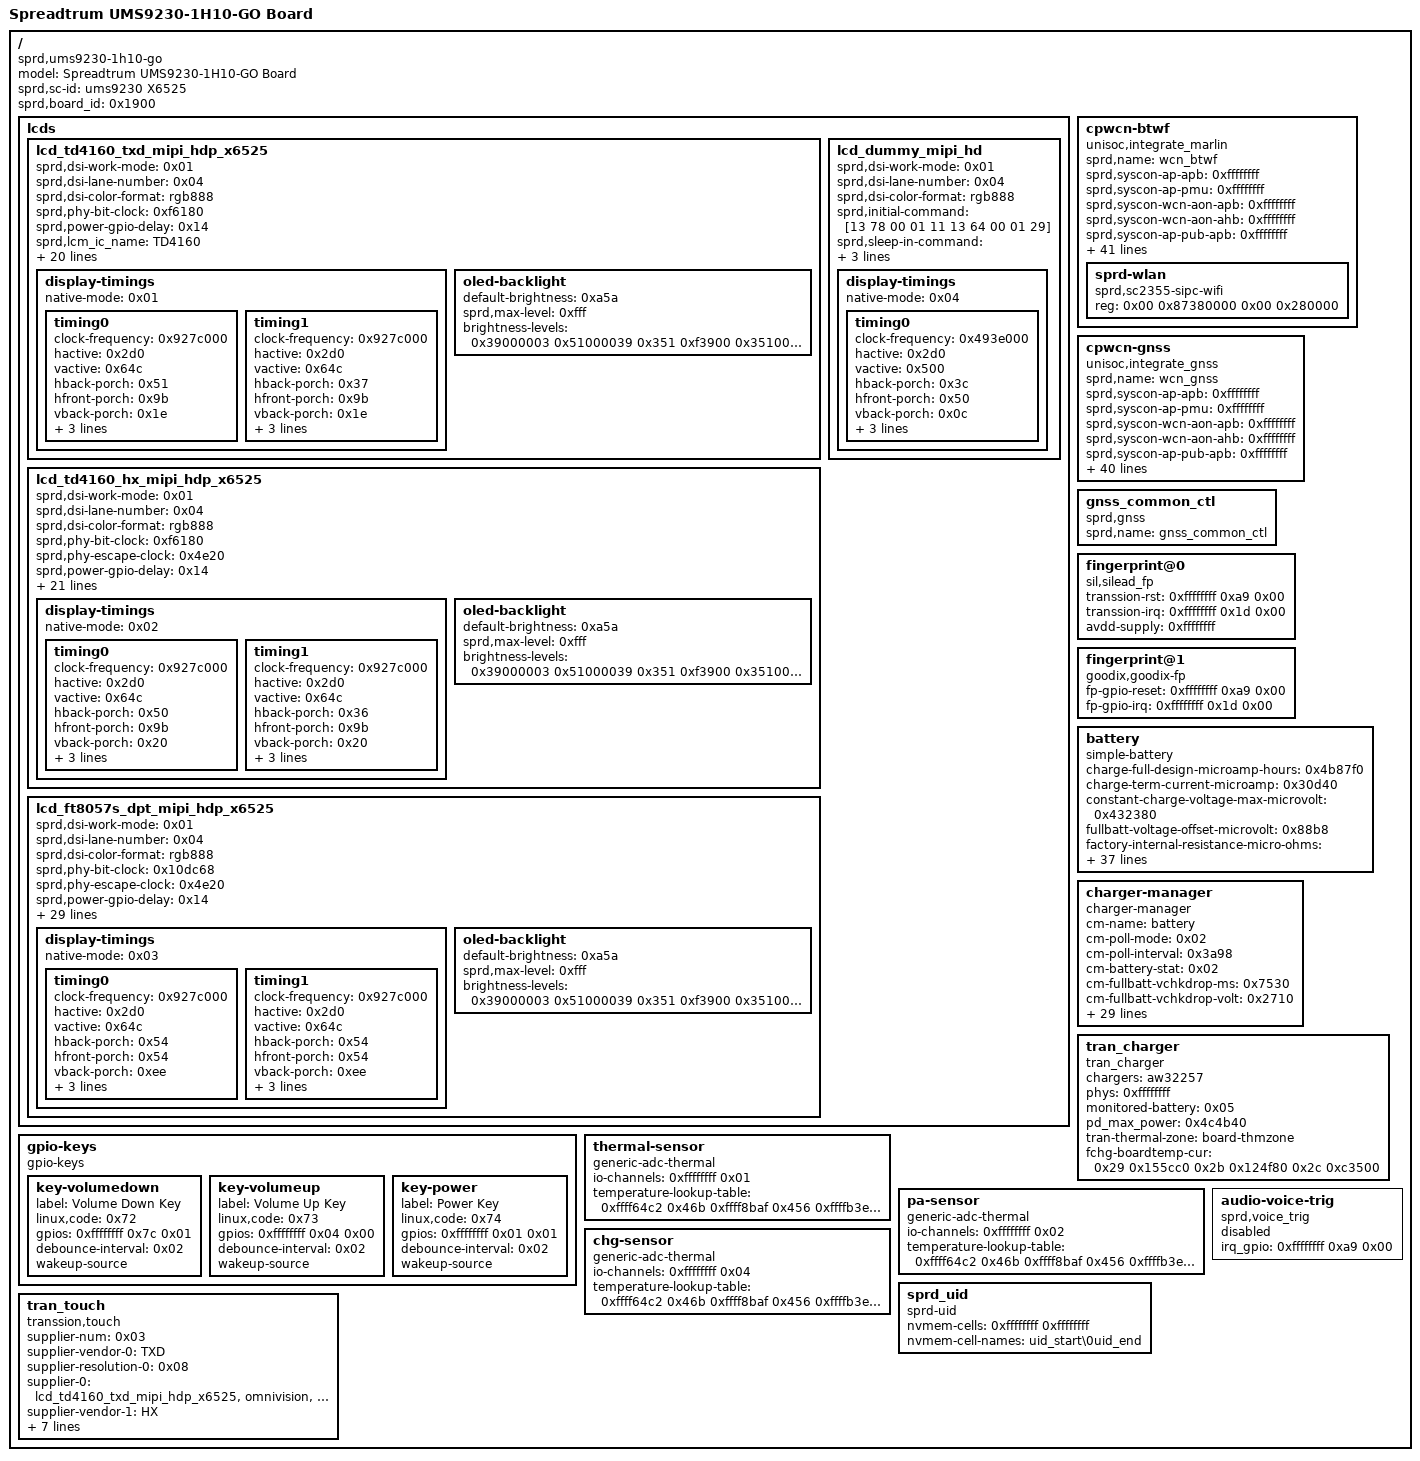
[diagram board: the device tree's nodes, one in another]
/dts-v1/;

/ {
	model = "Spreadtrum UMS9230-1H10-GO Board";
	compatible = "sprd,ums9230-1h10-go";
	sprd,sc-id = "ums9230 X6525";
	sprd,board_id = <0x1900>;

	fragment {
		target-path = "/";

		__overlay__ {
			#address-cells = <0x02>;
			#size-cells = <0x02>;

			lcds {

				lcd_td4160_txd_mipi_hdp_x6525 {
					sprd,dsi-work-mode = <0x01>;
					sprd,dsi-lane-number = <0x04>;
					sprd,dsi-color-format = "rgb888";
					sprd,phy-bit-clock = <0xf6180>;
					sprd,power-gpio-delay = <0x14>;
					sprd,lcm_ic_name = "TD4160";
					sprd,lcm_ic_vendor = "TXD";
					sprd,lcm_ic_inch = "6.56";
					sprd,width-mm = <0x44>;
					sprd,height-mm = <0x98>;
					sprd,esd-check-enable = <0x00>;
					sprd,esd-check-mode = <0x01>;
					sprd,esd-check-period = <0x7d0>;
					sprd,esd-check-register = <0x0a>;
					sprd,esd-check-value = <0x9c>;
					sprd,backlight-param-write = <0x01>;
					sprd,reset-on-sequence = <0x01 0x05 0x00 0x05 0x01 0x14>;
					sprd,reset-off-sequence = <0x00 0x05>;
					sprd,use-dcs-write;
					sprd,initial-command = [23 00 00 02 b0 00 39 00 00 07 b6 30 6a 00 86 c3 03 39 00 00 05 b7 31 00 00 00 39 00 00 07 b8 06 90 00 00 00 32 39 00 00 07 b9 06 90 00 00 00 80 39 00 00 07 ba 06 90 00 00 00 90 39 00 00 04 bb 00 b4 a0 39 00 00 04 bc 00 b4 a0 39 00 00 04 bd 00 b4 a0 39 00 00 0e be 07 00 00 00 00 00 00 00 00 00 00 00 00 39 00 00 19 c0 00 5a 22 06 4c 00 10 06 94 00 70 00 00 00 00 00 00 00 00 00 00 00 00 00 39 00 00 28 c1 30 81 50 fa 01 00 00 10 00 00 00 00 40 0f 00 00 00 00 00 00 00 00 00 00 00 00 00 00 00 00 00 00 00 00 00 00 00 00 00 39 00 00 f5 c2 04 c0 4c 14 05 10 08 00 00 00 00 00 00 00 00 00 00 00 00 00 00 00 00 00 00 00 00 00 00 00 00 00 00 00 00 00 00 00 00 00 00 00 04 c0 3d 0c 0c 05 00 41 00 46 69 03 00 64 00 00 00 00 00 11 00 00 00 00 00 00 00 00 00 00 00 00 04 c0 3d 0a 0a 05 00 01 66 a6 73 00 00 00 00 00 00 00 00 11 00 00 00 00 00 00 00 00 00 00 00 00 00 00 00 00 00 00 00 00 00 00 00 00 00 00 00 00 00 00 00 11 00 00 00 00 00 00 00 00 00 00 00 00 00 00 00 00 00 00 00 00 00 00 00 00 00 00 00 00 00 00 00 11 00 00 00 00 00 00 00 00 00 00 00 00 00 00 00 00 00 00 00 00 00 00 00 00 00 00 00 00 00 00 00 00 00 00 00 00 00 00 00 10 00 00 00 00 00 00 00 00 00 00 00 00 00 00 00 02 00 00 00 00 00 00 00 00 00 00 02 00 00 00 00 00 00 00 00 00 00 00 00 00 00 00 00 00 00 00 39 00 00 6a c3 00 00 00 c3 01 80 f8 3c f8 18 20 00 00 00 00 00 00 00 00 00 00 00 20 00 00 00 00 00 00 00 00 00 00 00 20 00 00 00 00 00 00 00 00 00 00 00 20 00 00 00 00 08 00 00 00 00 00 00 00 00 00 00 00 00 00 00 00 00 00 00 00 00 00 00 00 00 00 00 00 00 00 00 00 00 00 00 00 00 00 00 00 00 00 00 00 00 00 00 00 00 00 00 00 00 00 39 00 00 55 c4 00 07 07 2b 23 25 27 29 5d 61 13 15 17 19 1b 1d 03 05 00 00 00 00 00 00 00 00 00 00 06 04 1e 1c 1a 18 16 14 61 5d 2a 28 26 24 2c 07 07 00 00 00 00 00 00 00 00 00 00 00 00 00 00 00 00 00 00 00 00 00 00 00 00 00 00 00 00 55 55 55 55 55 55 55 55 55 55 55 39 00 00 06 c5 08 00 00 00 00 39 00 00 4d c6 00 00 00 00 01 22 04 22 01 00 5d 00 00 00 01 00 5d 00 01 05 01 0b 01 35 ff 8f 06 15 01 c0 0b 00 00 00 00 00 00 00 00 00 00 00 00 00 00 00 00 00 00 00 00 00 00 20 20 00 00 00 c0 11 00 00 00 10 10 00 00 00 01 00 50 00 33 03 00 00 39 00 00 1f cb 02 d0 01 80 00 00 00 00 00 00 00 00 00 00 00 00 00 00 00 00 00 00 40 70 00 00 00 00 00 ff 39 00 00 19 ce 5d 40 43 49 55 62 71 82 94 a8 b9 cb db e9 f5 fc ff 04 00 02 02 00 04 8c 23 00 00 02 cf 00 39 00 00 15 d0 c1 46 81 66 09 90 00 cc f2 ff 11 46 06 7e 09 08 cc 1b f0 06 39 00 00 26 d1 d4 d4 1b 33 33 17 07 bb 33 33 33 33 00 3b 77 07 3b 30 06 72 33 13 00 d7 0c 33 02 00 18 70 18 77 11 11 11 20 20 39 00 00 04 d2 00 00 00 39 00 00 9a d3 00 00 00 00 00 00 00 00 00 ff f7 ff ff f7 ff ff f7 ff ff f7 ff ff f7 ff ff f7 ff ff f7 ff ff f7 ff ff f7 ff ff f7 ff ff f7 ff ff f7 ff ff f7 ff ff f7 ff ff f7 ff ff f7 ff ff f7 ff ff f7 ff ff f7 ff ff f7 ff ff f7 ff ff f7 ff ff f7 ff ff f7 ff ff f7 ff ff f7 ff ff f7 ff ff f7 ff ff f7 ff ff f7 ff ff f7 ff ff f7 ff ff f7 ff ff f7 ff ff f7 ff ff f7 ff ff f7 ff ff f7 ff ff f7 ff ff f7 ff ff f7 ff ff f7 ff ff f7 ff ff f7 ff ff f7 ff ff f7 ff ff f7 ff ff f7 ff 39 00 00 18 d4 00 00 00 00 00 00 00 00 00 20 00 00 00 00 20 00 00 00 00 00 00 00 00 39 00 00 2f d7 29 00 12 12 00 5a 00 18 00 5a 00 18 03 83 80 85 85 85 87 84 45 86 87 80 88 86 89 83 83 87 84 88 8a 0c 0b 0a 0a 0a 07 07 06 06 00 08 0a 0a 39 00 00 17 d8 40 99 26 ed 16 6c 16 6c 16 6c 00 14 00 14 00 14 01 0c 00 00 01 00 39 00 00 29 d9 01 02 5e 00 00 20 00 00 00 00 00 00 00 00 00 c0 00 00 00 00 00 00 00 00 00 00 00 00 00 00 00 00 00 00 00 00 00 00 00 00 39 00 00 05 dd 30 06 23 65 39 00 00 0f de 00 00 00 0f ff 00 00 00 00 10 00 00 00 00 39 00 00 09 e6 00 00 00 00 00 00 00 00 39 00 00 24 ea 02 0e 0e 06 80 07 40 74 00 00 00 03 33 07 0a 00 5e 00 5e 00 5e 01 28 01 28 00 5e 00 5e 00 5e 00 0c 02 00 39 00 00 09 eb 09 00 90 00 01 00 01 01 39 00 00 18 ec 05 f0 01 70 6b 07 40 74 00 00 00 02 2a 00 00 00 00 00 00 00 00 00 00 39 00 00 22 ed 01 02 00 00 00 00 01 00 67 f7 0e 00 00 00 00 00 00 00 00 00 00 00 02 b0 00 00 00 00 00 00 c0 10 00 39 00 00 7a ee 05 00 55 00 c0 5f 00 c0 5f 00 00 03 00 00 03 00 c0 5f 00 00 00 00 00 c0 5f 00 00 00 00 00 00 03 00 00 00 00 00 00 03 00 00 00 00 00 00 03 00 c0 5f 00 00 00 00 00 00 03 00 00 00 00 00 00 03 00 00 00 00 00 00 03 00 00 00 00 00 00 03 00 00 03 00 00 03 00 00 03 00 00 03 00 00 03 00 00 03 00 00 00 00 00 00 00 00 00 00 00 00 00 00 00 00 00 00 00 00 00 00 00 00 00 02 23 00 00 02 b0 03 23 00 00 02 b0 04 23 00 00 02 b0 00 23 00 00 02 d6 00 23 00 00 02 b0 03 23 00 00 02 35 00 39 00 00 03 51 00 00 23 00 00 02 53 24 23 00 00 02 55 03 13 78 00 01 11 13 14 00 01 29];
					sprd,sleep-in-command = [39 14 00 03 28 00 00 39 78 00 03 10 00 00];
					sprd,sleep-out-command = [39 78 00 03 11 00 00 39 14 00 03 29 00 00];
					phandle = <0x13>;

					display-timings {
						native-mode = <0x01>;

						timing0 {
							clock-frequency = <0x927c000>;
							hactive = <0x2d0>;
							vactive = <0x64c>;
							hback-porch = <0x51>;
							hfront-porch = <0x9b>;
							vback-porch = <0x1e>;
							vfront-porch = <0x3fc>;
							hsync-len = <0x04>;
							vsync-len = <0x04>;
							phandle = <0x01>;
						};

						timing1 {
							clock-frequency = <0x927c000>;
							hactive = <0x2d0>;
							vactive = <0x64c>;
							hback-porch = <0x37>;
							hfront-porch = <0x9b>;
							vback-porch = <0x1e>;
							vfront-porch = <0xb4>;
							hsync-len = <0x04>;
							vsync-len = <0x04>;
							phandle = <0x14>;
						};
					};

					oled-backlight {
						default-brightness = <0xa5a>;
						sprd,max-level = <0xfff>;
						brightness-levels = <0x39000003 0x51000039 0x351 0xf3900 0x35100 0xf390000 0x351000f 0x39000003 0x51000f39 0x351 0xf3900 0x35100 0xf390000 0x351000f 0x39000003 0x51000f39 0x351 0xf3900 0x35100 0xf390000 0x351000f 0x39000003 0x51000f39 0x351 0xf3900 0x35100 0xf390000 0x351000f>;
					};
				};

				lcd_td4160_hx_mipi_hdp_x6525 {
					sprd,dsi-work-mode = <0x01>;
					sprd,dsi-lane-number = <0x04>;
					sprd,dsi-color-format = "rgb888";
					sprd,phy-bit-clock = <0xf6180>;
					sprd,phy-escape-clock = <0x4e20>;
					sprd,power-gpio-delay = <0x14>;
					sprd,lcm_ic_name = "TD4160";
					sprd,lcm_ic_vendor = "HX";
					sprd,lcm_ic_inch = "6.56";
					sprd,width-mm = <0x44>;
					sprd,height-mm = <0x98>;
					sprd,esd-check-enable = <0x00>;
					sprd,esd-check-mode = <0x01>;
					sprd,esd-check-period = <0x7d0>;
					sprd,esd-check-register = <0x0a>;
					sprd,esd-check-value = <0x9c>;
					sprd,backlight-param-write = <0x01>;
					sprd,reset-on-sequence = <0x01 0x05 0x00 0x05 0x01 0x14>;
					sprd,reset-off-sequence = <0x00 0x05>;
					sprd,use-dcs-write;
					sprd,initial-command = <0x23000002 0xb0003900 0x7b630 0x6a0086c3 0x3390000 0x5b73100 0x3900 0x7b806 0x90000000 0x32390000 0x7b90690 0x80 0x39000007 0xba069000 0x9039 0x4bb 0xb4a039 0x4bc 0xb4a039 0x4bd 0xb4a039 0xebe 0x7000000 0x00 0x00 0x390000 0x19c0005a 0x24064c00 0xa069400 0x70000000 0x00 0x00 0x3900 0x28c130 0x8150fa01 0x1000 0x40 0xf000000 0x00 0x00 0x00 0x00 0x00 0x3900 0xf5c205 0x304e1207 0x10141000 0x5304e12 0x7101210 0x00 0x00 0x00 0x00 0x00 0x00 0x53048 0x10100705 0xc100e002 0x08 0x00 0x1100e002 0x10000000 0x00 0x00 0x00 0x00 0x00 0x00 0x11000000 0x00 0x00 0x00 0x00 0x00 0x00 0x00 0x11000000 0x00 0x00 0x00 0x00 0x00 0x00 0x00 0x11000000 0x00 0x00 0x00 0x00 0x00 0x00 0x00 0x00 0x00 0x10000000 0x00 0x00 0x00 0x2000000 0x00 0x02 0x00 0x00 0x00 0x00 0x39 0x6ac3 0x5304ec1 0x1600c00 0x2000 0x5304ec1 0x1600c00 0x2002 0x5304ec1 0x1600c00 0x2001 0x5304ec1 0x1600c00 0x2000 0x08 0x00 0x00 0x00 0x00 0x00 0x00 0x00 0x00 0x00 0x00 0x00 0x00 0x00 0x390000 0x55c40000 0x5e610003 0x7131517 0x191b1d1f 0x215f6000 0x00 0x00 0x60 0x5f22201e 0x1c1a1816 0x14080400 0x615e0000 0x00 0xf00f00 0xff0000 0x00 0x00 0x00 0x55 0x55555555 0x55555555 0x55553900 0x6c508 0x00 0x3900004d 0xc6000000 0x12204 0x22010046 0x01 0x460001 0x5010b01 0x35ff0f06 0xc502c00f 0x00 0x00 0x00 0x00 0x00 0x2020 0xc0 0x11000000 0x10100000 0x10050 0x330300 0x390000 0x1fcb02d0 0x1800000 0x00 0x00 0x00 0x00 0x40700000 0xff 0x39000019 0xce5d4043 0x49556271 0x8294a8b9 0xcbdbe9f5 0xfcff0400 0x2020004 0x8c230000 0x2cf0039 0x15d0 0xc1328166 0x99000d5 0x929f1146 0x67e0908 0xdc1bf006 0x39000026 0xd1d8d81b 0x33331707 0xbb333333 0x33003b77 0x73b3006 0x72331300 0xd70c3302 0x187018 0x77111111 0x20203900 0x4d200 0x3900 0x9ad300 0x00 0x00 0xfff7ffff 0xf7fffff7 0xfffff7ff 0xfff7ffff 0xf7fffff7 0xfffff7ff 0xfff7ffff 0xf7fffff7 0xfffff7ff 0xfff7ffff 0xf7fffff7 0xfffff7ff 0xfff7ffff 0xf7fffff7 0xfffff7ff 0xfff7ffff 0xf7fffff7 0xfffff7ff 0xfff7ffff 0xf7fffff7 0xfffff7ff 0xfff7ffff 0xf7fffff7 0xfffff7ff 0xfff7ffff 0xf7fffff7 0xfffff7ff 0xfff7ffff 0xf7fffff7 0xfffff7ff 0xfff7ffff 0xf7fffff7 0xfffff7ff 0xfff7ffff 0xf7fffff7 0xfffff7ff 0x39000018 0xd4000000 0x00 0x2000 0x20 0x00 0x00 0x3900002f 0xd7010012 0x12005a00 0x18005a00 0x18038380 0x85858587 0x84858687 0x80888689 0x83838784 0x88900c0b 0xa0a0a07 0x7060600 0x80a0a39 0x17d8 0x409926ed 0x166c166c 0x166c0014 0x140014 0x10c0000 0x1003900 0x29d901 0x27f2200 0x140000 0x00 0xc000 0x00 0x00 0x00 0x00 0x00 0x39 0x5dd 0x30062365 0x3900000f 0xde000000 0xfff0000 0x1000 0x39 0x9e6 0x00 0x00 0x39000024 0xea020707 0x4801001 0x00 0x3230007 0xed00ed 0xed0128 0x1280047 0x470047 0x10f0100 0x39000009 0xeb083083 0x10100 0x390000 0x18ec02d0 0x1707310 0x1000000 0x22a00 0x00 0x00 0x390000 0x22ed0102 0x00 0x67c6 0xfe000000 0x00 0x00 0x2b00000 0x00 0x40100039 0x7aee 0x5400100 0xc03f00c0 0x3f000003 0x300 0xc03f0000 0x00 0x3000000 0x03 0x00 0x300 0x00 0x340c5 0x3f000000 0xc03f 0x00 0xc03f00 0x05 0xc03f0000 0x00 0x3000003 0x300 0x30000 0x3000003 0x300 0x00 0x00 0x00 0x00 0x00 0x00 0x2230000 0x2b00323 0x2b0 0x4230000 0x2d60039 0x351 0x2300 0x25324 0x23000002 0x55031378 0x11113 0x14000129>;
					sprd,sleep-in-command = [13 14 00 01 28 13 78 00 01 10];
					sprd,sleep-out-command = [13 78 00 01 11 13 14 00 01 29];
					phandle = <0x15>;

					display-timings {
						native-mode = <0x02>;

						timing0 {
							clock-frequency = <0x927c000>;
							hactive = <0x2d0>;
							vactive = <0x64c>;
							hback-porch = <0x50>;
							hfront-porch = <0x9b>;
							vback-porch = <0x20>;
							vfront-porch = <0x3fc>;
							hsync-len = <0x04>;
							vsync-len = <0x04>;
							phandle = <0x02>;
						};

						timing1 {
							clock-frequency = <0x927c000>;
							hactive = <0x2d0>;
							vactive = <0x64c>;
							hback-porch = <0x36>;
							hfront-porch = <0x9b>;
							vback-porch = <0x20>;
							vfront-porch = <0xb4>;
							hsync-len = <0x04>;
							vsync-len = <0x04>;
							phandle = <0x16>;
						};
					};

					oled-backlight {
						default-brightness = <0xa5a>;
						sprd,max-level = <0xfff>;
						brightness-levels = <0x39000003 0x51000039 0x351 0xf3900 0x35100 0xf390000 0x351000f 0x39000003 0x51000f39 0x351 0xf3900 0x35100 0xf390000 0x351000f 0x39000003 0x51000f39 0x351 0xf3900 0x35100 0xf390000 0x351000f 0x39000003 0x51000f39 0x351 0xf3900 0x35100 0xf390000 0x351000f>;
					};
				};

				lcd_ft8057s_dpt_mipi_hdp_x6525 {
					sprd,dsi-work-mode = <0x01>;
					sprd,dsi-lane-number = <0x04>;
					sprd,dsi-color-format = "rgb888";
					sprd,phy-bit-clock = <0x10dc68>;
					sprd,phy-escape-clock = <0x4e20>;
					sprd,power-gpio-delay = <0x14>;
					sprd,lcm_ic_name = "FT8057S";
					sprd,lcm_ic_vendor = "DPT";
					sprd,lcm_ic_inch = "6.56";
					sprd,width-mm = <0x44>;
					sprd,height-mm = <0x99>;
					sprd,esd-check-enable = <0x01>;
					sprd,esd-check-mode = <0x02>;
					sprd,esd-check-period = <0x7d0>;
					sprd,esd-check-num = <0x03>;
					sprd,esd-check-register = <0x0a 0x0d 0x0b>;
					sprd,esd-check-value = <0x9c 0x00 0x00>;
					sprd,backlight-param-write = <0x00>;
					sprd,reset-on-sequence = <0x01 0x05 0x00 0x05 0x01 0x14>;
					sprd,reset-off-sequence = <0x01 0x05>;
					sprd,need-shutdown = <0x01>;
					sprd,shutdown-sequence = <0x00 0x00 0x00 0x32 0x00 0x05 0x36 0x00 0x01 0x37 0x00 0x05>;
					sprd,use-dcs-write;
					sprd,initial-command = <0x23000002 0x3900 0x4ff80 0x57012300 0x20080 0x39000003 0xff805723 0x200 0x390000 0x52a0000 0x2cf2300 0x20000 0x39000005 0x2b000006 0x4b230000 0x200a339 0x5b3 0x64c0018 0x23000002 0x932300 0x2c575 0x23000002 0x972300 0x2c575 0x23000002 0x9a2300 0x2c541 0x23000002 0x9c2300 0x2c541 0x23000002 0xb63900 0x3c561 0x61230000 0x200b839 0x3c5 0x37372300 0x20000 0x39000003 0xd8333323 0x200 0x82230000 0x2c55523 0x200 0x83230000 0x2c50723 0x200 0x96230000 0x2f50d23 0x200 0x86230000 0x2f50d23 0x200 0x94230000 0x2c51523 0x200 0x9b230000 0x2c55123 0x200 0xa3230000 0x2a50423 0x200 0x99230000 0x2cf5623 0x200 0x86230000 0x2b78023 0x200 0xa5230000 0x2b01d23 0x200 0x80390000 0x7c000d2 0x2e001c 0x23000002 0x903900 0x7c000 0x7f002e00 0x1c230000 0x200a039 0x7c0 0xd2002e 0x1c2300 0x200b0 0x39000006 0xc0010f00 0x2e1c2300 0x200c1 0x39000009 0xc0013301 0xa00cd01 0x8f230000 0x2007039 0x7c0 0x7f002e 0x1c2300 0x200a3 0x39000007 0xc1003300 0x3c000223 0x200 0xb7390000 0x3c10033 0x23000002 0x733900 0x3ce09 0x9230000 0x2008039 0x11ce 0x1810909 0x780096 0x780096 0x780096 0x23000002 0x903900 0x10ce00 0xa5168f00 0xa5800909 0x7d016 0x16172300 0x200a0 0x39000004 0xce200000 0x23000002 0xb03900 0x4ce87 0x2300 0x200d1 0x39000008 0xce000001 0x00 0x23000002 0xe13900 0xcce08 0x3c303c3 0x2b00000 0x2300 0x200f1 0x3900000a 0xce14141e 0x1520152 0x1532300 0x200b0 0x39000005 0xcf00006d 0x71230000 0x200b539 0x5cf 0x3035b5f 0x23000002 0xc03900 0x5cf06 0x6474b23 0x200 0xc5390000 0x5cf0606 0x4b4f2300 0x20060 0x39000009 0xcf00006d 0x7103035b 0x5f230000 0x2007039 0x9cf 0x6569 0x3035357 0x23000002 0xaa3900 0x5cf80 0x801c1823 0x200 0xd1390000 0xdc103aa 0x5220959 0x5870823 0xfac2300 0x200e1 0x39000003 0xc1052223 0x200 0xe2390000 0xdcf06de 0x6dd06dd 0x6dd06dd 0x6dd2300 0x20080 0x39000003 0xc1000023 0x200 0x90230000 0x2c10123 0x200 0xf5230000 0x2cf0123 0x200 0xf6230000 0x2cf5a23 0x200 0xf1230000 0x2cf5a23 0x200 0xf7230000 0x2cf7123 0x200 0x390000 0x31f5a5a 0x23000002 0xd13900 0x8ce00 0xa010100 0xf1012300 0x200e8 0x39000005 0xce00f100 0xf1230000 0x2008039 0x11cc 0x261c2626 0x261d0100 0x7090b 0xd0f1103 0x23000002 0x903900 0x9cc05 0x23000000 0x23 0x200 0x80390000 0x11cd261c 0x2626261d 0x1000006 0x80a0c0e 0x10022300 0x20090 0x39000009 0xcd042200 0x00 0x230000 0x200a039 0x11cc 0x26261c26 0x261d0100 0x80610 0xe0c0a04 0x23000002 0xb03900 0x9cc02 0x22000000 0x23 0x200 0xa0390000 0x11cd2626 0x1c26261d 0x1000009 0x7110f0d 0xb052300 0x200b0 0x39000009 0xcd032300 0x00 0x230000 0x2008039 0x11cb 0xc1c1c1c1 0xc1c1c1c1 0xc1c1c1c1 0xc1c1c1c1 0x23000002 0xed2300 0x2cbc1 0x23000002 0x903900 0x11cb30 0x00 0x00 0x00 0x23 0x200 0xee230000 0x2cb0023 0x200 0x90230000 0x2c30023 0x200 0xa0390000 0x9cb0000 0x00 0x2300 0x200b0 0x39000005 0xcb555555 0x55230000 0x200c039 0x5cb 0x55555555 0x23000002 0xd23900 0xccb83 0x838300 0x83830083 0x83002300 0x200e0 0x3900000e 0xcb838300 0x83830083 0x83008383 0x832300 0x200fa 0x39000003 0xcb830023 0x200 0xef230000 0x2cb0023 0x200 0x68390000 0x5c29005 0x2300 0x2006c 0x39000005 0xc28f0500 0x230000 0x2007039 0x5c2 0x8e050000 0x23000002 0x743900 0x5c28d 0x5000023 0x200 0xea390000 0x9c21200 0x11080000 0x2300 0x2008c 0x39000006 0xc28a0415 0x9a9f2300 0x20091 0x39000006 0xc2890515 0x9a9f2300 0x20096 0x39000006 0xc2880615 0x9a9f2300 0x2009b 0x39000006 0xc2870715 0x9a9f2300 0x200a0 0x39000006 0xc2860015 0x9a9f2300 0x200a5 0x39000006 0xc2850015 0x9a9f2300 0x200aa 0x39000006 0xc2840015 0x9a9f2300 0x200af 0x39000006 0xc2830015 0x9a9f2300 0x200b4 0x39000006 0xc2820115 0x9a9f2300 0x200b9 0x39000006 0xc2810215 0x9a9f2300 0x200be 0x39000006 0xc2800315 0x9a9f2300 0x200c3 0x39000006 0xc2010415 0x9a9f2300 0x200dc 0x39000009 0xc2bbbbbb 0xbbbbbb00 0x230000 0x200e839 0x5c3 0x00 0x23000002 0xec3900 0x5c300 0x23 0x200 0xf9230000 0x2cb2023 0x200 0xfe230000 0x2cb0823 0x200 0xf8390000 0x4cd8c55 0x8b230000 0x200fc39 0x3cb 0x8402300 0x200fb 0x39000005 0xc3930893 0x8230000 0x2009823 0x2c4 0x8230000 0x2009039 0x6e9 0x10ffffff 0x230000 0x2008523 0x2c4 0x80230000 0x2008623 0x2a4 0xb6230000 0x2009523 0x2c4 0x80230000 0x2008123 0x2a4 0x73230000 0x200ca39 0x3c0 0x90112300 0x200b7 0x23000002 0xf51d2300 0x20090 0x23000002 0xc3002300 0x200b1 0x23000002 0xf5112300 0x200b0 0x23000002 0xc5002300 0x200b3 0x23000002 0xc5002300 0x200b2 0x23000002 0xc50d2300 0x200b5 0x23000002 0xc5022300 0x200c2 0x23000002 0xf5422300 0x20080 0x23000002 0xce002300 0x200d0 0x23000002 0xce012300 0x200e0 0x23000002 0xce002300 0x200a1 0x23000002 0xc1cc2300 0x200a6 0x23000002 0xc1e22300 0x20071 0x39000006 0xc0870103 0x1c2300 0x200b0 0x23000002 0xca012300 0x200b2 0x23000002 0xca0c2300 0x200b5 0x23000002 0xca042300 0x20000 0x39000004 0xff000000 0x23000002 0x803900 0x3ff00 0x390000 0x3510000 0x23000002 0x53242300 0x25500 0x23000002 0x35001378 0x11113 0x14000129>;
					sprd,sleep-in-command = [23 00 00 02 53 24 23 00 00 02 55 00 13 14 00 01 28 13 50 00 01 10 23 00 00 02 00 00 39 01 00 05 f7 5a a5 95 27];
					sprd,sleep-out-command = [13 78 00 01 11 13 14 00 01 29];
					sprd,oled-backlight-close = [39 00 00 03 51 00 00 23 00 00 02 53 24 23 00 00 02 55 00];
					sprd,dimming-enable-open = <0x23000002 0x532c2300 0x25503>;
					phandle = <0x17>;

					display-timings {
						native-mode = <0x03>;

						timing0 {
							clock-frequency = <0x927c000>;
							hactive = <0x2d0>;
							vactive = <0x64c>;
							hback-porch = <0x54>;
							hfront-porch = <0x54>;
							vback-porch = <0xee>;
							vfront-porch = <0x3e8>;
							hsync-len = <0x04>;
							vsync-len = <0x06>;
							phandle = <0x03>;
						};

						timing1 {
							clock-frequency = <0x927c000>;
							hactive = <0x2d0>;
							vactive = <0x64c>;
							hback-porch = <0x54>;
							hfront-porch = <0x54>;
							vback-porch = <0xee>;
							vfront-porch = <0x32>;
							hsync-len = <0x04>;
							vsync-len = <0x06>;
							phandle = <0x18>;
						};
					};

					oled-backlight {
						default-brightness = <0xa5a>;
						sprd,max-level = <0xfff>;
						brightness-levels = <0x39000003 0x51000039 0x351 0xf3900 0x35100 0xf390000 0x351000f 0x39000003 0x51000f39 0x351 0xf3900 0x35100 0xf390000 0x351000f 0x39000003 0x51000f39 0x351 0xf3900 0x35100 0xf390000 0x351000f 0x39000003 0x51000f39 0x351 0xf3900 0x35100 0xf390000 0x351000f>;
					};
				};

				lcd_dummy_mipi_hd {
					sprd,dsi-work-mode = <0x01>;
					sprd,dsi-lane-number = <0x04>;
					sprd,dsi-color-format = "rgb888";
					sprd,initial-command = [13 78 00 01 11 13 64 00 01 29];
					sprd,sleep-in-command = [13 0a 00 01 28 13 78 00 01 10];
					sprd,sleep-out-command = [13 78 00 01 11 13 64 00 01 29];
					phandle = <0x19>;

					display-timings {
						native-mode = <0x04>;

						timing0 {
							clock-frequency = <0x493e000>;
							hactive = <0x2d0>;
							vactive = <0x500>;
							hback-porch = <0x3c>;
							hfront-porch = <0x50>;
							vback-porch = <0x0c>;
							vfront-porch = <0x26>;
							hsync-len = <0x3c>;
							vsync-len = <0x04>;
							phandle = <0x04>;
						};
					};
				};
			};

			cpwcn-btwf {
				compatible = "unisoc,integrate_marlin";
				sprd,name = "wcn_btwf";
				sprd,syscon-ap-apb = <0xffffffff>;
				sprd,syscon-ap-pmu = <0xffffffff>;
				sprd,syscon-wcn-aon-apb = <0xffffffff>;
				sprd,syscon-wcn-aon-ahb = <0xffffffff>;
				sprd,syscon-ap-pub-apb = <0xffffffff>;
				sprd,syscon-wcn-btwf-ahb = <0xffffffff>;
				sprd,ctrl-probe-num = <0x01>;
				sprd,ctrl-reg = <0x9018 0x23a8 0x2818 0x23a8 0x90 0x98 0x0c 0x1410 0x4c 0x0c>;
				sprd,ctrl-mask = <0x3fff 0x2000000 0x80 0x1000000 0x40000000 0x100f 0x55 0x3000000 0xffffffff 0x55>;
				sprd,ctrl-value = <0x70 0x2000000 0x80 0x1000000 0x40000000 0x00 0x55 0x3000000 0x7fdc00 0x00>;
				sprd,ctrl-rw-offset = <0x1000 0x2000 0x2000 0x2000 0x00 0x00 0x00 0x1000 0x00 0x00>;
				sprd,ctrl-us-delay = <0x3e8 0x3e8 0x3e8 0x7d0 0x3e8 0x3e8 0x3e8 0x3e8 0x3e8 0x3e8>;
				sprd,ctrl-type = <0x02 0x01 0x01 0x01 0x0a 0x0a 0x09 0x07 0x09 0x09>;
				sprd,ctrl-shutdown-reg = <0x98>;
				sprd,ctrl-shutdown-mask = <0x1000>;
				sprd,ctrl-shutdown-value = <0x1000>;
				sprd,ctrl-shutdown-rw-offset = <0x00>;
				sprd,ctrl-shutdown-us-delay = <0x0a>;
				sprd,ctrl-shutdown-type = <0x0a>;
				reg = <0x00 0x87000000 0x00 0x200000 0x00 0x7c00a000 0x00 0x74>;
				sprd,debugbus-to-ddr-disable;
				sprd,wcn-pm-qos-enable;
				sprd,file-name = "/dev/block/platform/soc/soc:ap-apb/201d0000.sdio/by-name/wcnmodem";
				sprd,file-name-ufs = "/dev/block/platform/soc/soc:ap-apb/20200000.ufs/by-name/wcnmodem";
				sprd,firmware-path = "/vendor/firmware/";
				sprd,file-length = <0x200000>;
				sprd,rstpad-setting = <0x02>;
				sprd,apcp-sync-addr = <0x7fdc00>;
				sprd,wcn-sipc-ver = <0x01>;
				vddwcn-supply = <0xffffffff>;
				dcxo1v8-supply = <0xffffffff>;
				vddwifipa-supply = <0xffffffff>;
				merlion-chip-en-gpios = <0xffffffff 0x76 0x00>;
				merlion-rst-gpios = <0xffffffff 0x75 0x00>;
				xtal-26m-type-sel-gpios = <0xffffffff 0xad 0x00>;
				nvmem-cells = <0xffffffff>;
				nvmem-cell-names = "wcn_efuse_blk0";
				#address-cells = <0x02>;
				#size-cells = <0x02>;
				phandle = <0x1a>;

				sprd-wlan {
					compatible = "sprd,sc2355-sipc-wifi";
					reg = <0x00 0x87380000 0x00 0x280000>;
				};
			};

			cpwcn-gnss {
				compatible = "unisoc,integrate_gnss";
				sprd,name = "wcn_gnss";
				sprd,syscon-ap-apb = <0xffffffff>;
				sprd,syscon-ap-pmu = <0xffffffff>;
				sprd,syscon-wcn-aon-apb = <0xffffffff>;
				sprd,syscon-wcn-aon-ahb = <0xffffffff>;
				sprd,syscon-ap-pub-apb = <0xffffffff>;
				sprd,syscon-wcn-gnss-ahb = <0xffffffff>;
				sprd,ctrl-probe-num = <0x01>;
				sprd,ctrl-reg = <0x9018 0x23a8 0x2818 0x23a8 0x90 0xc8 0x0c 0x1404 0x50 0x0c>;
				sprd,ctrl-mask = <0x3fff 0x2000000 0x80 0x1000000 0x40000000 0x100f 0x22 0x1ffffff 0xffffffff 0x22>;
				sprd,ctrl-value = <0x70 0x2000000 0x80 0x1000000 0x40000000 0x00 0x22 0x1600000 0x1ffc00 0x00>;
				sprd,ctrl-rw-offset = <0x1000 0x2000 0x2000 0x2000 0x00 0x00 0x00 0x1000 0x00 0x00>;
				sprd,ctrl-us-delay = <0x3e8 0x3e8 0x3e8 0x7d0 0x3e8 0x3e8 0x3e8 0x3e8 0x3e8 0x3e8>;
				sprd,ctrl-type = <0x02 0x01 0x01 0x01 0x0a 0x0a 0x09 0x08 0x09 0x09>;
				sprd,ctrl-shutdown-reg = <0xc8>;
				sprd,ctrl-shutdown-mask = <0x1000>;
				sprd,ctrl-shutdown-value = <0x1000>;
				sprd,ctrl-shutdown-rw-offset = <0x00>;
				sprd,ctrl-shutdown-us-delay = <0x0a>;
				sprd,ctrl-shutdown-type = <0x0a>;
				reg = <0x00 0x87600000 0x00 0x180000>;
				sprd,file-name = "/dev/block/platform/soc/soc:ap-apb/201d0000.sdio/by-name/gnssmodem";
				sprd,file-name-ext = "/dev/block/platform/soc/soc:ap-apb/201d0000.sdio/by-name/gnssmodem";
				sprd,file-name-ufs = "/dev/block/platform/soc/soc:ap-apb/20200000.ufs/by-name/gnssmodem";
				sprd,file-name-ext-ufs = "/dev/block/platform/soc/soc:ap-apb/20200000.ufs/by-name/gnssmodem";
				sprd,file-length = <0x180000>;
				sprd,rstpad-setting = <0x02>;
				sprd,apcp-sync-addr = <0x1ffc00>;
				sprd,wcn-sipc-ver = <0x01>;
				vddwcn-supply = <0xffffffff>;
				dcxo1v8-supply = <0xffffffff>;
				merlion-chip-en-gpios = <0xffffffff 0x76 0x00>;
				merlion-rst-gpios = <0xffffffff 0x75 0x00>;
				xtal-26m-type-sel-gpios = <0xffffffff 0xad 0x00>;
				#address-cells = <0x01>;
				#size-cells = <0x01>;
				nvmem-cells = <0xffffffff>;
				nvmem-cell-names = "gnss_efuse_blk0";
				phandle = <0x1b>;
			};

			gnss_common_ctl {
				compatible = "sprd,gnss";
				sprd,name = "gnss_common_ctl";
			};

			fingerprint@0 {
				compatible = "sil,silead_fp";
				transsion-rst = <0xffffffff 0xa9 0x00>;
				transsion-irq = <0xffffffff 0x1d 0x00>;
				avdd-supply = <0xffffffff>;
			};

			fingerprint@1 {
				compatible = "goodix,goodix-fp";
				fp-gpio-reset = <0xffffffff 0xa9 0x00>;
				fp-gpio-irq = <0xffffffff 0x1d 0x00>;
			};

			gpio-keys {
				compatible = "gpio-keys";

				key-volumedown {
					label = "Volume Down Key";
					linux,code = <0x72>;
					gpios = <0xffffffff 0x7c 0x01>;
					debounce-interval = <0x02>;
					wakeup-source;
				};

				key-volumeup {
					label = "Volume Up Key";
					linux,code = <0x73>;
					gpios = <0xffffffff 0x04 0x00>;
					debounce-interval = <0x02>;
					wakeup-source;
				};

				key-power {
					label = "Power Key";
					linux,code = <0x74>;
					gpios = <0xffffffff 0x01 0x01>;
					debounce-interval = <0x02>;
					wakeup-source;
				};
			};

			battery {
				compatible = "simple-battery";
				charge-full-design-microamp-hours = <0x4b87f0>;
				charge-term-current-microamp = <0x30d40>;
				constant-charge-voltage-max-microvolt = <0x432380>;
				fullbatt-voltage-offset-microvolt = <0x88b8>;
				factory-internal-resistance-micro-ohms = <0x222e0>;
				voltage-min-design-microvolt = <0x34a490>;
				fast-charge-threshold-microvolt = <0x3e8fa0>;
				fullbatt-voltage = <0x428740>;
				fullbatt-current = <0x30d40>;
				first-fullbatt-current = <0x55730>;
				fullbatt-track-end-vol = <0x418958>;
				fullbatt-track-end-cur = <0x1fbd0>;
				first-calib-voltage = <0x3567e0>;
				first-calib-capacity = <0x14>;
				ocv-capacity-celsius = <0x14>;
				ocv-capacity-table-0 = <0x42d560 0x64 0x41cbc0 0x5f 0x40d1c0 0x5a 0x3ff318 0x55 0x3f1858 0x50 0x3e4568 0x4b 0x3d7a48 0x46 0x3caf28 0x41 0x3c12e8 0x3c 0x3b20b8 0x37 0x3a9418 0x32 0x3a2e88 0x2d 0x39e838 0x28 0x39ada0 0x23 0x398e60 0x1e 0x396750 0x19 0x3928d0 0x14 0x38cb10 0x0f 0x3832b8 0x0a 0x374858 0x05 0x33e140 0x00>;
				voltage-temp-table = <0x23df98 0x320 0x2260c8 0x352 0x20b318 0x384 0x1eda70 0x3b6 0x1ce670 0x3e8 0x1adb00 0x41a 0x18bff0 0x44c 0x16a0f8 0x47e 0x148db8 0x4b0 0x128e00 0x4e2 0x10a5b8 0x514 0xee098 0x546 0xd32e8 0x578 0xbb800 0x5aa 0xa50a0 0x5dc 0x91ff0 0x60e 0x802c8 0x640 0x71480 0x672>;
				capacity-temp-table = <0x32 0x64 0x19 0x64 0x0a 0x60 0x00 0x3c 0xfffffff6 0x32>;
				resistance-temp-table = <0x32 0x50 0x19 0x64 0x0a 0xa8 0x00 0x1a5 0xfffffff6 0x2b0>;
				charge-sdp-current-microamp = <0x7a120 0x7a120>;
				charge-dcp-current-microamp = <0x1e8480 0x1e8480>;
				charge-cdp-current-microamp = <0x16e360 0x16e360>;
				charge-pd-current-microamp = <0x1e8480 0x1e8480>;
				charge-unknown-current-microamp = <0x16e360 0x16e360>;
				cap-calib-energy-density-ocv-table = <0x331df0 0x39fbc0 0x3f52f0 0x426030>;
				dcp-jeita-temp-table = <0x3e8 0x406 0x00 0x432380 0x47e 0x49c 0xdbba0 0x432380 0x5aa 0x596 0x1e8480 0x432380 0x60e 0x5dc 0x16e360 0x3e8fa0>;
				sdp-jeita-temp-table = <0x3e8 0x406 0x00 0x432380 0x47e 0x49c 0x7a120 0x432380 0x5aa 0x596 0x7a120 0x432380 0x60e 0x5dc 0x7a120 0x3e8fa0>;
				cdp-jeita-temp-table = <0x3e8 0x406 0x00 0x432380 0x47e 0x49c 0xaae60 0x432380 0x5aa 0x596 0x16e360 0x432380 0x60e 0x5dc 0xaae60 0x3e8fa0>;
				fchg-pd-jeita-temp-table = <0x3e8 0x406 0x00 0x432380 0x47e 0x49c 0xdbba0 0x432380 0x5aa 0x596 0x1e8480 0x432380 0x60e 0x5e6 0x16e360 0x432380>;
				unknown-jeita-temp-table = <0x3e8 0x406 0x00 0x432380 0x47e 0x49c 0xaae60 0x432380 0x5aa 0x596 0x16e360 0x432380 0x60e 0x5dc 0xaae60 0x3e8fa0>;
				phandle = <0x05>;
			};

			charger-manager {
				status = "okay";
				compatible = "charger-manager";
				cm-name = "battery";
				cm-poll-mode = <0x02>;
				cm-poll-interval = <0x3a98>;
				cm-battery-stat = <0x02>;
				cm-fullbatt-vchkdrop-ms = <0x7530>;
				cm-fullbatt-vchkdrop-volt = <0x2710>;
				cm-fullbatt-capacity = <0x64>;
				call-limit;
				call-limit-cur = "\0\f5";
				cm-num-chargers = <0x01>;
				cm-chargers = "tran_charger";
				cm-fuel-gauge = "sc27xx-fgu";
				cm-battery-cold = <0xc8>;
				cm-battery-cold-in-minus;
				cm-battery-hot = <0x320>;
				cm-battery-temp-diff = <0x32>;
				cm-charging-max = <0x2932e00>;
				cm-discharging-max = <0x2932e0>;
				cm-wdt-interval = <0x3c>;
				cm-shutdown-voltage = <0x2f4d60>;
				cm-tickle-time-out = <0x5dc>;
				cm-one-cap-time = <0x1e>;
				cm-thermal-zone = "board-thmzone";
				cm-charge-voltage-max = <0x5e9ac0>;
				cm-charge-voltage-drop = <0x30d40>;
				cm-cap-remap-table = <0x01 0x02 0x03 0x02 0x03 0x02 0x62 0x63 0x02 0x63 0x64 0x03>;
				sprd,support-fchg;
				sprd,pd-fixed-max-microwatt = <0x4c4b40>;
				sprd,customized-fchg-psy = "tran_charger";
				monitored-battery = <0x05>;
				cm-keep-awake;
				phys = <0xffffffff>;
				extcon = <0xffffffff 0xffffffff>;
				pd-extcon-enable;
			};

			tran_charger {
				compatible = "tran_charger";
				chargers = "aw32257";
				phys = <0xffffffff>;
				monitored-battery = <0x05>;
				pd_max_power = <0x4c4b40>;
				tran-thermal-zone = "board-thmzone";
				fchg-boardtemp-cur = <0x29 0x155cc0 0x2b 0x124f80 0x2c 0xc3500>;
				phandle = <0x1c>;
			};

			thermal-sensor {
				compatible = "generic-adc-thermal";
				#thermal-sensor-cells = <0x00>;
				io-channels = <0xffffffff 0x01>;
				io-channel-names = "sensor-channel";
				temperature-lookup-table = <0xffff64c2 0x46b 0xffff8baf 0x456 0xffffb3e8 0x432 0xffffedb9 0x3d7 0x277e 0x346 0x60e5 0x28e 0xaf7a 0x19d 0xd677 0x13c 0xfd7f 0xee 0x12484 0xb2 0x14b93 0x85 0x172a3 0x64 0x199b0 0x4b 0x1c0c9 0x39 0x1e7c8 0x2b>;
				phandle = <0x08>;
			};

			pa-sensor {
				compatible = "generic-adc-thermal";
				#thermal-sensor-cells = <0x00>;
				io-channels = <0xffffffff 0x02>;
				io-channel-names = "sensor-channel";
				temperature-lookup-table = <0xffff64c2 0x46b 0xffff8baf 0x456 0xffffb3e8 0x432 0xffffedb9 0x3d7 0x277e 0x346 0x60e5 0x28e 0xaf7a 0x19d 0xd677 0x13c 0xfd7f 0xee 0x12484 0xb2 0x14b93 0x85 0x172a3 0x64 0x199b0 0x4b 0x1c0c9 0x39 0x1e7c8 0x2b>;
				phandle = <0x06>;
			};

			chg-sensor {
				compatible = "generic-adc-thermal";
				#thermal-sensor-cells = <0x00>;
				io-channels = <0xffffffff 0x04>;
				io-channel-names = "sensor-channel";
				temperature-lookup-table = <0xffff64c2 0x46b 0xffff8baf 0x456 0xffffb3e8 0x432 0xffffedb9 0x3d7 0x277e 0x346 0x60e5 0x28e 0xaf7a 0x19d 0xd677 0x13c 0xfd7f 0xee 0x12484 0xb2 0x14b93 0x85 0x172a3 0x64 0x199b0 0x4b 0x1c0c9 0x39 0x1e7c8 0x2b>;
				phandle = <0x07>;
			};

			audio-voice-trig {
				status = "disable";
				compatible = "sprd,voice_trig";
				irq_gpio = <0xffffffff 0xa9 0x00>;
			};

			sprd_uid {
				compatible = "sprd-uid";
				nvmem-cells = <0xffffffff 0xffffffff>;
				nvmem-cell-names = "uid_start\0uid_end";
			};

			tran_touch {
				compatible = "transsion,touch";
				supplier-num = <0x03>;
				supplier-vendor-0 = "TXD";
				supplier-resolution-0 = <0x08>;
				supplier-0 = "lcd_td4160_txd_mipi_hdp_x6525, omnivision, td4160";
				supplier-vendor-1 = "HX";
				supplier-resolution-1 = <0x08>;
				supplier-1 = "lcd_td4160_hx_mipi_hdp_x6525, omnivision, td4160";
				supplier-vendor-2 = "DPT";
				supplier-2 = "lcd_ft8057s_dpt_mipi_hdp_x6525, focaltech, ft8057s";
				supplier-resolution-2 = <0x08>;
			};
		};
	};

	fragment@0 {
		target = <0xffffffff>;

		__overlay__ {
			#address-cells = <0x01>;
			#size-cells = <0x00>;

			core@3 {
				compatible = "sprd,sipc";
				reg = <0x03>;
				label = "sipc-wcn";
				mboxes = <0xffffffff 0x08 0x00>;
				sprd,smem-info = <0x87240000 0x240000 0x140000>;
				phandle = <0x1d>;

				wcn_bt {
					compatible = "sprd,wcn_internal_chip";
					sprd,name = "ttyBT";
					sprd,dst = <0x03>;
					sprd,channel = <0x04>;
					sprd,tx_bufid = <0x0b>;
					sprd,rx_bufid = <0x0a>;
				};

				wcn_fm {
					compatible = "sprd,wcn_fm_internal_chip";
					sprd,name = "fm";
					sprd,dst = <0x03>;
					sprd,tx_channel = <0x04>;
					sprd,rx_channel = <0x04>;
					sprd,tx_bufid = <0x0e>;
					sprd,rx_bufid = <0x0d>;
					sprd,hp_lna_gpio = <0xffffffff 0x35 0x00>;
					phandle = <0x1e>;
				};
			};

			core@4 {
				compatible = "sprd,sipc";
				#address-cells = <0x01>;
				#size-cells = <0x00>;
				reg = <0x04>;
				label = "sipc-gnss";
				mboxes = <0xffffffff 0x09 0x00>;
				sprd,smem-info = <0x8749b000 0x11b000 0x32000>;
				phandle = <0x1f>;

				channel@4 {
					compatible = "sprd,spipe";
					reg = <0x04>;
					label = "sttygnss0";
					sprd,ringnr = <0x01>;
					sprd,size-rxbuf = <0x19000>;
					sprd,size-txbuf = <0xc800>;
					phandle = <0x20>;
				};
			};
		};
	};

	fragment@1 {
		target = <0xffffffff>;

		__overlay__ {
			bootargs_ext = "androidboot.hardware=X6525 androidboot.dtbo_idx=0";
			transsion,emi-support = "BWCTAKJ21X128G\0FEUDNN064G_C2G07\0YMUS8B2TE2A2C1\0YMUS7B2TE1A2C1\0FEUDNN128G_C2H14\0CBE06_64G0CHAC\0CBE06_1280CHAC\0CBE06_2560CHAC\0FEUDNN128G-C2Y20\0FEUDNN064G-C2Y20\0HN8G962EHKX037\0HAC09-64G0BRAC\0FEMDNN064G-A3A56\0HAC09-1280BRAC\0FEMDNN128G-A3A56\0BWCTARV11X64G";
		};
	};

	fragment@2 {
		target = <0xffffffff>;

		__overlay__ {
			#address-cells = <0x02>;
			#size-cells = <0x02>;

			wcn-mem@87000000 {
				reg = <0x00 0x87000000 0x00 0x800000>;
				phandle = <0x21>;
			};

			logobuffer@9e000000 {
				reg = <0x00 0x9e000000 0x00 0xab0000>;
				phandle = <0x0a>;
			};

			faceid-mem@ffa70000 {
				reg = <0x00 0xffa70000 0x00 0x500000>;
				phandle = <0x12>;
			};
		};
	};

	fragment@3 {
		target = <0xffffffff>;

		__overlay__ {

			pa-thmzone {
				polling-delay-passive = <0x00>;
				polling-delay = <0x00>;
				thermal-sensors = <0x06>;
				phandle = <0x22>;
			};

			chg-thmzone {
				polling-delay-passive = <0x00>;
				polling-delay = <0x00>;
				thermal-sensors = <0x07>;
				phandle = <0x23>;
			};

			board-thmzone {
				polling-delay-passive = <0x00>;
				polling-delay = <0x00>;
				thermal-sensors = <0x08>;
				phandle = <0x24>;
			};
		};
	};

	fragment@4 {
		target = <0xffffffff>;

		__overlay__ {
			status = "okay";
			clock-frequency = <0x61a80>;
			#address-cells = <0x01>;
			#size-cells = <0x00>;

			sensor-main@20 {
				compatible = "sprd,sensor-main";
				reg = <0x20>;
				clock-names = "clk_src\0sensor_eb\0clk_96m\0clk_76m8\0clk_48m\0clk_26m";
				clocks = <0xffffffff 0x02 0xffffffff 0x0d 0xffffffff 0x04 0xffffffff 0x10 0xffffffff 0x05 0xffffffff>;
				vddio-supply = <0xffffffff>;
				vddcama-supply = <0xffffffff>;
				vddcamd-supply = <0xffffffff>;
				vddcammot-supply = <0xffffffff>;
				reset-gpios = <0xffffffff 0x2c 0x00>;
				power-down-gpios = <0xffffffff 0x2e 0x00>;
				sprd,phyid = <0x02>;
				csi = <0xffffffff>;
				power-domains = <0xffffffff>;
				phandle = <0x25>;
			};
		};
	};

	fragment@5 {
		target = <0xffffffff>;

		__overlay__ {
			status = "okay";
			clock-frequency = <0x61a80>;
			#address-cells = <0x01>;
			#size-cells = <0x00>;

			sensor-sub@5a {
				compatible = "sprd,sensor-sub";
				reg = <0x5a>;
				clock-names = "clk_src\0sensor_eb\0clk_96m\0clk_76m8\0clk_48m\0clk_26m";
				clocks = <0xffffffff 0x03 0xffffffff 0x0c 0xffffffff 0x04 0xffffffff 0x10 0xffffffff 0x05 0xffffffff>;
				vddio-supply = <0xffffffff>;
				vddcama-supply = <0xffffffff>;
				vddcamd-supply = <0xffffffff>;
				reset-gpios = <0xffffffff 0x29 0x00>;
				power-down-gpios = <0xffffffff 0x28 0x00>;
				sprd,phyid = <0x00>;
				csi = <0xffffffff>;
				power-domains = <0xffffffff>;
				phandle = <0x26>;
			};

			sensor-main2@20 {
				compatible = "sprd,sensor-main2";
				reg = <0x20>;
				clock-names = "clk_src\0sensor_eb\0clk_96m\0clk_76m8\0clk_48m\0clk_26m";
				clocks = <0xffffffff 0x04 0xffffffff 0x0b 0xffffffff 0x04 0xffffffff 0x10 0xffffffff 0x05 0xffffffff>;
				vddcama-supply = <0xffffffff>;
				fakeserial-gpios = <0xffffffff 0x7e 0x00>;
				sprd,phyid = <0x03>;
				csi = <0xffffffff>;
				power-domains = <0xffffffff>;
				phandle = <0x27>;
			};
		};
	};

	fragment@6 {
		target = <0xffffffff>;

		__overlay__ {
			status = "okay";
			clock-frequency = <0x61a80>;
			#address-cells = <0x01>;
			#size-cells = <0x00>;

			flash-ic@63 {
				compatible = "sprd,flash-aw36515";
				flash-ic = <0x8ea3>;
				reg = <0x63>;
				flash-idx = <0x04>;
				phandle = <0x28>;
			};

			flash_ic_ocp81375@64 {
				compatible = "sprd,flash-ocp81375";
				flash-ic = <0x13ddf>;
				reg = <0x64>;
				flash-torch-en-gpios = <0xffffffff 0x89 0x00>;
				flash-idx = <0x04>;
				phandle = <0x29>;
			};
		};
	};

	fragment@7 {
		target = <0xffffffff>;

		__overlay__ {
			status = "okay";
			clock-frequency = <0x61a80>;
			#address-cells = <0x01>;
			#size-cells = <0x00>;
		};
	};

	fragment@8 {
		target = <0xffffffff>;

		__overlay__ {
			vdd-supply = <0xffffffff>;
			extcon = <0xffffffff>;
			sprd,hsphy-device-eye-pattern = <0x6f3d1c0>;
			sprd,hsphy-host-eye-pattern = <0x6f3d1c0>;
			status = "okay";
		};
	};

	fragment@9 {
		target = <0xffffffff>;

		__overlay__ {
			extcon = <0xffffffff 0xffffffff>;
			vbus-supply = <0x09>;
			status = "okay";
		};
	};

	fragment@10 {
		target = <0xffffffff>;

		__overlay__ {
			cd-gpios = <0xffffffff 0x23 0x00>;
		};
	};

	fragment@11 {
		target = <0xffffffff>;

		__overlay__ {
			status = "okay";
			#address-cells = <0x01>;
			#size-cells = <0x00>;

			sec-nfc@27 {
				compatible = "sec-nfc";
				reg = <0x27>;
				clock-names = "nfc_clk\0source\0enable";
				clocks = <0xffffffff 0x04 0xffffffff 0xffffffff 0x06>;
				sec-nfc,ven-gpio = <0xffffffff 0x3f 0x00>;
				sec-nfc,firm-gpio = <0xffffffff 0x3d 0x00>;
				sec-nfc,irq-gpio = <0xffffffff 0x3e 0x00>;
				sec-nfc,clk-req = <0xffffffff 0x3c 0x00>;
			};
		};
	};

	fragment@12 {
		target = <0xffffffff>;

		__overlay__ {
			status = "okay";
			#address-cells = <0x01>;
			#size-cells = <0x00>;

			aw32257@6a {
				compatible = "awinic,aw32257";
				status = "okay";
				reg = <0x6a>;
				phys = <0xffffffff>;
				monitored-battery = <0x05>;
				extcon = <0xffffffff>;
				charge,chg-pd-gpio = <0xffffffff 0x73 0x00>;
				ti,current-limit = <0x186a0>;
				ti,weak-battery-voltage = <0xd48>;
				ti,battery-regulation-voltage = <0x1130>;
				ti,charge-current = <0x9eb10>;
				ti,termination-current = <0xea60>;
				ti,resistor-sense = <0x38>;
				phandle = <0x2a>;

				otg-vbus {
					regulator-name = "otg-vbus";
					phandle = <0x09>;
				};
			};
		};
	};

	fragment@13 {
		target = <0xffffffff>;

		__overlay__ {
			status = "okay";
			#address-cells = <0x01>;
			#size-cells = <0x00>;

			vl53l0@52 {
				compatible = "st,stmvl53l0";
				reg = <0x52>;
				reset_gpios = <0xa8>;
				irq_gpios = <0xa9>;
				interrupt-parent = <0xffffffff>;
				interrupts = <0xa9 0x08>;
				phandle = <0x2b>;
			};
		};
	};

	fragment@14 {
		target = <0xffffffff>;

		__overlay__ {
			status = "okay";
			clock-frequency = <0xf4240>;
		};
	};

	fragment@15 {
		target = <0xffffffff>;

		__overlay__ {
			status = "okay";
		};
	};

	fragment@16 {
		target = <0xffffffff>;

		__overlay__ {
			status = "okay";
		};
	};

	fragment@17 {
		target = <0xffffffff>;

		__overlay__ {
			status = "okay";
			sprd,spk-ext-pa-info = <0x00 0x00 0x0d 0x00>;
			sprd,spk-ext-pa-gpio = <0xffffffff 0x71 0x00>;
		};
	};

	fragment@18 {
		target = <0xffffffff>;

		__overlay__ {
			regulator-always-on;
		};
	};

	fragment@19 {
		target = <0xffffffff>;

		__overlay__ {
			monitored-battery = <0x05>;
			sprd,calib-resistance-micro-ohms = <0x2710>;
			sprd,comp-resistance-mohm = <0x14>;
			fgu-capacity-track;
			phys = <0xffffffff>;
			sprd,relax-counter-threshold = <0x244>;
			sprd,relax-current-threshold = <0x1e>;
			sprd,capacity-sleep-calibration;
			sprd,capacity-boot-calibration;
			sprd,capacity-charge-cycle;
			sprd,basp;
			io-channels = <0xffffffff 0x04 0xffffffff 0x0e>;
			io-channel-names = "bat-temp\0charge-vol";
		};
	};

	fragment@20 {
		target = <0xffffffff>;

		__overlay__ {
			avdd-gpio = <0xffffffff 0x36 0x00>;
			avee-gpio = <0xffffffff 0x37 0x00>;
			reset-gpio = <0xffffffff 0x32 0x00>;
		};
	};

	fragment@21 {
		target = <0xffffffff>;

		__overlay__ {
			sprd,logo-memory = <0x0a>;
		};
	};

	fragment@22 {
		target = <0xffffffff>;

		__overlay__ {
			status = "okay";
			sprd,input-voltage-microvolt = <0x4c4b40>;
		};
	};

	fragment@23 {
		target = <0xffffffff>;

		__overlay__ {
			status = "okay";

			connector {
				compatible = "usb-c-connector";
				label = "USB-C";
				power-role = "dual";
				try-power-role = "sink";
				source-pdos = <0x4019028>;
				sink-pdos = <0x401912c 0xc0dc213c>;
				op-sink-microwatt = <0x989680>;
				phandle = <0x2c>;
			};
		};
	};

	fragment@24 {
		target = <0xffffffff>;

		__overlay__ {
			sprd-scene = "boost\0lcdon\0lcdoff\0camlow\0camhigh\0camveryhigh\0faceid\0top\0boot-opt";
			sprd-freq = <0x535 0x300 0x100 0x535 0x535 0xbacd 0x535 0xbacd 0xbacd>;
		};
	};

	fragment@25 {
		target = <0xffffffff>;

		__overlay__ {
			pinctrl-names = "gpio_8\0gpio_22\0gpio_24\0gpio_25\0gpio_26\0gpio_124\0gpio_175";
			pinctrl-0 = <0x0b>;
			pinctrl-1 = <0x0c>;
			pinctrl-2 = <0x0d>;
			pinctrl-3 = <0x0e>;
			pinctrl-4 = <0x0f>;
			pinctrl-5 = <0x10>;
			pinctrl-6 = <0x11>;

			rfctl16 {
				pins = "QOGIRL6_RFCTL16";
				function = "func4";
				phandle = <0x0b>;
			};

			rfctl3 {
				pins = "QOGIRL6_RFCTL3";
				function = "func4";
				phandle = <0x0c>;
			};

			rfctl5 {
				pins = "QOGIRL6_RFCTL5";
				function = "func4";
				phandle = <0x0d>;
			};

			rfctl6 {
				pins = "QOGIRL6_RFCTL6";
				function = "func4";
				phandle = <0x0e>;
			};

			rfctl7 {
				pins = "QOGIRL6_RFCTL7";
				function = "func4";
				phandle = <0x0f>;
			};

			keyin0 {
				pins = "QOGIRL6_KEYIN0";
				function = "func4";
				phandle = <0x10>;
			};

			bt_rfctl2 {
				pins = "QOGIRL6_BT_RFCTL2";
				function = "func4";
				phandle = <0x11>;
			};
		};
	};

	fragment@26 {
		target = <0xffffffff>;

		__overlay__ {
			#address-cells = <0x01>;
			#size-cells = <0x00>;

			heap@4 {
				reg = <0x04>;
				label = "carveout_fd";
				type = <0x02>;
				memory-region = <0x12>;
			};
		};
	};

	fragment@27 {
		target = <0xffffffff>;

		__overlay__ {
			sprd,hw-channels = <0x02 0x18cc 0x03 0x18cc 0x0d 0x1854 0x0f 0x1874 0x11 0x1844 0x13 0x1844 0x15 0x1864 0x1e 0x1820 0x20 0x197c 0x21 0x1988 0x23 0x19b8 0x27 0x19ac>;
			sprd,hw-channels0 = <0x02 0x18cc 0x03 0x18cc 0x0d 0x1874 0x0f 0x1874 0x11 0x1844 0x13 0x1854 0x15 0x1864 0x1e 0x1820 0x20 0x197c 0x21 0x1988 0x23 0x19b8 0x27 0x19ac>;
			sprd,hw-channels1 = <0x02 0x18cc 0x03 0x18cc 0x0d 0x1854 0x0f 0x1874 0x11 0x1844 0x13 0x1844 0x15 0x1864 0x1e 0x1820 0x20 0x197c 0x21 0x1988 0x23 0x19b8 0x27 0x19ac>;
		};
	};

	fragment@28 {
		target = <0xffffffff>;

		__overlay__ {
			status = "okay";
			#address-cells = <0x01>;
			#size-cells = <0x00>;

			transsion-touchscreen@0 {
				status = "okay";
				reg = <0x00>;
				spi-max-frequency = <0x927c00>;
				compatible = "adaptive-touchscreen";
				omnivision,irq-on-state = <0x00>;
				omnivision,power-delay-ms = <0xc8>;
				omnivision,reset-on-state = <0x00>;
				omnivision,reset-active-ms = <0x14>;
				omnivision,reset-delay-ms = <0xc8>;
				omnivision,byte-delay-us = <0x00>;
				omnivision,ubl-max-freq = <0x7a1200>;
				omnivision,ubl-byte-delay-us = <0x14>;
				omnivision,spi-mode = <0x03>;
				omnivision,block-delay-us = <0x00>;
				omnivision,irq-gpio = <0xffffffff 0x10 0x00>;
				omnivision,reset-gpio = <0xffffffff 0x91 0x00>;
				focaltech,reset-gpio = <0xffffffff 0x91 0x00>;
				focaltech,irq-gpio = <0xffffffff 0x10 0x00>;
				focaltech,display-coords = <0x00 0x00 0x167f 0x325f>;
				focaltech,max-touch-number = <0x05>;
				focaltech,fw-three-in-one;
				pt7_hi_limits_row_01 = <0x26>;
				pt7_hi_limits_cols_01 = <0x26>;
				pt7_hi_limits_01 = <0x5dc 0x5dc 0x5dc 0x5dc 0x5dc 0x5dc 0x5dc 0x5dc 0x5dc 0x5dc 0x5dc 0x5dc 0x5dc 0x5dc 0x5dc 0x5dc 0x5dc 0x5dc 0x5dc 0x5dc 0x5dc 0x5dc 0x5dc 0x5dc 0x5dc 0x5dc 0x5dc 0x5dc 0x5dc 0x5dc 0x5dc 0x5dc 0x5dc 0x5dc 0x5dc 0x5dc 0x5dc 0x5dc 0x5dc 0x5dc 0x5dc 0x5dc 0x5dc 0x5dc 0x5dc 0x5dc 0x5dc 0x5dc 0x5dc 0x5dc 0x5dc 0x5dc 0x5dc 0x5dc 0x5dc 0x5dc 0x5dc 0x5dc 0x5dc 0x5dc 0x5dc 0x5dc 0x5dc 0x5dc 0x5dc 0x5dc 0x5dc 0x5dc 0x5dc 0x5dc 0x5dc 0x5dc 0x5dc 0x5dc 0x5dc 0x5dc 0x5dc 0x5dc 0x5dc 0x5dc 0x5dc 0x5dc 0x5dc 0x5dc 0x5dc 0x5dc 0x5dc 0x5dc 0x5dc 0x5dc 0x5dc 0x5dc 0x5dc 0x5dc 0x5dc 0x5dc 0x5dc 0x5dc 0x5dc 0x5dc 0x5dc 0x5dc 0x5dc 0x5dc 0x5dc 0x5dc 0x5dc 0x5dc 0x5dc 0x5dc 0x5dc 0x5dc 0x5dc 0x5dc 0x5dc 0x5dc 0x5dc 0x5dc 0x5dc 0x5dc 0x5dc 0x5dc 0x5dc 0x5dc 0x5dc 0x5dc 0x5dc 0x5dc 0x5dc 0x5dc 0x5dc 0x5dc 0x5dc 0x5dc 0x5dc 0x5dc 0x5dc 0x5dc 0x5dc 0x5dc 0x5dc 0x5dc 0x5dc 0x5dc 0x5dc 0x5dc 0x5dc 0x5dc 0x5dc 0x5dc 0x5dc 0x5dc 0x5dc 0x5dc 0x5dc 0x5dc 0x5dc 0x5dc 0x5dc 0x5dc 0x5dc 0x5dc 0x5dc 0x5dc 0x5dc 0x5dc 0x5dc 0x5dc 0x5dc 0x5dc 0x5dc 0x5dc 0x5dc 0x5dc 0x5dc 0x5dc 0x5dc 0x5dc 0x5dc 0x5dc 0x5dc 0x5dc 0x5dc 0x5dc 0x5dc 0x5dc 0x5dc 0x5dc 0x5dc 0x5dc 0x5dc 0x5dc 0x5dc 0x5dc 0x5dc 0x5dc 0x5dc 0x5dc 0x5dc 0x5dc 0x5dc 0x5dc 0x5dc 0x5dc 0x5dc 0x5dc 0x5dc 0x5dc 0x5dc 0x5dc 0x5dc 0x5dc 0x5dc 0x5dc 0x5dc 0x5dc 0x5dc 0x5dc 0x5dc 0x5dc 0x5dc 0x5dc 0x5dc 0x5dc 0x5dc 0x5dc 0x5dc 0x5dc 0x5dc 0x5dc 0x5dc 0x5dc 0x5dc 0x5dc 0x5dc 0x5dc 0x5dc 0x5dc 0x5dc 0x5dc 0x5dc 0x5dc 0x5dc 0x5dc 0x5dc 0x5dc 0x5dc 0x5dc 0x5dc 0x5dc 0x5dc 0x5dc 0x5dc 0x5dc 0x5dc 0x5dc 0x5dc 0x5dc 0x5dc 0x5dc 0x5dc 0x5dc 0x5dc 0x5dc 0x5dc 0x5dc 0x5dc 0x5dc 0x5dc 0x5dc 0x5dc 0x5dc 0x5dc 0x5dc 0x5dc 0x5dc 0x5dc 0x5dc 0x5dc 0x5dc 0x5dc 0x5dc 0x5dc 0x5dc 0x5dc 0x5dc 0x5dc 0x5dc 0x5dc 0x5dc 0x5dc 0x5dc 0x5dc 0x5dc 0x5dc 0x5dc 0x5dc 0x5dc 0x5dc 0x5dc 0x5dc 0x5dc 0x5dc 0x5dc 0x5dc 0x5dc 0x5dc 0x5dc 0x5dc 0x5dc 0x5dc 0x5dc 0x5dc 0x5dc 0x5dc 0x5dc 0x5dc 0x5dc 0x5dc 0x5dc 0x5dc 0x5dc 0x5dc 0x5dc 0x5dc 0x5dc 0x5dc 0x5dc 0x5dc 0x5dc 0x5dc 0x5dc 0x5dc 0x5dc 0x5dc 0x5dc 0x5dc 0x5dc 0x5dc 0x5dc 0x5dc 0x5dc 0x5dc 0x5dc 0x5dc 0x5dc 0x5dc 0x5dc 0x5dc 0x5dc 0x5dc 0x5dc 0x5dc 0x5dc 0x5dc 0x5dc 0x5dc 0x5dc 0x5dc 0x5dc 0x5dc 0x5dc 0x5dc 0x5dc 0x5dc 0x5dc 0x5dc 0x5dc 0x5dc 0x5dc 0x5dc 0x5dc 0x5dc 0x5dc 0x5dc 0x5dc 0x5dc 0x5dc 0x5dc 0x5dc 0x5dc 0x5dc 0x5dc 0x5dc 0x5dc 0x5dc 0x5dc 0x5dc 0x5dc 0x5dc 0x5dc 0x5dc 0x5dc 0x5dc 0x5dc 0x5dc 0x5dc 0x5dc 0x5dc 0x5dc 0x5dc 0x5dc 0x5dc 0x5dc 0x5dc 0x5dc 0x5dc 0x5dc 0x5dc 0x5dc 0x5dc 0x5dc 0x5dc 0x5dc 0x5dc 0x5dc 0x5dc 0x5dc 0x5dc 0x5dc 0x5dc 0x5dc 0x5dc 0x5dc 0x5dc 0x5dc 0x5dc 0x5dc 0x5dc 0x5dc 0x5dc 0x5dc 0x5dc 0x5dc 0x5dc 0x5dc 0x5dc 0x5dc 0x5dc 0x5dc 0x5dc 0x5dc 0x5dc 0x5dc 0x5dc 0x5dc 0x5dc 0x5dc 0x5dc 0x5dc 0x5dc 0x5dc 0x5dc 0x5dc 0x5dc 0x5dc 0x5dc 0x5dc 0x5dc 0x5dc 0x5dc 0x5dc 0x5dc 0x5dc 0x5dc 0x5dc 0x5dc 0x5dc 0x5dc 0x5dc 0x5dc 0x5dc 0x5dc 0x5dc 0x5dc 0x5dc 0x5dc 0x5dc 0x5dc 0x5dc 0x5dc 0x5dc 0x5dc 0x5dc 0x5dc 0x5dc 0x5dc 0x5dc 0x5dc 0x5dc 0x5dc 0x5dc 0x5dc 0x5dc 0x5dc 0x5dc 0x5dc 0x5dc 0x5dc 0x5dc 0x5dc 0x5dc 0x5dc 0x5dc 0x5dc 0x5dc 0x5dc 0x5dc 0x5dc 0x5dc 0x5dc 0x5dc 0x5dc 0x5dc 0x5dc 0x5dc 0x5dc 0x5dc 0x5dc 0x5dc 0x5dc 0x5dc 0x5dc 0x5dc 0x5dc 0x5dc 0x5dc 0x5dc 0x5dc 0x5dc 0x5dc 0x5dc 0x5dc 0x5dc 0x5dc 0x5dc 0x5dc 0x5dc 0x5dc 0x5dc 0x5dc 0x5dc 0x5dc 0x5dc 0x5dc 0x5dc 0x5dc 0x5dc 0x5dc 0x5dc 0x5dc 0x5dc 0x5dc 0x5dc 0x5dc 0x5dc 0x5dc 0x5dc 0x5dc 0x5dc 0x5dc 0x5dc 0x5dc 0x5dc 0x5dc 0x5dc 0x5dc 0x5dc 0x5dc 0x5dc 0x5dc 0x5dc 0x5dc 0x5dc 0x5dc 0x5dc 0x5dc 0x5dc 0x5dc 0x5dc 0x5dc 0x5dc 0x5dc 0x5dc 0x5dc 0x5dc 0x5dc 0x5dc 0x5dc 0x5dc 0x5dc 0x5dc 0x5dc 0x5dc 0x5dc 0x5dc 0x5dc 0x5dc 0x5dc 0x5dc 0x5dc 0x5dc 0x5dc 0x5dc 0x5dc 0x5dc 0x5dc 0x5dc 0x5dc 0x5dc 0x5dc 0x5dc 0x5dc 0x5dc 0x5dc 0x5dc 0x5dc 0x5dc 0x5dc 0x5dc 0x5dc 0x5dc 0x5dc 0x5dc 0x5dc 0x5dc 0x5dc 0x5dc 0x5dc 0x5dc 0x5dc 0x5dc 0x5dc 0x5dc 0x5dc 0x5dc 0x5dc 0x5dc 0x5dc 0x5dc 0x5dc 0x5dc 0x5dc 0x5dc 0x5dc 0x5dc 0x5dc 0x5dc 0x5dc 0x5dc 0x5dc 0x5dc 0x5dc 0x5dc 0x5dc 0x5dc 0x5dc 0x5dc 0x5dc 0x5dc 0x5dc 0x5dc 0x5dc 0x5dc 0x5dc 0x5dc 0x5dc 0x5dc 0x5dc 0x5dc 0x5dc 0x5dc 0x5dc 0x5dc 0x5dc 0x5dc 0x5dc 0x5dc 0x5dc 0x5dc 0x5dc 0x5dc 0x5dc 0x5dc 0x5dc 0x5dc 0x5dc 0x5dc 0x5dc 0x5dc 0x5dc 0x5dc 0x5dc 0x5dc 0x5dc 0x5dc 0x5dc 0x5dc 0x5dc 0x5dc 0x5dc 0x5dc 0x5dc 0x5dc 0x5dc 0x5dc 0x5dc 0x5dc 0x5dc 0x5dc 0x5dc 0x5dc 0x5dc 0x5dc 0x5dc 0x5dc 0x5dc 0x5dc 0x5dc 0x5dc 0x5dc 0x5dc 0x5dc 0x5dc 0x5dc 0x5dc 0x5dc 0x5dc 0x5dc 0x5dc 0x5dc 0x5dc 0x5dc 0x5dc 0x5dc 0x5dc 0x5dc 0x5dc 0x5dc 0x5dc 0x5dc 0x5dc 0x5dc 0x5dc 0x5dc 0x5dc 0x5dc 0x5dc 0x5dc 0x5dc 0x5dc 0x5dc 0x5dc 0x5dc 0x5dc 0x5dc 0x5dc 0x5dc 0x5dc 0x5dc 0x5dc 0x5dc 0x5dc 0x5dc 0x5dc 0x5dc 0x5dc 0x5dc 0x5dc 0x5dc 0x5dc 0x5dc 0x5dc 0x5dc 0x5dc 0x5dc 0x5dc 0x5dc 0x5dc 0x5dc 0x5dc 0x5dc 0x5dc 0x5dc 0x5dc 0x5dc 0x5dc 0x5dc 0x5dc 0x5dc 0x5dc 0x5dc 0x5dc 0x5dc 0x5dc 0x5dc 0x5dc 0x5dc 0x5dc 0x5dc 0x5dc 0x5dc 0x5dc 0x5dc 0x5dc 0x5dc 0x5dc 0x5dc 0x5dc 0x5dc 0x5dc 0x5dc 0x5dc 0x5dc 0x5dc 0x5dc 0x5dc 0x5dc 0x5dc 0x5dc 0x5dc 0x5dc 0x5dc 0x5dc 0x5dc 0x5dc 0x5dc 0x5dc 0x5dc 0x5dc 0x5dc 0x5dc 0x5dc 0x5dc 0x5dc 0x5dc 0x5dc 0x5dc 0x5dc 0x5dc 0x5dc 0x5dc 0x5dc 0x5dc 0x5dc 0x5dc 0x5dc 0x5dc 0x5dc 0x5dc 0x5dc 0x5dc 0x5dc 0x5dc 0x5dc 0x5dc 0x5dc 0x5dc 0x5dc 0x5dc 0x5dc 0x5dc 0x5dc 0x5dc 0x5dc 0x5dc 0x5dc 0x5dc 0x5dc 0x5dc 0x5dc 0x5dc 0x5dc 0x5dc 0x5dc 0x5dc 0x5dc 0x5dc 0x5dc 0x5dc 0x5dc 0x5dc 0x5dc 0x5dc 0x5dc 0x5dc 0x5dc 0x5dc 0x5dc 0x5dc 0x5dc 0x5dc 0x5dc 0x5dc 0x5dc 0x5dc 0x5dc 0x5dc 0x5dc 0x5dc 0x5dc 0x5dc 0x5dc 0x5dc 0x5dc 0x5dc 0x5dc 0x5dc 0x5dc 0x5dc 0x5dc 0x5dc 0x5dc 0x5dc 0x5dc 0x5dc 0x5dc 0x5dc 0x5dc 0x5dc 0x5dc 0x5dc 0x5dc 0x5dc 0x5dc 0x5dc 0x5dc 0x5dc 0x5dc 0x5dc 0x5dc 0x5dc 0x5dc 0x5dc 0x5dc 0x5dc 0x5dc 0x5dc 0x5dc 0x5dc 0x5dc 0x5dc 0x5dc 0x5dc 0x5dc 0x5dc 0x5dc 0x5dc 0x5dc 0x5dc 0x5dc 0x5dc 0x5dc 0x5dc 0x5dc 0x5dc 0x5dc 0x5dc 0x5dc 0x5dc 0x5dc 0x5dc 0x5dc 0x5dc 0x5dc 0x5dc 0x5dc 0x5dc 0x5dc 0x5dc 0x5dc 0x5dc 0x5dc 0x5dc 0x5dc 0x5dc 0x5dc 0x5dc 0x5dc 0x5dc 0x5dc 0x5dc 0x5dc 0x5dc 0x5dc 0x5dc 0x5dc 0x5dc 0x5dc 0x5dc 0x5dc 0x5dc 0x5dc 0x5dc 0x5dc 0x5dc 0x5dc 0x5dc 0x5dc 0x5dc 0x5dc 0x5dc 0x5dc 0x5dc 0x5dc 0x5dc 0x5dc 0x5dc 0x5dc 0x5dc 0x5dc 0x5dc 0x5dc 0x5dc 0x5dc 0x5dc 0x5dc 0x5dc 0x5dc 0x5dc 0x5dc 0x5dc 0x5dc 0x5dc 0x5dc 0x5dc 0x5dc 0x5dc 0x5dc 0x5dc 0x5dc 0x5dc 0x5dc 0x5dc 0x5dc 0x5dc 0x5dc 0x5dc 0x5dc 0x5dc 0x5dc 0x5dc 0x5dc 0x5dc 0x5dc 0x5dc 0x5dc 0x5dc 0x5dc 0x5dc 0x5dc 0x5dc 0x5dc 0x5dc 0x5dc 0x5dc 0x5dc 0x5dc 0x5dc 0x5dc 0x5dc 0x5dc 0x5dc 0x5dc 0x5dc 0x5dc 0x5dc 0x5dc 0x5dc 0x5dc 0x5dc 0x5dc 0x5dc 0x5dc 0x5dc 0x5dc 0x5dc 0x5dc 0x5dc 0x5dc 0x5dc 0x5dc 0x5dc 0x5dc 0x5dc 0x5dc 0x5dc 0x5dc 0x5dc 0x5dc 0x5dc 0x5dc 0x5dc 0x5dc 0x5dc 0x5dc 0x5dc 0x5dc 0x5dc 0x5dc 0x5dc 0x5dc 0x5dc 0x5dc 0x5dc 0x5dc 0x5dc 0x5dc 0x5dc 0x5dc 0x5dc 0x5dc 0x5dc 0x5dc 0x5dc 0x5dc 0x5dc 0x5dc 0x5dc 0x5dc 0x5dc 0x5dc 0x5dc 0x5dc 0x5dc 0x5dc 0x5dc 0x5dc 0x5dc 0x5dc 0x5dc 0x5dc 0x5dc 0x5dc 0x5dc 0x5dc 0x5dc 0x5dc 0x5dc 0x5dc 0x5dc 0x5dc 0x5dc 0x5dc 0x5dc 0x5dc 0x5dc 0x5dc 0x5dc 0x5dc 0x5dc 0x5dc 0x5dc 0x5dc 0x5dc 0x5dc 0x5dc 0x5dc 0x5dc 0x5dc 0x5dc 0x5dc 0x5dc 0x5dc 0x5dc 0x5dc 0x5dc 0x5dc 0x5dc 0x5dc 0x5dc 0x5dc 0x5dc 0x5dc 0x5dc 0x5dc 0x5dc 0x5dc 0x5dc 0x5dc 0x5dc 0x5dc 0x5dc 0x5dc 0x5dc 0x5dc 0x5dc 0x3a98 0x5dc 0x5dc 0x5dc 0x5dc 0x5dc 0x5dc 0x5dc 0x5dc 0x5dc 0x5dc 0x5dc 0x5dc 0x5dc 0x5dc 0x5dc 0x5dc 0x5dc 0x5dc 0x5dc 0x5dc 0x5dc 0x5dc 0x5dc 0x5dc 0x5dc 0x5dc 0x5dc 0x5dc 0x5dc 0x5dc 0x5dc 0x5dc 0x5dc 0x5dc 0x5dc 0x5dc 0x5dc 0x5dc 0x5dc 0x5dc 0x5dc 0x5dc 0x5dc 0x5dc 0x5dc 0x5dc 0x5dc 0x5dc 0x5dc 0x5dc 0x5dc 0x5dc 0x5dc 0x5dc 0x5dc 0x5dc 0x5dc 0x5dc 0x5dc 0x5dc 0x5dc 0x5dc 0x5dc 0x5dc 0x5dc 0x5dc 0x5dc 0x5dc 0x5dc 0x5dc 0x5dc 0x5dc 0x5dc 0x5dc 0x5dc 0x5dc 0x5dc 0x5dc 0x5dc 0x5dc 0x5dc 0x5dc 0x5dc 0x5dc 0x5dc 0x5dc 0x5dc 0x5dc 0x5dc 0x5dc 0x5dc 0x5dc 0x5dc 0x5dc 0x5dc 0x5dc 0x5dc 0x5dc 0x5dc 0x5dc 0x5dc 0x5dc 0x5dc 0x5dc 0x5dc 0x5dc 0x5dc 0x5dc 0x5dc 0x5dc 0x5dc 0x5dc 0x5dc 0x5dc 0x5dc 0x5dc 0x5dc 0x5dc 0x5dc 0x5dc 0x5dc 0x5dc 0x5dc 0x5dc 0x5dc 0x5dc 0x5dc 0x5dc 0x5dc 0x5dc 0x5dc 0x5dc 0x5dc 0x5dc 0x5dc 0x5dc 0x5dc 0x5dc 0x5dc 0x5dc 0x5dc 0x5dc 0x5dc 0x5dc 0x5dc 0x5dc 0x5dc 0x5dc 0x5dc 0x5dc 0x5dc 0x5dc 0x5dc 0x5dc 0x5dc 0x5dc 0x5dc 0x5dc 0x5dc 0x5dc 0x5dc 0x5dc 0x5dc 0x5dc 0x5dc 0x5dc 0x5dc 0x5dc 0x5dc 0x5dc 0x5dc 0x5dc 0x5dc 0x5dc 0x5dc 0x5dc 0x5dc 0x5dc 0x5dc 0x5dc 0x5dc 0x5dc 0x5dc 0x5dc 0x5dc 0x5dc 0x5dc 0x5dc 0x5dc 0x5dc 0x5dc 0x5dc 0x5dc 0x5dc 0x5dc 0x5dc 0x5dc 0x5dc 0x5dc 0x5dc 0x5dc 0x5dc 0x5dc 0x5dc 0x5dc 0x5dc 0x5dc 0x5dc 0x5dc 0x5dc 0x5dc 0x5dc 0x5dc 0x5dc 0x5dc 0x5dc 0x5dc 0x5dc 0x5dc 0x5dc 0x5dc 0x5dc 0x5dc 0x5dc 0x5dc 0x5dc 0x5dc 0x5dc 0x5dc 0x5dc 0x5dc 0x5dc 0x5dc 0x5dc 0x5dc 0x5dc 0x5dc 0x5dc 0x5dc 0x5dc 0x5dc 0x5dc 0x5dc 0x5dc 0x5dc 0x5dc 0x5dc 0x5dc 0x5dc 0x5dc 0x5dc 0x5dc 0x5dc 0x5dc 0x5dc 0x5dc>;
				pt7_lo_limits_row_01 = <0x26>;
				pt7_lo_limits_cols_01 = <0x26>;
				pt7_lo_limits_01 = <0x1f4 0x1f4 0x1f4 0x1f4 0x1f4 0x1f4 0x1f4 0x1f4 0x1f4 0x1f4 0x1f4 0x1f4 0x1f4 0x1f4 0x1f4 0x1f4 0x1f4 0x1f4 0x1f4 0x1f4 0x1f4 0x1f4 0x1f4 0x1f4 0x1f4 0x1f4 0x1f4 0x1f4 0x1f4 0x1f4 0x1f4 0x1f4 0x1f4 0x1f4 0x1f4 0x1f4 0x1f4 0x1f4 0x1f4 0x1f4 0x1f4 0x1f4 0x1f4 0x1f4 0x1f4 0x1f4 0x1f4 0x1f4 0x1f4 0x1f4 0x1f4 0x1f4 0x1f4 0x1f4 0x1f4 0x1f4 0x1f4 0x1f4 0x1f4 0x1f4 0x1f4 0x1f4 0x1f4 0x1f4 0x1f4 0x1f4 0x1f4 0x1f4 0x1f4 0x1f4 0x1f4 0x1f4 0x1f4 0x1f4 0x1f4 0x1f4 0x1f4 0x1f4 0x1f4 0x1f4 0x1f4 0x1f4 0x1f4 0x1f4 0x1f4 0x1f4 0x1f4 0x1f4 0x1f4 0x1f4 0x1f4 0x1f4 0x1f4 0x1f4 0x1f4 0x1f4 0x1f4 0x1f4 0x1f4 0x1f4 0x1f4 0x1f4 0x1f4 0x1f4 0x1f4 0x1f4 0x1f4 0x1f4 0x1f4 0x1f4 0x1f4 0x1f4 0x1f4 0x1f4 0x1f4 0x1f4 0x1f4 0x1f4 0x1f4 0x1f4 0x1f4 0x1f4 0x1f4 0x1f4 0x1f4 0x1f4 0x1f4 0x1f4 0x1f4 0x1f4 0x1f4 0x1f4 0x1f4 0x1f4 0x1f4 0x1f4 0x1f4 0x1f4 0x1f4 0x1f4 0x1f4 0x1f4 0x1f4 0x1f4 0x1f4 0x1f4 0x1f4 0x1f4 0x1f4 0x1f4 0x1f4 0x1f4 0x1f4 0x1f4 0x1f4 0x1f4 0x1f4 0x1f4 0x1f4 0x1f4 0x1f4 0x1f4 0x1f4 0x1f4 0x1f4 0x1f4 0x1f4 0x1f4 0x1f4 0x1f4 0x1f4 0x1f4 0x1f4 0x1f4 0x1f4 0x1f4 0x1f4 0x1f4 0x1f4 0x1f4 0x1f4 0x1f4 0x1f4 0x1f4 0x1f4 0x1f4 0x1f4 0x1f4 0x1f4 0x1f4 0x1f4 0x1f4 0x1f4 0x1f4 0x1f4 0x1f4 0x1f4 0x1f4 0x1f4 0x1f4 0x1f4 0x1f4 0x1f4 0x1f4 0x1f4 0x1f4 0x1f4 0x1f4 0x1f4 0x1f4 0x1f4 0x1f4 0x1f4 0x1f4 0x1f4 0x1f4 0x1f4 0x1f4 0x1f4 0x1f4 0x1f4 0x1f4 0x1f4 0x1f4 0x1f4 0x1f4 0x1f4 0x1f4 0x1f4 0x1f4 0x1f4 0x1f4 0x1f4 0x1f4 0x1f4 0x1f4 0x1f4 0x1f4 0x1f4 0x1f4 0x1f4 0x1f4 0x1f4 0x1f4 0x1f4 0x1f4 0x1f4 0x1f4 0x1f4 0x1f4 0x1f4 0x1f4 0x1f4 0x1f4 0x1f4 0x1f4 0x1f4 0x1f4 0x1f4 0x1f4 0x1f4 0x1f4 0x1f4 0x1f4 0x1f4 0x1f4 0x1f4 0x1f4 0x1f4 0x1f4 0x1f4 0x1f4 0x1f4 0x1f4 0x1f4 0x1f4 0x1f4 0x1f4 0x1f4 0x1f4 0x1f4 0x1f4 0x1f4 0x1f4 0x1f4 0x1f4 0x1f4 0x1f4 0x1f4 0x1f4 0x1f4 0x1f4 0x1f4 0x1f4 0x1f4 0x1f4 0x1f4 0x1f4 0x1f4 0x1f4 0x1f4 0x1f4 0x1f4 0x1f4 0x1f4 0x1f4 0x1f4 0x1f4 0x1f4 0x1f4 0x1f4 0x1f4 0x1f4 0x1f4 0x1f4 0x1f4 0x1f4 0x1f4 0x1f4 0x1f4 0x1f4 0x1f4 0x1f4 0x1f4 0x1f4 0x1f4 0x1f4 0x1f4 0x1f4 0x1f4 0x1f4 0x1f4 0x1f4 0x1f4 0x1f4 0x1f4 0x1f4 0x1f4 0x1f4 0x1f4 0x1f4 0x1f4 0x1f4 0x1f4 0x1f4 0x1f4 0x1f4 0x1f4 0x1f4 0x1f4 0x1f4 0x1f4 0x1f4 0x1f4 0x1f4 0x1f4 0x1f4 0x1f4 0x1f4 0x1f4 0x1f4 0x1f4 0x1f4 0x1f4 0x1f4 0x1f4 0x1f4 0x1f4 0x1f4 0x1f4 0x1f4 0x1f4 0x1f4 0x1f4 0x1f4 0x1f4 0x1f4 0x1f4 0x1f4 0x1f4 0x1f4 0x1f4 0x1f4 0x1f4 0x1f4 0x1f4 0x1f4 0x1f4 0x1f4 0x1f4 0x1f4 0x1f4 0x1f4 0x1f4 0x1f4 0x1f4 0x1f4 0x1f4 0x1f4 0x1f4 0x1f4 0x1f4 0x1f4 0x1f4 0x1f4 0x1f4 0x1f4 0x1f4 0x1f4 0x1f4 0x1f4 0x1f4 0x1f4 0x1f4 0x1f4 0x1f4 0x1f4 0x1f4 0x1f4 0x1f4 0x1f4 0x1f4 0x1f4 0x1f4 0x1f4 0x1f4 0x1f4 0x1f4 0x1f4 0x1f4 0x1f4 0x1f4 0x1f4 0x1f4 0x1f4 0x1f4 0x1f4 0x1f4 0x1f4 0x1f4 0x1f4 0x1f4 0x1f4 0x1f4 0x1f4 0x1f4 0x1f4 0x1f4 0x1f4 0x1f4 0x1f4 0x1f4 0x1f4 0x1f4 0x1f4 0x1f4 0x1f4 0x1f4 0x1f4 0x1f4 0x1f4 0x1f4 0x1f4 0x1f4 0x1f4 0x1f4 0x1f4 0x1f4 0x1f4 0x1f4 0x1f4 0x1f4 0x1f4 0x1f4 0x1f4 0x1f4 0x1f4 0x1f4 0x1f4 0x1f4 0x1f4 0x1f4 0x1f4 0x1f4 0x1f4 0x1f4 0x1f4 0x1f4 0x1f4 0x1f4 0x1f4 0x1f4 0x1f4 0x1f4 0x1f4 0x1f4 0x1f4 0x1f4 0x1f4 0x1f4 0x1f4 0x1f4 0x1f4 0x1f4 0x1f4 0x1f4 0x1f4 0x1f4 0x1f4 0x1f4 0x1f4 0x1f4 0x1f4 0x1f4 0x1f4 0x1f4 0x1f4 0x1f4 0x1f4 0x1f4 0x1f4 0x1f4 0x1f4 0x1f4 0x1f4 0x1f4 0x1f4 0x1f4 0x1f4 0x1f4 0x1f4 0x1f4 0x1f4 0x1f4 0x1f4 0x1f4 0x1f4 0x1f4 0x1f4 0x1f4 0x1f4 0x1f4 0x1f4 0x1f4 0x1f4 0x1f4 0x1f4 0x1f4 0x1f4 0x1f4 0x1f4 0x1f4 0x1f4 0x1f4 0x1f4 0x1f4 0x1f4 0x1f4 0x1f4 0x1f4 0x1f4 0x1f4 0x1f4 0x1f4 0x1f4 0x1f4 0x1f4 0x1f4 0x1f4 0x1f4 0x1f4 0x1f4 0x1f4 0x1f4 0x1f4 0x1f4 0x1f4 0x1f4 0x1f4 0x1f4 0x1f4 0x1f4 0x1f4 0x1f4 0x1f4 0x1f4 0x1f4 0x1f4 0x1f4 0x1f4 0x1f4 0x1f4 0x1f4 0x1f4 0x1f4 0x1f4 0x1f4 0x1f4 0x1f4 0x1f4 0x1f4 0x1f4 0x1f4 0x1f4 0x1f4 0x1f4 0x1f4 0x1f4 0x1f4 0x1f4 0x1f4 0x1f4 0x1f4 0x1f4 0x1f4 0x1f4 0x1f4 0x1f4 0x1f4 0x1f4 0x1f4 0x1f4 0x1f4 0x1f4 0x1f4 0x1f4 0x1f4 0x1f4 0x1f4 0x1f4 0x1f4 0x1f4 0x1f4 0x1f4 0x1f4 0x1f4 0x1f4 0x1f4 0x1f4 0x1f4 0x1f4 0x1f4 0x1f4 0x1f4 0x1f4 0x1f4 0x1f4 0x1f4 0x1f4 0x1f4 0x1f4 0x1f4 0x1f4 0x1f4 0x1f4 0x1f4 0x1f4 0x1f4 0x1f4 0x1f4 0x1f4 0x1f4 0x1f4 0x1f4 0x1f4 0x1f4 0x1f4 0x1f4 0x1f4 0x1f4 0x1f4 0x1f4 0x1f4 0x1f4 0x1f4 0x1f4 0x1f4 0x1f4 0x1f4 0x1f4 0x1f4 0x1f4 0x1f4 0x1f4 0x1f4 0x1f4 0x1f4 0x1f4 0x1f4 0x1f4 0x1f4 0x1f4 0x1f4 0x1f4 0x1f4 0x1f4 0x1f4 0x1f4 0x1f4 0x1f4 0x1f4 0x1f4 0x1f4 0x1f4 0x1f4 0x1f4 0x1f4 0x1f4 0x1f4 0x1f4 0x1f4 0x1f4 0x1f4 0x1f4 0x1f4 0x1f4 0x1f4 0x1f4 0x1f4 0x1f4 0x1f4 0x1f4 0x1f4 0x1f4 0x1f4 0x1f4 0x1f4 0x1f4 0x1f4 0x1f4 0x1f4 0x1f4 0x1f4 0x1f4 0x1f4 0x1f4 0x1f4 0x1f4 0x1f4 0x1f4 0x1f4 0x1f4 0x1f4 0x1f4 0x1f4 0x1f4 0x1f4 0x1f4 0x1f4 0x1f4 0x1f4 0x1f4 0x1f4 0x1f4 0x1f4 0x1f4 0x1f4 0x1f4 0x1f4 0x1f4 0x1f4 0x1f4 0x1f4 0x1f4 0x1f4 0x1f4 0x1f4 0x1f4 0x1f4 0x1f4 0x1f4 0x1f4 0x1f4 0x1f4 0x1f4 0x1f4 0x1f4 0x1f4 0x1f4 0x1f4 0x1f4 0x1f4 0x1f4 0x1f4 0x1f4 0x1f4 0x1f4 0x1f4 0x1f4 0x1f4 0x1f4 0x1f4 0x1f4 0x1f4 0x1f4 0x1f4 0x1f4 0x1f4 0x1f4 0x1f4 0x1f4 0x1f4 0x1f4 0x1f4 0x1f4 0x1f4 0x1f4 0x1f4 0x1f4 0x1f4 0x1f4 0x1f4 0x1f4 0x1f4 0x1f4 0x1f4 0x1f4 0x1f4 0x1f4 0x1f4 0x1f4 0x1f4 0x1f4 0x1f4 0x1f4 0x1f4 0x1f4 0x1f4 0x1f4 0x1f4 0x1f4 0x1f4 0x1f4 0x1f4 0x1f4 0x1f4 0x1f4 0x1f4 0x1f4 0x1f4 0x1f4 0x1f4 0x1f4 0x1f4 0x1f4 0x1f4 0x1f4 0x1f4 0x1f4 0x1f4 0x1f4 0x1f4 0x1f4 0x1f4 0x1f4 0x1f4 0x1f4 0x1f4 0x1f4 0x1f4 0x1f4 0x1f4 0x1f4 0x1f4 0x1f4 0x1f4 0x1f4 0x1f4 0x1f4 0x1f4 0x1f4 0x1f4 0x1f4 0x1f4 0x1f4 0x1f4 0x1f4 0x1f4 0x1f4 0x1f4 0x1f4 0x1f4 0x1f4 0x1f4 0x1f4 0x1f4 0x1f4 0x1f4 0x1f4 0x1f4 0x1f4 0x1f4 0x1f4 0x1f4 0x1f4 0x1f4 0x1f4 0x1f4 0x1f4 0x1f4 0x1f4 0x1f4 0x1f4 0x1f4 0x1f4 0x1f4 0x1f4 0x1f4 0x1f4 0x1f4 0x1f4 0x1f4 0x1f4 0x1f4 0x1f4 0x1f4 0x1f4 0x1f4 0x1f4 0x1f4 0x1f4 0x1f4 0x1f4 0x1f4 0x1f4 0x1f4 0x1f4 0x1f4 0x1f4 0x1f4 0x1f4 0x1f4 0x1f4 0x1f4 0x1f4 0x1f4 0x1f4 0x1f4 0x1f4 0x1f4 0x1f4 0x1f4 0x1f4 0x1f4 0x1f4 0x1f4 0x1f4 0x1f4 0x1f4 0x1f4 0x1f4 0x1f4 0x1f4 0x1f4 0x1f4 0x1f4 0x1f4 0x1f4 0x1f4 0x1f4 0x1f4 0x1f4 0x1f4 0x1f4 0x1f4 0x1f4 0x1f4 0x1f4 0x1f4 0x1f4 0x1f4 0x1f4 0x1f4 0x1f4 0x1f4 0x1f4 0x1f4 0x1f4 0x1f4 0x1f4 0x1f4 0x1f4 0x1f4 0x1f4 0x1f4 0x1f4 0x1f4 0x1f4 0x1f4 0x1f4 0x1f4 0x1f4 0x1f4 0x1f4 0x1f4 0x1f4 0x1f4 0x1f4 0x1f4 0x1f4 0x1f4 0x1f4 0x1f4 0x1f4 0x1f4 0x1f4 0x1f4 0x1f4 0x1f4 0x1f4 0x1f4 0x1f4 0x1f4 0x1f4 0x1f4 0x1f4 0x1f4 0x1f4 0x1f4 0x1f4 0x1f4 0x1f4 0x1f4 0x1f4 0x1f4 0x1f4 0x1f4 0x1f4 0x1f4 0x1f4 0x1f4 0x1f4 0x1f4 0x1f4 0x1f4 0x1f4 0x1f4 0x1f4 0x1f4 0x1f4 0x1f4 0x1f4 0x1f4 0x1f4 0x1f4 0x1f4 0x1f4 0x1f4 0x1f4 0x1f4 0x1f4 0x1f4 0x1f4 0x1f4 0x1f4 0x1f4 0x1f4 0x1f4 0x1f4 0x1f4 0x1f4 0x1f4 0x1f4 0x1f4 0x1f4 0x1f4 0x1f4 0x1f4 0x1f4 0x1f4 0x1f4 0x1f4 0x1f4 0x1f4 0x1f4 0x1f4 0x1f4 0x1f4 0x1f4 0x1f4 0x1f4 0x1f4 0x1f4 0x1f4 0x1f4 0x1f4 0x1f4 0x1f4 0x1f4 0x1f4 0x1f4 0x1f4 0x1f4 0x1f4 0x1f4 0x1f4 0x1f4 0x1f4 0x1f4 0x1f4 0x1f4 0x1f4 0x1f4 0x1f4 0x1f4 0x1f4 0x1f4 0x1f4 0x1f4 0x1f4 0x1f4 0x1f4 0x1f4 0x1f4 0x1f4 0x1f4 0x1f4 0x1f4 0x1f4 0x1f4 0x1f4 0x1f4 0x1f4 0x1f4 0x1f4 0x1f4 0x1f4 0x1f4 0x1f4 0x1f4 0x1f4 0x1f4 0x1f4 0x1f4 0x1f4 0x1f4 0x1f4 0x1f4 0x1f4 0x1f4 0x1f4 0x1f4 0x1f4 0x1f4 0x1f4 0x1f4 0x1f4 0x1f4 0x1f4 0x1f4 0x1f4 0x1f4 0x1f4 0x1f4 0x1f4 0x1f4 0x1f4 0x1f4 0x1f4 0x1f4 0x1f4 0x1f4 0x1f4 0x1f4 0x1f4 0x1f4 0x1f4 0x1f4 0x1f4 0x1f4 0x1f4 0x1f4 0x1f4 0x1f4 0x1f4 0x1f4 0x1f4 0x1f4 0x1f4 0x1f4 0x1f4 0x1f4 0x1f4 0x1f4 0x1f4 0x1f4 0x1f4 0x14 0x1f4 0x1f4 0x1f4 0x1f4 0x1f4 0x1f4 0x1f4 0x1f4 0x1f4 0x1f4 0x1f4 0x1f4 0x1f4 0x1f4 0x1f4 0x1f4 0x1f4 0x1f4 0x1f4 0x1f4 0x1f4 0x1f4 0x1f4 0x1f4 0x1f4 0x1f4 0x1f4 0x1f4 0x1f4 0x1f4 0x1f4 0x1f4 0x1f4 0x1f4 0x1f4 0x1f4 0x1f4 0x1f4 0x1f4 0x1f4 0x1f4 0x1f4 0x1f4 0x1f4 0x1f4 0x1f4 0x1f4 0x1f4 0x1f4 0x1f4 0x1f4 0x1f4 0x1f4 0x1f4 0x1f4 0x1f4 0x1f4 0x1f4 0x1f4 0x1f4 0x1f4 0x1f4 0x1f4 0x1f4 0x1f4 0x1f4 0x1f4 0x1f4 0x1f4 0x1f4 0x1f4 0x1f4 0x1f4 0x1f4 0x1f4 0x1f4 0x1f4 0x1f4 0x1f4 0x1f4 0x1f4 0x1f4 0x1f4 0x1f4 0x1f4 0x1f4 0x1f4 0x1f4 0x1f4 0x1f4 0x1f4 0x1f4 0x1f4 0x1f4 0x1f4 0x1f4 0x1f4 0x1f4 0x1f4 0x1f4 0x1f4 0x1f4 0x1f4 0x1f4 0x1f4 0x1f4 0x1f4 0x1f4 0x1f4 0x1f4 0x1f4 0x1f4 0x1f4 0x1f4 0x1f4 0x1f4 0x1f4 0x1f4 0x1f4 0x1f4 0x1f4 0x1f4 0x1f4 0x1f4 0x1f4 0x1f4 0x1f4 0x1f4 0x1f4 0x1f4 0x1f4 0x1f4 0x1f4 0x1f4 0x1f4 0x1f4 0x1f4 0x1f4 0x1f4 0x1f4 0x1f4 0x1f4 0x1f4 0x1f4 0x1f4 0x1f4 0x1f4 0x1f4 0x1f4 0x1f4 0x1f4 0x1f4 0x1f4 0x1f4 0x1f4 0x1f4 0x1f4 0x1f4 0x1f4 0x1f4 0x1f4 0x1f4 0x1f4 0x1f4 0x1f4 0x1f4 0x1f4 0x1f4 0x1f4 0x1f4 0x1f4 0x1f4 0x1f4 0x1f4 0x1f4 0x1f4 0x1f4 0x1f4 0x1f4 0x1f4 0x1f4 0x1f4 0x1f4 0x1f4 0x1f4 0x1f4 0x1f4 0x1f4 0x1f4 0x1f4 0x1f4 0x1f4 0x1f4 0x1f4 0x1f4 0x1f4 0x1f4 0x1f4 0x1f4 0x1f4 0x1f4 0x1f4 0x1f4 0x1f4 0x1f4 0x1f4 0x1f4 0x1f4 0x1f4 0x1f4 0x1f4 0x1f4 0x1f4 0x1f4 0x1f4 0x1f4 0x1f4 0x1f4 0x1f4 0x1f4 0x1f4 0x1f4 0x1f4 0x1f4 0x1f4 0x1f4 0x1f4 0x1f4 0x1f4 0x1f4 0x1f4 0x1f4 0x1f4 0x1f4 0x1f4 0x1f4 0x1f4 0x1f4 0x1f4 0x1f4 0x1f4 0x1f4 0x1f4 0x1f4 0x1f4 0x1f4 0x1f4 0x1f4 0x1f4 0x1f4 0x1f4 0x1f4 0x1f4 0x1f4 0x1f4 0x1f4>;
				pt11_hi_limits_row_01 = <0x26>;
				pt11_hi_limits_cols_01 = <0x26>;
				pt11_hi_limits_01 = <0x50 0x50 0x50 0x50 0x50 0x50 0x50 0x50 0x50 0x50 0x50 0x50 0x50 0x50 0x50 0x50 0x50 0x50 0x50 0x50 0x50 0x50 0x50 0x50 0x50 0x50 0x50 0x50 0x50 0x50 0x50 0x50 0x50 0x50 0x50 0x50 0x50 0x50 0x50 0x50 0x50 0x50 0x50 0x50 0x50 0x50 0x50 0x50 0x50 0x50 0x50 0x50 0x50 0x50 0x50 0x50 0x50 0x50 0x50 0x50 0x50 0x50 0x50 0x50 0x50 0x50 0x50 0x50 0x50 0x50 0x50 0x50 0x50 0x50 0x50 0x50 0x50 0x50 0x50 0x50 0x50 0x50 0x50 0x50 0x50 0x50 0x50 0x50 0x50 0x50 0x50 0x50 0x50 0x50 0x50 0x50 0x50 0x50 0x50 0x50 0x50 0x50 0x50 0x50 0x50 0x50 0x50 0x50 0x50 0x50 0x50 0x50 0x50 0x50 0x50 0x50 0x50 0x50 0x50 0x50 0x50 0x50 0x50 0x50 0x50 0x50 0x50 0x50 0x50 0x50 0x50 0x50 0x50 0x50 0x50 0x50 0x50 0x50 0x50 0x50 0x50 0x50 0x50 0x50 0x50 0x50 0x50 0x50 0x50 0x50 0x50 0x50 0x50 0x50 0x50 0x50 0x50 0x50 0x50 0x50 0x50 0x50 0x50 0x50 0x50 0x50 0x50 0x50 0x50 0x50 0x50 0x50 0x50 0x50 0x50 0x50 0x50 0x50 0x50 0x50 0x50 0x50 0x50 0x50 0x50 0x50 0x50 0x50 0x50 0x50 0x50 0x50 0x50 0x50 0x50 0x50 0x50 0x50 0x50 0x50 0x50 0x50 0x50 0x50 0x50 0x50 0x50 0x50 0x50 0x50 0x50 0x50 0x50 0x50 0x50 0x50 0x50 0x50 0x50 0x50 0x50 0x50 0x50 0x50 0x50 0x50 0x50 0x50 0x50 0x50 0x50 0x50 0x50 0x50 0x50 0x50 0x50 0x50 0x50 0x50 0x50 0x50 0x50 0x50 0x50 0x50 0x50 0x50 0x50 0x50 0x50 0x50 0x50 0x50 0x50 0x50 0x50 0x50 0x50 0x50 0x50 0x50 0x50 0x50 0x50 0x50 0x50 0x50 0x50 0x50 0x50 0x50 0x50 0x50 0x50 0x50 0x50 0x50 0x50 0x50 0x50 0x50 0x50 0x50 0x50 0x50 0x50 0x50 0x50 0x50 0x50 0x50 0x50 0x50 0x50 0x50 0x50 0x50 0x50 0x50 0x50 0x50 0x50 0x50 0x50 0x50 0x50 0x50 0x50 0x50 0x50 0x50 0x50 0x50 0x50 0x50 0x50 0x50 0x50 0x50 0x50 0x50 0x50 0x50 0x50 0x50 0x50 0x50 0x50 0x50 0x50 0x50 0x50 0x50 0x50 0x50 0x50 0x50 0x50 0x50 0x50 0x50 0x50 0x50 0x50 0x50 0x50 0x50 0x50 0x50 0x50 0x50 0x50 0x50 0x50 0x50 0x50 0x50 0x50 0x50 0x50 0x50 0x50 0x50 0x50 0x50 0x50 0x50 0x50 0x50 0x50 0x50 0x50 0x50 0x50 0x50 0x50 0x50 0x50 0x50 0x50 0x50 0x50 0x50 0x50 0x50 0x50 0x50 0x50 0x50 0x50 0x50 0x50 0x50 0x50 0x50 0x50 0x50 0x50 0x50 0x50 0x50 0x50 0x50 0x50 0x50 0x50 0x50 0x50 0x50 0x50 0x50 0x50 0x50 0x50 0x50 0x50 0x50 0x50 0x50 0x50 0x50 0x50 0x50 0x50 0x50 0x50 0x50 0x50 0x50 0x50 0x50 0x50 0x50 0x50 0x50 0x50 0x50 0x50 0x50 0x50 0x50 0x50 0x50 0x50 0x50 0x50 0x50 0x50 0x50 0x50 0x50 0x50 0x50 0x50 0x50 0x50 0x50 0x50 0x50 0x50 0x50 0x50 0x50 0x50 0x50 0x50 0x50 0x50 0x50 0x50 0x50 0x50 0x50 0x50 0x50 0x50 0x50 0x50 0x50 0x50 0x50 0x50 0x50 0x50 0x50 0x50 0x50 0x50 0x50 0x50 0x50 0x50 0x50 0x50 0x50 0x50 0x50 0x50 0x50 0x50 0x50 0x50 0x50 0x50 0x50 0x50 0x50 0x50 0x50 0x50 0x50 0x50 0x50 0x50 0x50 0x50 0x50 0x50 0x50 0x50 0x50 0x50 0x50 0x50 0x50 0x50 0x50 0x50 0x50 0x50 0x50 0x50 0x50 0x50 0x50 0x50 0x50 0x50 0x50 0x50 0x50 0x50 0x50 0x50 0x50 0x50 0x50 0x50 0x50 0x50 0x50 0x50 0x50 0x50 0x50 0x50 0x50 0x50 0x50 0x50 0x50 0x50 0x50 0x50 0x50 0x50 0x50 0x50 0x50 0x50 0x50 0x50 0x50 0x50 0x50 0x50 0x50 0x50 0x50 0x50 0x50 0x50 0x50 0x50 0x50 0x50 0x50 0x50 0x50 0x50 0x50 0x50 0x50 0x50 0x50 0x50 0x50 0x50 0x50 0x50 0x50 0x50 0x50 0x50 0x50 0x50 0x50 0x50 0x50 0x50 0x50 0x50 0x50 0x50 0x50 0x50 0x50 0x50 0x50 0x50 0x50 0x50 0x50 0x50 0x50 0x50 0x50 0x50 0x50 0x50 0x50 0x50 0x50 0x50 0x50 0x50 0x50 0x50 0x50 0x50 0x50 0x50 0x50 0x50 0x50 0x50 0x50 0x50 0x50 0x50 0x50 0x50 0x50 0x50 0x50 0x50 0x50 0x50 0x50 0x50 0x50 0x50 0x50 0x50 0x50 0x50 0x50 0x50 0x50 0x50 0x50 0x50 0x50 0x50 0x50 0x50 0x50 0x50 0x50 0x50 0x50 0x50 0x50 0x50 0x50 0x50 0x50 0x50 0x50 0x50 0x50 0x50 0x50 0x50 0x50 0x50 0x50 0x50 0x50 0x50 0x50 0x50 0x50 0x50 0x50 0x50 0x50 0x50 0x50 0x50 0x50 0x50 0x50 0x50 0x50 0x50 0x50 0x50 0x50 0x50 0x50 0x50 0x50 0x50 0x50 0x50 0x50 0x50 0x50 0x50 0x50 0x50 0x50 0x50 0x50 0x50 0x50 0x50 0x50 0x50 0x50 0x50 0x50 0x50 0x50 0x50 0x50 0x50 0x50 0x50 0x50 0x50 0x50 0x50 0x50 0x50 0x50 0x50 0x50 0x50 0x50 0x50 0x50 0x50 0x50 0x50 0x50 0x50 0x50 0x50 0x50 0x50 0x50 0x50 0x50 0x50 0x50 0x50 0x50 0x50 0x50 0x50 0x50 0x50 0x50 0x50 0x50 0x50 0x50 0x50 0x50 0x50 0x50 0x50 0x50 0x50 0x50 0x50 0x50 0x50 0x50 0x50 0x50 0x50 0x50 0x50 0x50 0x50 0x50 0x50 0x50 0x50 0x50 0x50 0x50 0x50 0x50 0x50 0x50 0x50 0x50 0x50 0x50 0x50 0x50 0x50 0x50 0x50 0x50 0x50 0x50 0x50 0x50 0x50 0x50 0x50 0x50 0x50 0x50 0x50 0x50 0x50 0x50 0x50 0x50 0x50 0x50 0x50 0x50 0x50 0x50 0x50 0x50 0x50 0x50 0x50 0x50 0x50 0x50 0x50 0x50 0x50 0x50 0x50 0x50 0x50 0x50 0x50 0x50 0x50 0x50 0x50 0x50 0x50 0x50 0x50 0x50 0x50 0x50 0x50 0x50 0x50 0x50 0x50 0x50 0x50 0x50 0x50 0x50 0x50 0x50 0x50 0x50 0x50 0x50 0x50 0x50 0x50 0x50 0x50 0x50 0x50 0x50 0x50 0x50 0x50 0x50 0x50 0x50 0x50 0x50 0x50 0x50 0x50 0x50 0x50 0x50 0x50 0x50 0x50 0x50 0x50 0x50 0x50 0x50 0x50 0x50 0x50 0x50 0x50 0x50 0x50 0x50 0x50 0x50 0x50 0x50 0x50 0x50 0x50 0x50 0x50 0x50 0x50 0x50 0x50 0x50 0x50 0x50 0x50 0x50 0x50 0x50 0x50 0x50 0x50 0x50 0x50 0x50 0x50 0x50 0x50 0x50 0x50 0x50 0x50 0x50 0x50 0x50 0x50 0x50 0x50 0x50 0x50 0x50 0x50 0x50 0x50 0x50 0x50 0x50 0x50 0x50 0x50 0x50 0x50 0x50 0x50 0x50 0x50 0x50 0x50 0x50 0x50 0x50 0x50 0x50 0x50 0x50 0x50 0x50 0x50 0x50 0x50 0x50 0x50 0x50 0x50 0x50 0x50 0x50 0x50 0x50 0x50 0x50 0x50 0x50 0x50 0x50 0x50 0x50 0x50 0x50 0x50 0x50 0x50 0x50 0x50 0x50 0x50 0x50 0x50 0x50 0x50 0x50 0x50 0x50 0x50 0x50 0x50 0x50 0x50 0x50 0x50 0x50 0x50 0x50 0x50 0x50 0x50 0x50 0x50 0x50 0x50 0x50 0x50 0x50 0x50 0x50 0x50 0x50 0x50 0x50 0x50 0x50 0x50 0x50 0x50 0x50 0x50 0x50 0x50 0x50 0x50 0x50 0x50 0x50 0x50 0x50 0x50 0x50 0x50 0x50 0x50 0x50 0x50 0x50 0x50 0x50 0x50 0x50 0x50 0x50 0x50 0x50 0x50 0x50 0x50 0x50 0x50 0x50 0x50 0x50 0x50 0x50 0x50 0x50 0x50 0x50 0x50 0x50 0x50 0x50 0x50 0x50 0x50 0x50 0x50 0x50 0x50 0x50 0x50 0x50 0x50 0x50 0x50 0x50 0x50 0x50 0x50 0x50 0x50 0x50 0x50 0x50 0x50 0x50 0x50 0x50 0x50 0x50 0x50 0x50 0x50 0x50 0x50 0x50 0x50 0x50 0x50 0x50 0x50 0x50 0x50 0x50 0x50 0x50 0x50 0x50 0x50 0x50 0x50 0x50 0x50 0x50 0x50 0x50 0x50 0x50 0x50 0x50 0x50 0x50 0x50 0x50 0x50 0x50 0x50 0x50 0x50 0x50 0x50 0x50 0x50 0x50 0x50 0x50 0x50 0x50 0x50 0x50 0x50 0x50 0x50 0x50 0x50 0x50 0x50 0x50 0x50 0x50 0x50 0x50 0x50 0x50 0x50 0x50 0x50 0x50 0x50 0x50 0x50 0x50 0x50 0x50 0x50 0x50 0x50 0x50 0x50 0x50 0x50 0x50 0x50 0x50 0x50 0x50 0x50 0x50 0x50 0x50 0x50 0x50 0x50 0x50 0x50 0x50 0x50 0x50 0x50 0x50 0x50 0x50 0x50 0x50 0x50 0x50 0x50 0x50 0x50 0x50 0x50 0x50 0x50 0x50 0x50 0x50 0x50 0x50 0x50 0x50 0x50 0x50 0x50 0x50 0x50 0x50 0x50 0x50 0x50 0x50 0x50 0x50 0x50 0x50 0x50 0x50 0x50 0x50 0x50 0x50 0x50 0x50 0x50 0x50 0x50 0x50 0x50 0x50 0x50 0x50 0x50 0x50 0x50 0x50 0x50 0x50 0x50 0x50 0x50 0x50 0x50 0x50 0x50 0x50 0x50 0x50 0x50 0x50 0x50 0x50 0x50 0x50 0x50 0x50 0x50 0x50 0x50 0x50 0x50 0x50 0x50 0x50 0x50 0x50 0x50 0x50 0x50 0x50 0x50 0x50 0x50 0x50 0x50 0x50 0x50 0x50 0x50 0x50 0x50 0x50 0x50 0x50 0x50 0x50 0x50 0x50 0x50 0x50 0x50 0x50 0x50 0x50 0x50 0x50 0x50 0x50 0x50 0x50 0x50 0x50 0x50 0x50 0x50 0x50 0x50 0x50 0x50 0x50 0x50 0x50 0x50 0x50 0x50 0x50 0x50 0x50 0x50 0x50 0x50 0x50 0x50 0x50 0x50 0x50 0x50 0x50 0x50 0x50 0x50 0x50 0x50 0x50 0x50 0x50 0x50 0x50 0x50 0x50 0x50 0x50 0x50 0x50 0x50 0x50 0x50 0x50 0x50 0x50 0x50 0x50 0x50 0x50 0x50 0x50 0x50 0x50 0x50 0x50 0x50 0x50 0x50 0x50 0x50 0x50 0x50 0x50 0x50 0x50 0x50 0x50 0x50 0x50 0x50 0x50 0x50 0x50 0x50 0x50 0x50 0x50 0x50 0x50>;
				pt11_lo_limits_row_01 = <0x26>;
				pt11_lo_limits_cols_01 = <0x26>;
				pt11_lo_limits_01 = <0xffffffb0 0xffffffb0 0xffffffb0 0xffffffb0 0xffffffb0 0xffffffb0 0xffffffb0 0xffffffb0 0xffffffb0 0xffffffb0 0xffffffb0 0xffffffb0 0xffffffb0 0xffffffb0 0xffffffb0 0xffffffb0 0xffffffb0 0xffffffb0 0xffffffb0 0xffffffb0 0xffffffb0 0xffffffb0 0xffffffb0 0xffffffb0 0xffffffb0 0xffffffb0 0xffffffb0 0xffffffb0 0xffffffb0 0xffffffb0 0xffffffb0 0xffffffb0 0xffffffb0 0xffffffb0 0xffffffb0 0xffffffb0 0xffffffb0 0xffffffb0 0xffffffb0 0xffffffb0 0xffffffb0 0xffffffb0 0xffffffb0 0xffffffb0 0xffffffb0 0xffffffb0 0xffffffb0 0xffffffb0 0xffffffb0 0xffffffb0 0xffffffb0 0xffffffb0 0xffffffb0 0xffffffb0 0xffffffb0 0xffffffb0 0xffffffb0 0xffffffb0 0xffffffb0 0xffffffb0 0xffffffb0 0xffffffb0 0xffffffb0 0xffffffb0 0xffffffb0 0xffffffb0 0xffffffb0 0xffffffb0 0xffffffb0 0xffffffb0 0xffffffb0 0xffffffb0 0xffffffb0 0xffffffb0 0xffffffb0 0xffffffb0 0xffffffb0 0xffffffb0 0xffffffb0 0xffffffb0 0xffffffb0 0xffffffb0 0xffffffb0 0xffffffb0 0xffffffb0 0xffffffb0 0xffffffb0 0xffffffb0 0xffffffb0 0xffffffb0 0xffffffb0 0xffffffb0 0xffffffb0 0xffffffb0 0xffffffb0 0xffffffb0 0xffffffb0 0xffffffb0 0xffffffb0 0xffffffb0 0xffffffb0 0xffffffb0 0xffffffb0 0xffffffb0 0xffffffb0 0xffffffb0 0xffffffb0 0xffffffb0 0xffffffb0 0xffffffb0 0xffffffb0 0xffffffb0 0xffffffb0 0xffffffb0 0xffffffb0 0xffffffb0 0xffffffb0 0xffffffb0 0xffffffb0 0xffffffb0 0xffffffb0 0xffffffb0 0xffffffb0 0xffffffb0 0xffffffb0 0xffffffb0 0xffffffb0 0xffffffb0 0xffffffb0 0xffffffb0 0xffffffb0 0xffffffb0 0xffffffb0 0xffffffb0 0xffffffb0 0xffffffb0 0xffffffb0 0xffffffb0 0xffffffb0 0xffffffb0 0xffffffb0 0xffffffb0 0xffffffb0 0xffffffb0 0xffffffb0 0xffffffb0 0xffffffb0 0xffffffb0 0xffffffb0 0xffffffb0 0xffffffb0 0xffffffb0 0xffffffb0 0xffffffb0 0xffffffb0 0xffffffb0 0xffffffb0 0xffffffb0 0xffffffb0 0xffffffb0 0xffffffb0 0xffffffb0 0xffffffb0 0xffffffb0 0xffffffb0 0xffffffb0 0xffffffb0 0xffffffb0 0xffffffb0 0xffffffb0 0xffffffb0 0xffffffb0 0xffffffb0 0xffffffb0 0xffffffb0 0xffffffb0 0xffffffb0 0xffffffb0 0xffffffb0 0xffffffb0 0xffffffb0 0xffffffb0 0xffffffb0 0xffffffb0 0xffffffb0 0xffffffb0 0xffffffb0 0xffffffb0 0xffffffb0 0xffffffb0 0xffffffb0 0xffffffb0 0xffffffb0 0xffffffb0 0xffffffb0 0xffffffb0 0xffffffb0 0xffffffb0 0xffffffb0 0xffffffb0 0xffffffb0 0xffffffb0 0xffffffb0 0xffffffb0 0xffffffb0 0xffffffb0 0xffffffb0 0xffffffb0 0xffffffb0 0xffffffb0 0xffffffb0 0xffffffb0 0xffffffb0 0xffffffb0 0xffffffb0 0xffffffb0 0xffffffb0 0xffffffb0 0xffffffb0 0xffffffb0 0xffffffb0 0xffffffb0 0xffffffb0 0xffffffb0 0xffffffb0 0xffffffb0 0xffffffb0 0xffffffb0 0xffffffb0 0xffffffb0 0xffffffb0 0xffffffb0 0xffffffb0 0xffffffb0 0xffffffb0 0xffffffb0 0xffffffb0 0xffffffb0 0xffffffb0 0xffffffb0 0xffffffb0 0xffffffb0 0xffffffb0 0xffffffb0 0xffffffb0 0xffffffb0 0xffffffb0 0xffffffb0 0xffffffb0 0xffffffb0 0xffffffb0 0xffffffb0 0xffffffb0 0xffffffb0 0xffffffb0 0xffffffb0 0xffffffb0 0xffffffb0 0xffffffb0 0xffffffb0 0xffffffb0 0xffffffb0 0xffffffb0 0xffffffb0 0xffffffb0 0xffffffb0 0xffffffb0 0xffffffb0 0xffffffb0 0xffffffb0 0xffffffb0 0xffffffb0 0xffffffb0 0xffffffb0 0xffffffb0 0xffffffb0 0xffffffb0 0xffffffb0 0xffffffb0 0xffffffb0 0xffffffb0 0xffffffb0 0xffffffb0 0xffffffb0 0xffffffb0 0xffffffb0 0xffffffb0 0xffffffb0 0xffffffb0 0xffffffb0 0xffffffb0 0xffffffb0 0xffffffb0 0xffffffb0 0xffffffb0 0xffffffb0 0xffffffb0 0xffffffb0 0xffffffb0 0xffffffb0 0xffffffb0 0xffffffb0 0xffffffb0 0xffffffb0 0xffffffb0 0xffffffb0 0xffffffb0 0xffffffb0 0xffffffb0 0xffffffb0 0xffffffb0 0xffffffb0 0xffffffb0 0xffffffb0 0xffffffb0 0xffffffb0 0xffffffb0 0xffffffb0 0xffffffb0 0xffffffb0 0xffffffb0 0xffffffb0 0xffffffb0 0xffffffb0 0xffffffb0 0xffffffb0 0xffffffb0 0xffffffb0 0xffffffb0 0xffffffb0 0xffffffb0 0xffffffb0 0xffffffb0 0xffffffb0 0xffffffb0 0xffffffb0 0xffffffb0 0xffffffb0 0xffffffb0 0xffffffb0 0xffffffb0 0xffffffb0 0xffffffb0 0xffffffb0 0xffffffb0 0xffffffb0 0xffffffb0 0xffffffb0 0xffffffb0 0xffffffb0 0xffffffb0 0xffffffb0 0xffffffb0 0xffffffb0 0xffffffb0 0xffffffb0 0xffffffb0 0xffffffb0 0xffffffb0 0xffffffb0 0xffffffb0 0xffffffb0 0xffffffb0 0xffffffb0 0xffffffb0 0xffffffb0 0xffffffb0 0xffffffb0 0xffffffb0 0xffffffb0 0xffffffb0 0xffffffb0 0xffffffb0 0xffffffb0 0xffffffb0 0xffffffb0 0xffffffb0 0xffffffb0 0xffffffb0 0xffffffb0 0xffffffb0 0xffffffb0 0xffffffb0 0xffffffb0 0xffffffb0 0xffffffb0 0xffffffb0 0xffffffb0 0xffffffb0 0xffffffb0 0xffffffb0 0xffffffb0 0xffffffb0 0xffffffb0 0xffffffb0 0xffffffb0 0xffffffb0 0xffffffb0 0xffffffb0 0xffffffb0 0xffffffb0 0xffffffb0 0xffffffb0 0xffffffb0 0xffffffb0 0xffffffb0 0xffffffb0 0xffffffb0 0xffffffb0 0xffffffb0 0xffffffb0 0xffffffb0 0xffffffb0 0xffffffb0 0xffffffb0 0xffffffb0 0xffffffb0 0xffffffb0 0xffffffb0 0xffffffb0 0xffffffb0 0xffffffb0 0xffffffb0 0xffffffb0 0xffffffb0 0xffffffb0 0xffffffb0 0xffffffb0 0xffffffb0 0xffffffb0 0xffffffb0 0xffffffb0 0xffffffb0 0xffffffb0 0xffffffb0 0xffffffb0 0xffffffb0 0xffffffb0 0xffffffb0 0xffffffb0 0xffffffb0 0xffffffb0 0xffffffb0 0xffffffb0 0xffffffb0 0xffffffb0 0xffffffb0 0xffffffb0 0xffffffb0 0xffffffb0 0xffffffb0 0xffffffb0 0xffffffb0 0xffffffb0 0xffffffb0 0xffffffb0 0xffffffb0 0xffffffb0 0xffffffb0 0xffffffb0 0xffffffb0 0xffffffb0 0xffffffb0 0xffffffb0 0xffffffb0 0xffffffb0 0xffffffb0 0xffffffb0 0xffffffb0 0xffffffb0 0xffffffb0 0xffffffb0 0xffffffb0 0xffffffb0 0xffffffb0 0xffffffb0 0xffffffb0 0xffffffb0 0xffffffb0 0xffffffb0 0xffffffb0 0xffffffb0 0xffffffb0 0xffffffb0 0xffffffb0 0xffffffb0 0xffffffb0 0xffffffb0 0xffffffb0 0xffffffb0 0xffffffb0 0xffffffb0 0xffffffb0 0xffffffb0 0xffffffb0 0xffffffb0 0xffffffb0 0xffffffb0 0xffffffb0 0xffffffb0 0xffffffb0 0xffffffb0 0xffffffb0 0xffffffb0 0xffffffb0 0xffffffb0 0xffffffb0 0xffffffb0 0xffffffb0 0xffffffb0 0xffffffb0 0xffffffb0 0xffffffb0 0xffffffb0 0xffffffb0 0xffffffb0 0xffffffb0 0xffffffb0 0xffffffb0 0xffffffb0 0xffffffb0 0xffffffb0 0xffffffb0 0xffffffb0 0xffffffb0 0xffffffb0 0xffffffb0 0xffffffb0 0xffffffb0 0xffffffb0 0xffffffb0 0xffffffb0 0xffffffb0 0xffffffb0 0xffffffb0 0xffffffb0 0xffffffb0 0xffffffb0 0xffffffb0 0xffffffb0 0xffffffb0 0xffffffb0 0xffffffb0 0xffffffb0 0xffffffb0 0xffffffb0 0xffffffb0 0xffffffb0 0xffffffb0 0xffffffb0 0xffffffb0 0xffffffb0 0xffffffb0 0xffffffb0 0xffffffb0 0xffffffb0 0xffffffb0 0xffffffb0 0xffffffb0 0xffffffb0 0xffffffb0 0xffffffb0 0xffffffb0 0xffffffb0 0xffffffb0 0xffffffb0 0xffffffb0 0xffffffb0 0xffffffb0 0xffffffb0 0xffffffb0 0xffffffb0 0xffffffb0 0xffffffb0 0xffffffb0 0xffffffb0 0xffffffb0 0xffffffb0 0xffffffb0 0xffffffb0 0xffffffb0 0xffffffb0 0xffffffb0 0xffffffb0 0xffffffb0 0xffffffb0 0xffffffb0 0xffffffb0 0xffffffb0 0xffffffb0 0xffffffb0 0xffffffb0 0xffffffb0 0xffffffb0 0xffffffb0 0xffffffb0 0xffffffb0 0xffffffb0 0xffffffb0 0xffffffb0 0xffffffb0 0xffffffb0 0xffffffb0 0xffffffb0 0xffffffb0 0xffffffb0 0xffffffb0 0xffffffb0 0xffffffb0 0xffffffb0 0xffffffb0 0xffffffb0 0xffffffb0 0xffffffb0 0xffffffb0 0xffffffb0 0xffffffb0 0xffffffb0 0xffffffb0 0xffffffb0 0xffffffb0 0xffffffb0 0xffffffb0 0xffffffb0 0xffffffb0 0xffffffb0 0xffffffb0 0xffffffb0 0xffffffb0 0xffffffb0 0xffffffb0 0xffffffb0 0xffffffb0 0xffffffb0 0xffffffb0 0xffffffb0 0xffffffb0 0xffffffb0 0xffffffb0 0xffffffb0 0xffffffb0 0xffffffb0 0xffffffb0 0xffffffb0 0xffffffb0 0xffffffb0 0xffffffb0 0xffffffb0 0xffffffb0 0xffffffb0 0xffffffb0 0xffffffb0 0xffffffb0 0xffffffb0 0xffffffb0 0xffffffb0 0xffffffb0 0xffffffb0 0xffffffb0 0xffffffb0 0xffffffb0 0xffffffb0 0xffffffb0 0xffffffb0 0xffffffb0 0xffffffb0 0xffffffb0 0xffffffb0 0xffffffb0 0xffffffb0 0xffffffb0 0xffffffb0 0xffffffb0 0xffffffb0 0xffffffb0 0xffffffb0 0xffffffb0 0xffffffb0 0xffffffb0 0xffffffb0 0xffffffb0 0xffffffb0 0xffffffb0 0xffffffb0 0xffffffb0 0xffffffb0 0xffffffb0 0xffffffb0 0xffffffb0 0xffffffb0 0xffffffb0 0xffffffb0 0xffffffb0 0xffffffb0 0xffffffb0 0xffffffb0 0xffffffb0 0xffffffb0 0xffffffb0 0xffffffb0 0xffffffb0 0xffffffb0 0xffffffb0 0xffffffb0 0xffffffb0 0xffffffb0 0xffffffb0 0xffffffb0 0xffffffb0 0xffffffb0 0xffffffb0 0xffffffb0 0xffffffb0 0xffffffb0 0xffffffb0 0xffffffb0 0xffffffb0 0xffffffb0 0xffffffb0 0xffffffb0 0xffffffb0 0xffffffb0 0xffffffb0 0xffffffb0 0xffffffb0 0xffffffb0 0xffffffb0 0xffffffb0 0xffffffb0 0xffffffb0 0xffffffb0 0xffffffb0 0xffffffb0 0xffffffb0 0xffffffb0 0xffffffb0 0xffffffb0 0xffffffb0 0xffffffb0 0xffffffb0 0xffffffb0 0xffffffb0 0xffffffb0 0xffffffb0 0xffffffb0 0xffffffb0 0xffffffb0 0xffffffb0 0xffffffb0 0xffffffb0 0xffffffb0 0xffffffb0 0xffffffb0 0xffffffb0 0xffffffb0 0xffffffb0 0xffffffb0 0xffffffb0 0xffffffb0 0xffffffb0 0xffffffb0 0xffffffb0 0xffffffb0 0xffffffb0 0xffffffb0 0xffffffb0 0xffffffb0 0xffffffb0 0xffffffb0 0xffffffb0 0xffffffb0 0xffffffb0 0xffffffb0 0xffffffb0 0xffffffb0 0xffffffb0 0xffffffb0 0xffffffb0 0xffffffb0 0xffffffb0 0xffffffb0 0xffffffb0 0xffffffb0 0xffffffb0 0xffffffb0 0xffffffb0 0xffffffb0 0xffffffb0 0xffffffb0 0xffffffb0 0xffffffb0 0xffffffb0 0xffffffb0 0xffffffb0 0xffffffb0 0xffffffb0 0xffffffb0 0xffffffb0 0xffffffb0 0xffffffb0 0xffffffb0 0xffffffb0 0xffffffb0 0xffffffb0 0xffffffb0 0xffffffb0 0xffffffb0 0xffffffb0 0xffffffb0 0xffffffb0 0xffffffb0 0xffffffb0 0xffffffb0 0xffffffb0 0xffffffb0 0xffffffb0 0xffffffb0 0xffffffb0 0xffffffb0 0xffffffb0 0xffffffb0 0xffffffb0 0xffffffb0 0xffffffb0 0xffffffb0 0xffffffb0 0xffffffb0 0xffffffb0 0xffffffb0 0xffffffb0 0xffffffb0 0xffffffb0 0xffffffb0 0xffffffb0 0xffffffb0 0xffffffb0 0xffffffb0 0xffffffb0 0xffffffb0 0xffffffb0 0xffffffb0 0xffffffb0 0xffffffb0 0xffffffb0 0xffffffb0 0xffffffb0 0xffffffb0 0xffffffb0 0xffffffb0 0xffffffb0 0xffffffb0 0xffffffb0 0xffffffb0 0xffffffb0 0xffffffb0 0xffffffb0 0xffffffb0 0xffffffb0 0xffffffb0 0xffffffb0 0xffffffb0 0xffffffb0 0xffffffb0 0xffffffb0 0xffffffb0 0xffffffb0 0xffffffb0 0xffffffb0 0xffffffb0 0xffffffb0 0xffffffb0 0xffffffb0 0xffffffb0 0xffffffb0 0xffffffb0 0xffffffb0 0xffffffb0 0xffffffb0 0xffffffb0 0xffffffb0 0xffffffb0 0xffffffb0 0xffffffb0 0xffffffb0 0xffffffb0 0xffffffb0 0xffffffb0 0xffffffb0 0xffffffb0 0xffffffb0 0xffffffb0 0xffffffb0 0xffffffb0 0xffffffb0 0xffffffb0 0xffffffb0 0xffffffb0 0xffffffb0 0xffffffb0 0xffffffb0 0xffffffb0 0xffffffb0 0xffffffb0 0xffffffb0 0xffffffb0 0xffffffb0 0xffffffb0 0xffffffb0 0xffffffb0 0xffffffb0 0xffffffb0 0xffffffb0 0xffffffb0 0xffffffb0 0xffffffb0 0xffffffb0 0xffffffb0 0xffffffb0 0xffffffb0 0xffffffb0 0xffffffb0 0xffffffb0 0xffffffb0 0xffffffb0 0xffffffb0 0xffffffb0 0xffffffb0 0xffffffb0 0xffffffb0 0xffffffb0 0xffffffb0 0xffffffb0 0xffffffb0 0xffffffb0 0xffffffb0 0xffffffb0 0xffffffb0 0xffffffb0 0xffffffb0 0xffffffb0 0xffffffb0 0xffffffb0 0xffffffb0 0xffffffb0 0xffffffb0 0xffffffb0 0xffffffb0 0xffffffb0 0xffffffb0 0xffffffb0 0xffffffb0 0xffffffb0 0xffffffb0 0xffffffb0 0xffffffb0 0xffffffb0 0xffffffb0 0xffffffb0 0xffffffb0 0xffffffb0 0xffffffb0 0xffffffb0 0xffffffb0 0xffffffb0 0xffffffb0 0xffffffb0 0xffffffb0 0xffffffb0 0xffffffb0 0xffffffb0 0xffffffb0 0xffffffb0 0xffffffb0 0xffffffb0 0xffffffb0 0xffffffb0 0xffffffb0 0xffffffb0 0xffffffb0 0xffffffb0 0xffffffb0 0xffffffb0 0xffffffb0 0xffffffb0 0xffffffb0 0xffffffb0 0xffffffb0 0xffffffb0 0xffffffb0 0xffffffb0 0xffffffb0 0xffffffb0 0xffffffb0 0xffffffb0 0xffffffb0 0xffffffb0 0xffffffb0 0xffffffb0 0xffffffb0 0xffffffb0 0xffffffb0 0xffffffb0 0xffffffb0 0xffffffb0 0xffffffb0 0xffffffb0 0xffffffb0 0xffffffb0 0xffffffb0 0xffffffb0 0xffffffb0 0xffffffb0 0xffffffb0 0xffffffb0 0xffffffb0 0xffffffb0 0xffffffb0 0xffffffb0 0xffffffb0 0xffffffb0 0xffffffb0 0xffffffb0 0xffffffb0 0xffffffb0 0xffffffb0 0xffffffb0 0xffffffb0 0xffffffb0 0xffffffb0 0xffffffb0 0xffffffb0 0xffffffb0 0xffffffb0 0xffffffb0 0xffffffb0 0xffffffb0 0xffffffb0 0xffffffb0 0xffffffb0 0xffffffb0 0xffffffb0 0xffffffb0 0xffffffb0 0xffffffb0 0xffffffb0 0xffffffb0 0xffffffb0 0xffffffb0 0xffffffb0 0xffffffb0 0xffffffb0 0xffffffb0 0xffffffb0 0xffffffb0 0xffffffb0 0xffffffb0 0xffffffb0 0xffffffb0 0xffffffb0 0xffffffb0 0xffffffb0 0xffffffb0 0xffffffb0 0xffffffb0 0xffffffb0 0xffffffb0 0xffffffb0 0xffffffb0 0xffffffb0 0xffffffb0 0xffffffb0 0xffffffb0 0xffffffb0 0xffffffb0 0xffffffb0 0xffffffb0 0xffffffb0 0xffffffb0 0xffffffb0 0xffffffb0 0xffffffb0 0xffffffb0 0xffffffb0 0xffffffb0 0xffffffb0 0xffffffb0 0xffffffb0 0xffffffb0 0xffffffb0 0xffffffb0 0xffffffb0 0xffffffb0 0xffffffb0 0xffffffb0 0xffffffb0 0xffffffb0 0xffffffb0 0xffffffb0 0xffffffb0 0xffffffb0 0xffffffb0 0xffffffb0 0xffffffb0 0xffffffb0 0xffffffb0 0xffffffb0 0xffffffb0 0xffffffb0 0xffffffb0 0xffffffb0 0xffffffb0 0xffffffb0 0xffffffb0 0xffffffb0 0xffffffb0 0xffffffb0 0xffffffb0 0xffffffb0 0xffffffb0 0xffffffb0 0xffffffb0 0xffffffb0 0xffffffb0 0xffffffb0 0xffffffb0 0xffffffb0 0xffffffb0 0xffffffb0 0xffffffb0 0xffffffb0 0xffffffb0 0xffffffb0 0xffffffb0 0xffffffb0 0xffffffb0 0xffffffb0 0xffffffb0 0xffffffb0 0xffffffb0 0xffffffb0 0xffffffb0 0xffffffb0 0xffffffb0 0xffffffb0 0xffffffb0 0xffffffb0 0xffffffb0 0xffffffb0 0xffffffb0 0xffffffb0 0xffffffb0 0xffffffb0 0xffffffb0 0xffffffb0 0xffffffb0 0xffffffb0 0xffffffb0 0xffffffb0 0xffffffb0 0xffffffb0 0xffffffb0 0xffffffb0 0xffffffb0 0xffffffb0 0xffffffb0 0xffffffb0 0xffffffb0 0xffffffb0 0xffffffb0 0xffffffb0 0xffffffb0 0xffffffb0 0xffffffb0 0xffffffb0 0xffffffb0 0xffffffb0 0xffffffb0 0xffffffb0 0xffffffb0 0xffffffb0 0xffffffb0 0xffffffb0 0xffffffb0 0xffffffb0 0xffffffb0 0xffffffb0 0xffffffb0 0xffffffb0 0xffffffb0 0xffffffb0 0xffffffb0 0xffffffb0 0xffffffb0 0xffffffb0 0xffffffb0 0xffffffb0 0xffffffb0 0xffffffb0 0xffffffb0 0xffffffb0 0xffffffb0 0xffffffb0 0xffffffb0 0xffffffb0 0xffffffb0 0xffffffb0 0xffffffb0 0xffffffb0 0xffffffb0 0xffffffb0 0xffffffb0 0xffffffb0 0xffffffb0 0xffffffb0 0xffffffb0 0xffffffb0 0xffffffb0 0xffffffb0 0xffffffb0 0xffffffb0 0xffffffb0 0xffffffb0 0xffffffb0 0xffffffb0 0xffffffb0 0xffffffb0 0xffffffb0 0xffffffb0 0xffffffb0 0xffffffb0 0xffffffb0 0xffffffb0 0xffffffb0 0xffffffb0 0xffffffb0 0xffffffb0 0xffffffb0 0xffffffb0 0xffffffb0 0xffffffb0 0xffffffb0 0xffffffb0 0xffffffb0 0xffffffb0 0xffffffb0 0xffffffb0 0xffffffb0 0xffffffb0 0xffffffb0 0xffffffb0 0xffffffb0 0xffffffb0 0xffffffb0 0xffffffb0 0xffffffb0 0xffffffb0 0xffffffb0 0xffffffb0 0xffffffb0 0xffffffb0 0xffffffb0 0xffffffb0 0xffffffb0 0xffffffb0 0xffffffb0 0xffffffb0 0xffffffb0 0xffffffb0 0xffffffb0 0xffffffb0 0xffffffb0 0xffffffb0 0xffffffb0 0xffffffb0 0xffffffb0 0xffffffb0 0xffffffb0 0xffffffb0 0xffffffb0 0xffffffb0 0xffffffb0 0xffffffb0 0xffffffb0 0xffffffb0 0xffffffb0 0xffffffb0 0xffffffb0 0xffffffb0 0xffffffb0 0xffffffb0 0xffffffb0 0xffffffb0 0xffffffb0 0xffffffb0 0xffffffb0 0xffffffb0 0xffffffb0 0xffffffb0 0xffffffb0 0xffffffb0 0xffffffb0 0xffffffb0 0xffffffb0 0xffffffb0 0xffffffb0 0xffffffb0 0xffffffb0 0xffffffb0 0xffffffb0 0xffffffb0 0xffffffb0 0xffffffb0 0xffffffb0 0xffffffb0 0xffffffb0 0xffffffb0 0xffffffb0 0xffffffb0 0xffffffb0 0xffffffb0 0xffffffb0 0xffffffb0 0xffffffb0 0xffffffb0 0xffffffb0 0xffffffb0 0xffffffb0 0xffffffb0 0xffffffb0 0xffffffb0 0xffffffb0 0xffffffb0 0xffffffb0 0xffffffb0 0xffffffb0 0xffffffb0 0xffffffb0 0xffffffb0 0xffffffb0 0xffffffb0 0xffffffb0 0xffffffb0 0xffffffb0 0xffffffb0 0xffffffb0 0xffffffb0 0xffffffb0 0xffffffb0 0xffffffb0 0xffffffb0 0xffffffb0 0xffffffb0 0xffffffb0 0xffffffb0 0xffffffb0 0xffffffb0 0xffffffb0 0xffffffb0 0xffffffb0 0xffffffb0 0xffffffb0 0xffffffb0 0xffffffb0 0xffffffb0 0xffffffb0 0xffffffb0 0xffffffb0 0xffffffb0 0xffffffb0 0xffffffb0 0xffffffb0 0xffffffb0 0xffffffb0 0xffffffb0 0xffffffb0 0xffffffb0 0xffffffb0 0xffffffb0 0xffffffb0 0xffffffb0 0xffffffb0 0xffffffb0 0xffffffb0 0xffffffb0 0xffffffb0 0xffffffb0 0xffffffb0 0xffffffb0 0xffffffb0 0xffffffb0 0xffffffb0 0xffffffb0 0xffffffb0 0xffffffb0 0xffffffb0 0xffffffb0 0xffffffb0 0xffffffb0 0xffffffb0 0xffffffb0 0xffffffb0 0xffffffb0 0xffffffb0 0xffffffb0 0xffffffb0 0xffffffb0 0xffffffb0 0xffffffb0 0xffffffb0 0xffffffb0 0xffffffb0 0xffffffb0 0xffffffb0 0xffffffb0 0xffffffb0 0xffffffb0 0xffffffb0 0xffffffb0 0xffffffb0 0xffffffb0 0xffffffb0 0xffffffb0 0xffffffb0 0xffffffb0 0xffffffb0 0xffffffb0 0xffffffb0 0xffffffb0 0xffffffb0 0xffffffb0 0xffffffb0 0xffffffb0 0xffffffb0 0xffffffb0 0xffffffb0 0xffffffb0 0xffffffb0 0xffffffb0 0xffffffb0 0xffffffb0 0xffffffb0 0xffffffb0 0xffffffb0 0xffffffb0>;
				pt7_hi_limits_row_02 = <0x26>;
				pt7_hi_limits_cols_02 = <0x26>;
				pt7_hi_limits_02 = <0x5dc 0x5dc 0x5dc 0x5dc 0x5dc 0x5dc 0x5dc 0x5dc 0x5dc 0x5dc 0x5dc 0x5dc 0x5dc 0x5dc 0x5dc 0x5dc 0x5dc 0x5dc 0x5dc 0x5dc 0x5dc 0x5dc 0x5dc 0x5dc 0x5dc 0x5dc 0x5dc 0x5dc 0x5dc 0x5dc 0x5dc 0x5dc 0x5dc 0x5dc 0x5dc 0x5dc 0x5dc 0x5dc 0x5dc 0x5dc 0x5dc 0x5dc 0x5dc 0x5dc 0x5dc 0x5dc 0x5dc 0x5dc 0x5dc 0x5dc 0x5dc 0x5dc 0x5dc 0x5dc 0x5dc 0x5dc 0x5dc 0x5dc 0x5dc 0x5dc 0x5dc 0x5dc 0x5dc 0x5dc 0x5dc 0x5dc 0x5dc 0x5dc 0x5dc 0x5dc 0x5dc 0x5dc 0x5dc 0x5dc 0x5dc 0x5dc 0x5dc 0x5dc 0x5dc 0x5dc 0x5dc 0x5dc 0x5dc 0x5dc 0x5dc 0x5dc 0x5dc 0x5dc 0x5dc 0x5dc 0x5dc 0x5dc 0x5dc 0x5dc 0x5dc 0x5dc 0x5dc 0x5dc 0x5dc 0x5dc 0x5dc 0x5dc 0x5dc 0x5dc 0x5dc 0x5dc 0x5dc 0x5dc 0x5dc 0x5dc 0x5dc 0x5dc 0x5dc 0x5dc 0x5dc 0x5dc 0x5dc 0x5dc 0x5dc 0x5dc 0x5dc 0x5dc 0x5dc 0x5dc 0x5dc 0x5dc 0x5dc 0x5dc 0x5dc 0x5dc 0x5dc 0x5dc 0x5dc 0x5dc 0x5dc 0x5dc 0x5dc 0x5dc 0x5dc 0x5dc 0x5dc 0x5dc 0x5dc 0x5dc 0x5dc 0x5dc 0x5dc 0x5dc 0x5dc 0x5dc 0x5dc 0x5dc 0x5dc 0x5dc 0x5dc 0x5dc 0x5dc 0x5dc 0x5dc 0x5dc 0x5dc 0x5dc 0x5dc 0x5dc 0x5dc 0x5dc 0x5dc 0x5dc 0x5dc 0x5dc 0x5dc 0x5dc 0x5dc 0x5dc 0x5dc 0x5dc 0x5dc 0x5dc 0x5dc 0x5dc 0x5dc 0x5dc 0x5dc 0x5dc 0x5dc 0x5dc 0x5dc 0x5dc 0x5dc 0x5dc 0x5dc 0x5dc 0x5dc 0x5dc 0x5dc 0x5dc 0x5dc 0x5dc 0x5dc 0x5dc 0x5dc 0x5dc 0x5dc 0x5dc 0x5dc 0x5dc 0x5dc 0x5dc 0x5dc 0x5dc 0x5dc 0x5dc 0x5dc 0x5dc 0x5dc 0x5dc 0x5dc 0x5dc 0x5dc 0x5dc 0x5dc 0x5dc 0x5dc 0x5dc 0x5dc 0x5dc 0x5dc 0x5dc 0x5dc 0x5dc 0x5dc 0x5dc 0x5dc 0x5dc 0x5dc 0x5dc 0x5dc 0x5dc 0x5dc 0x5dc 0x5dc 0x5dc 0x5dc 0x5dc 0x5dc 0x5dc 0x5dc 0x5dc 0x5dc 0x5dc 0x5dc 0x5dc 0x5dc 0x5dc 0x5dc 0x5dc 0x5dc 0x5dc 0x5dc 0x5dc 0x5dc 0x5dc 0x5dc 0x5dc 0x5dc 0x5dc 0x5dc 0x5dc 0x5dc 0x5dc 0x5dc 0x5dc 0x5dc 0x5dc 0x5dc 0x5dc 0x5dc 0x5dc 0x5dc 0x5dc 0x5dc 0x5dc 0x5dc 0x5dc 0x5dc 0x5dc 0x5dc 0x5dc 0x5dc 0x5dc 0x5dc 0x5dc 0x5dc 0x5dc 0x5dc 0x5dc 0x5dc 0x5dc 0x5dc 0x5dc 0x5dc 0x5dc 0x5dc 0x5dc 0x5dc 0x5dc 0x5dc 0x5dc 0x5dc 0x5dc 0x5dc 0x5dc 0x5dc 0x5dc 0x5dc 0x5dc 0x5dc 0x5dc 0x5dc 0x5dc 0x5dc 0x5dc 0x5dc 0x5dc 0x5dc 0x5dc 0x5dc 0x5dc 0x5dc 0x5dc 0x5dc 0x5dc 0x5dc 0x5dc 0x5dc 0x5dc 0x5dc 0x5dc 0x5dc 0x5dc 0x5dc 0x5dc 0x5dc 0x5dc 0x5dc 0x5dc 0x5dc 0x5dc 0x5dc 0x5dc 0x5dc 0x5dc 0x5dc 0x5dc 0x5dc 0x5dc 0x5dc 0x5dc 0x5dc 0x5dc 0x5dc 0x5dc 0x5dc 0x5dc 0x5dc 0x5dc 0x5dc 0x5dc 0x5dc 0x5dc 0x5dc 0x5dc 0x5dc 0x5dc 0x5dc 0x5dc 0x5dc 0x5dc 0x5dc 0x5dc 0x5dc 0x5dc 0x5dc 0x5dc 0x5dc 0x5dc 0x5dc 0x5dc 0x5dc 0x5dc 0x5dc 0x5dc 0x5dc 0x5dc 0x5dc 0x5dc 0x5dc 0x5dc 0x5dc 0x5dc 0x5dc 0x5dc 0x5dc 0x5dc 0x5dc 0x5dc 0x5dc 0x5dc 0x5dc 0x5dc 0x5dc 0x5dc 0x5dc 0x5dc 0x5dc 0x5dc 0x5dc 0x5dc 0x5dc 0x5dc 0x5dc 0x5dc 0x5dc 0x5dc 0x5dc 0x5dc 0x5dc 0x5dc 0x5dc 0x5dc 0x5dc 0x5dc 0x5dc 0x5dc 0x5dc 0x5dc 0x5dc 0x5dc 0x5dc 0x5dc 0x5dc 0x5dc 0x5dc 0x5dc 0x5dc 0x5dc 0x5dc 0x5dc 0x5dc 0x5dc 0x5dc 0x5dc 0x5dc 0x5dc 0x5dc 0x5dc 0x5dc 0x5dc 0x5dc 0x5dc 0x5dc 0x5dc 0x5dc 0x5dc 0x5dc 0x5dc 0x5dc 0x5dc 0x5dc 0x5dc 0x5dc 0x5dc 0x5dc 0x5dc 0x5dc 0x5dc 0x5dc 0x5dc 0x5dc 0x5dc 0x5dc 0x5dc 0x5dc 0x5dc 0x5dc 0x5dc 0x5dc 0x5dc 0x5dc 0x5dc 0x5dc 0x5dc 0x5dc 0x5dc 0x5dc 0x5dc 0x5dc 0x5dc 0x5dc 0x5dc 0x5dc 0x5dc 0x5dc 0x5dc 0x5dc 0x5dc 0x5dc 0x5dc 0x5dc 0x5dc 0x5dc 0x5dc 0x5dc 0x5dc 0x5dc 0x5dc 0x5dc 0x5dc 0x5dc 0x5dc 0x5dc 0x5dc 0x5dc 0x5dc 0x5dc 0x5dc 0x5dc 0x5dc 0x5dc 0x5dc 0x5dc 0x5dc 0x5dc 0x5dc 0x5dc 0x5dc 0x5dc 0x5dc 0x5dc 0x5dc 0x5dc 0x5dc 0x5dc 0x5dc 0x5dc 0x5dc 0x5dc 0x5dc 0x5dc 0x5dc 0x5dc 0x5dc 0x5dc 0x5dc 0x5dc 0x5dc 0x5dc 0x5dc 0x5dc 0x5dc 0x5dc 0x5dc 0x5dc 0x5dc 0x5dc 0x5dc 0x5dc 0x5dc 0x5dc 0x5dc 0x5dc 0x5dc 0x5dc 0x5dc 0x5dc 0x5dc 0x5dc 0x5dc 0x5dc 0x5dc 0x5dc 0x5dc 0x5dc 0x5dc 0x5dc 0x5dc 0x5dc 0x5dc 0x5dc 0x5dc 0x5dc 0x5dc 0x5dc 0x5dc 0x5dc 0x5dc 0x5dc 0x5dc 0x5dc 0x5dc 0x5dc 0x5dc 0x5dc 0x5dc 0x5dc 0x5dc 0x5dc 0x5dc 0x5dc 0x5dc 0x5dc 0x5dc 0x5dc 0x5dc 0x5dc 0x5dc 0x5dc 0x5dc 0x5dc 0x5dc 0x5dc 0x5dc 0x5dc 0x5dc 0x5dc 0x5dc 0x5dc 0x5dc 0x5dc 0x5dc 0x5dc 0x5dc 0x5dc 0x5dc 0x5dc 0x5dc 0x5dc 0x5dc 0x5dc 0x5dc 0x5dc 0x5dc 0x5dc 0x5dc 0x5dc 0x5dc 0x5dc 0x5dc 0x5dc 0x5dc 0x5dc 0x5dc 0x5dc 0x5dc 0x5dc 0x5dc 0x5dc 0x5dc 0x5dc 0x5dc 0x5dc 0x5dc 0x5dc 0x5dc 0x5dc 0x5dc 0x5dc 0x5dc 0x5dc 0x5dc 0x5dc 0x5dc 0x5dc 0x5dc 0x5dc 0x5dc 0x5dc 0x5dc 0x5dc 0x5dc 0x5dc 0x5dc 0x5dc 0x5dc 0x5dc 0x5dc 0x5dc 0x5dc 0x5dc 0x5dc 0x5dc 0x5dc 0x5dc 0x5dc 0x5dc 0x5dc 0x5dc 0x5dc 0x5dc 0x5dc 0x5dc 0x5dc 0x5dc 0x5dc 0x5dc 0x5dc 0x5dc 0x5dc 0x5dc 0x5dc 0x5dc 0x5dc 0x5dc 0x5dc 0x5dc 0x5dc 0x5dc 0x5dc 0x5dc 0x5dc 0x5dc 0x5dc 0x5dc 0x5dc 0x5dc 0x5dc 0x5dc 0x5dc 0x5dc 0x5dc 0x5dc 0x5dc 0x5dc 0x5dc 0x5dc 0x5dc 0x5dc 0x5dc 0x5dc 0x5dc 0x5dc 0x5dc 0x5dc 0x5dc 0x5dc 0x5dc 0x5dc 0x5dc 0x5dc 0x5dc 0x5dc 0x5dc 0x5dc 0x5dc 0x5dc 0x5dc 0x5dc 0x5dc 0x5dc 0x5dc 0x5dc 0x5dc 0x5dc 0x5dc 0x5dc 0x5dc 0x5dc 0x5dc 0x5dc 0x5dc 0x5dc 0x5dc 0x5dc 0x5dc 0x5dc 0x5dc 0x5dc 0x5dc 0x5dc 0x5dc 0x5dc 0x5dc 0x5dc 0x5dc 0x5dc 0x5dc 0x5dc 0x5dc 0x5dc 0x5dc 0x5dc 0x5dc 0x5dc 0x5dc 0x5dc 0x5dc 0x5dc 0x5dc 0x5dc 0x5dc 0x5dc 0x5dc 0x5dc 0x5dc 0x5dc 0x5dc 0x5dc 0x5dc 0x5dc 0x5dc 0x5dc 0x5dc 0x5dc 0x5dc 0x5dc 0x5dc 0x5dc 0x5dc 0x5dc 0x5dc 0x5dc 0x5dc 0x5dc 0x5dc 0x5dc 0x5dc 0x5dc 0x5dc 0x5dc 0x5dc 0x5dc 0x5dc 0x5dc 0x5dc 0x5dc 0x5dc 0x5dc 0x5dc 0x5dc 0x5dc 0x5dc 0x5dc 0x5dc 0x5dc 0x5dc 0x5dc 0x5dc 0x5dc 0x5dc 0x5dc 0x5dc 0x5dc 0x5dc 0x5dc 0x5dc 0x5dc 0x5dc 0x5dc 0x5dc 0x5dc 0x5dc 0x5dc 0x5dc 0x5dc 0x5dc 0x5dc 0x5dc 0x5dc 0x5dc 0x5dc 0x5dc 0x5dc 0x5dc 0x5dc 0x5dc 0x5dc 0x5dc 0x5dc 0x5dc 0x5dc 0x5dc 0x5dc 0x5dc 0x5dc 0x5dc 0x5dc 0x5dc 0x5dc 0x5dc 0x5dc 0x5dc 0x5dc 0x5dc 0x5dc 0x5dc 0x5dc 0x5dc 0x5dc 0x5dc 0x5dc 0x5dc 0x5dc 0x5dc 0x5dc 0x5dc 0x5dc 0x5dc 0x5dc 0x5dc 0x5dc 0x5dc 0x5dc 0x5dc 0x5dc 0x5dc 0x5dc 0x5dc 0x5dc 0x5dc 0x5dc 0x5dc 0x5dc 0x5dc 0x5dc 0x5dc 0x5dc 0x5dc 0x5dc 0x5dc 0x5dc 0x5dc 0x5dc 0x5dc 0x5dc 0x5dc 0x5dc 0x5dc 0x5dc 0x5dc 0x5dc 0x5dc 0x5dc 0x5dc 0x5dc 0x5dc 0x5dc 0x5dc 0x5dc 0x5dc 0x5dc 0x5dc 0x5dc 0x5dc 0x5dc 0x5dc 0x5dc 0x5dc 0x5dc 0x5dc 0x5dc 0x5dc 0x5dc 0x5dc 0x5dc 0x5dc 0x5dc 0x5dc 0x5dc 0x5dc 0x5dc 0x5dc 0x5dc 0x5dc 0x5dc 0x5dc 0x5dc 0x5dc 0x5dc 0x5dc 0x5dc 0x5dc 0x5dc 0x5dc 0x5dc 0x5dc 0x5dc 0x5dc 0x5dc 0x5dc 0x5dc 0x5dc 0x5dc 0x5dc 0x5dc 0x5dc 0x5dc 0x5dc 0x5dc 0x5dc 0x5dc 0x5dc 0x5dc 0x5dc 0x5dc 0x5dc 0x5dc 0x5dc 0x5dc 0x5dc 0x5dc 0x5dc 0x5dc 0x5dc 0x5dc 0x5dc 0x5dc 0x5dc 0x5dc 0x5dc 0x5dc 0x5dc 0x5dc 0x5dc 0x5dc 0x5dc 0x5dc 0x5dc 0x5dc 0x5dc 0x5dc 0x5dc 0x5dc 0x5dc 0x5dc 0x5dc 0x5dc 0x5dc 0x5dc 0x5dc 0x5dc 0x5dc 0x5dc 0x5dc 0x5dc 0x5dc 0x5dc 0x5dc 0x5dc 0x5dc 0x5dc 0x5dc 0x5dc 0x5dc 0x5dc 0x5dc 0x5dc 0x5dc 0x5dc 0x5dc 0x5dc 0x5dc 0x5dc 0x5dc 0x5dc 0x5dc 0x5dc 0x5dc 0x5dc 0x5dc 0x5dc 0x5dc 0x5dc 0x5dc 0x5dc 0x5dc 0x5dc 0x5dc 0x5dc 0x5dc 0x5dc 0x5dc 0x5dc 0x5dc 0x5dc 0x5dc 0x5dc 0x5dc 0x5dc 0x5dc 0x5dc 0x5dc 0x5dc 0x5dc 0x5dc 0x5dc 0x5dc 0x5dc 0x5dc 0x5dc 0x5dc 0x5dc 0x5dc 0x5dc 0x5dc 0x5dc 0x5dc 0x5dc 0x5dc 0x5dc 0x5dc 0x5dc 0x5dc 0x5dc 0x5dc 0x5dc 0x5dc 0x5dc 0x5dc 0x5dc 0x5dc 0x5dc 0x5dc 0x5dc 0x5dc 0x5dc 0x5dc 0x5dc 0x5dc 0x5dc 0x5dc 0x5dc 0x5dc 0x5dc 0x5dc 0x5dc 0x5dc 0x5dc 0x5dc 0x5dc 0x5dc 0x5dc 0x5dc 0x5dc 0x5dc 0x5dc 0x5dc 0x5dc 0x5dc 0x5dc 0x5dc 0x5dc 0x5dc 0x5dc 0x5dc 0x5dc 0x5dc 0x5dc 0x5dc 0x5dc 0x5dc 0x5dc 0x5dc 0x5dc 0x5dc 0x5dc 0x5dc 0x5dc 0x5dc 0x5dc 0x5dc 0x5dc 0x5dc 0x5dc 0x5dc 0x5dc 0x5dc 0x5dc 0x5dc 0x7d0 0x5dc 0x5dc 0x5dc 0x5dc 0x5dc 0x5dc 0x5dc 0x5dc 0x5dc 0x5dc 0x5dc 0x5dc 0x5dc 0x5dc 0x5dc 0x5dc 0x7d0 0x5dc 0x5dc 0x5dc 0x5dc 0x5dc 0x5dc 0x5dc 0x5dc 0x5dc 0x5dc 0x5dc 0x5dc 0x5dc 0x5dc 0x5dc 0x5dc 0x5dc 0x5dc 0x5dc 0x5dc 0x5dc 0x5dc 0x5dc 0x5dc 0x5dc 0x5dc 0x5dc 0x5dc 0x5dc 0x5dc 0x5dc 0x5dc 0x5dc 0x5dc 0x5dc 0x5dc 0x5dc 0x5dc 0x5dc 0x5dc 0x5dc 0x5dc 0x5dc 0x5dc 0x5dc 0x5dc 0x5dc 0x5dc 0x5dc 0x5dc 0x5dc 0x5dc 0x5dc 0x5dc 0x5dc 0x5dc 0x5dc 0x5dc 0x5dc 0x5dc 0x5dc 0x5dc 0x5dc 0x5dc 0x5dc 0x5dc 0x5dc 0x5dc 0x5dc 0x5dc 0x5dc 0x5dc 0x5dc 0x5dc 0x5dc 0x5dc 0x5dc 0x5dc 0x5dc 0x5dc 0x5dc 0x5dc 0x5dc 0x5dc 0x5dc 0x5dc 0x5dc 0x5dc 0x5dc 0x5dc 0x5dc 0x5dc 0x5dc 0x5dc 0x5dc 0x5dc 0x5dc 0x5dc 0x5dc 0x5dc 0x5dc 0x5dc 0x5dc 0x5dc 0x5dc 0x5dc 0x5dc 0x5dc 0x5dc 0x5dc 0x5dc 0x5dc 0x5dc 0x5dc 0x5dc 0x5dc 0x5dc 0x5dc 0x5dc 0x5dc 0x5dc 0x5dc 0x5dc 0x5dc 0x5dc 0x5dc 0x5dc 0x5dc 0x5dc 0x5dc 0x5dc 0x5dc 0x5dc 0x5dc 0x5dc 0x5dc 0x5dc 0x5dc 0x5dc 0x5dc 0x5dc 0x5dc 0x5dc 0x5dc 0x5dc 0x5dc 0x5dc 0x5dc 0x5dc 0x5dc 0x5dc 0x5dc 0x5dc 0x5dc 0x5dc 0x5dc 0x5dc 0x5dc 0x5dc 0x5dc 0x5dc 0x5dc 0x5dc 0x5dc 0x5dc 0x5dc 0x5dc 0x5dc 0x5dc 0x5dc 0x5dc 0x5dc 0x5dc 0x5dc 0x5dc 0x5dc 0x5dc 0x5dc 0x5dc 0x5dc 0x5dc 0x5dc 0x5dc 0x5dc 0x5dc 0x5dc 0x5dc 0x5dc 0x5dc 0x5dc 0x5dc 0x5dc 0x5dc 0x5dc 0x5dc 0x5dc 0x5dc 0x5dc 0x5dc 0x5dc 0x5dc 0x5dc 0x5dc 0x5dc 0x5dc 0x5dc 0x5dc 0x5dc 0x5dc 0x5dc 0x5dc 0x5dc 0x5dc 0x5dc 0x5dc 0x5dc 0x5dc 0x5dc 0x5dc 0x5dc 0x5dc 0x5dc 0x5dc 0x5dc 0x5dc 0x5dc 0x5dc 0x5dc 0x5dc 0x5dc 0x5dc 0x5dc 0x5dc 0x5dc 0x5dc 0x5dc 0x5dc 0x5dc 0x5dc 0x5dc 0x5dc 0x5dc 0x5dc 0x5dc 0x5dc 0x5dc 0x5dc 0x5dc>;
				pt7_lo_limits_row_02 = <0x26>;
				pt7_lo_limits_cols_02 = <0x26>;
				pt7_lo_limits_02 = <0x1f4 0x1f4 0x1f4 0x1f4 0x1f4 0x1f4 0x1f4 0x1f4 0x1f4 0x1f4 0x1f4 0x1f4 0x1f4 0x1f4 0x1f4 0x1f4 0x1f4 0x1f4 0x1f4 0x1f4 0x1f4 0x1f4 0x1f4 0x1f4 0x1f4 0x1f4 0x1f4 0x1f4 0x1f4 0x1f4 0x1f4 0x1f4 0x1f4 0x1f4 0x1f4 0x1f4 0x1f4 0x1f4 0x1f4 0x1f4 0x1f4 0x1f4 0x1f4 0x1f4 0x1f4 0x1f4 0x1f4 0x1f4 0x1f4 0x1f4 0x1f4 0x1f4 0x1f4 0x1f4 0x1f4 0x1f4 0x1f4 0x1f4 0x1f4 0x1f4 0x1f4 0x1f4 0x1f4 0x1f4 0x1f4 0x1f4 0x1f4 0x1f4 0x1f4 0x1f4 0x1f4 0x1f4 0x1f4 0x1f4 0x1f4 0x1f4 0x1f4 0x1f4 0x1f4 0x1f4 0x1f4 0x1f4 0x1f4 0x1f4 0x1f4 0x1f4 0x1f4 0x1f4 0x1f4 0x1f4 0x1f4 0x1f4 0x1f4 0x1f4 0x1f4 0x1f4 0x1f4 0x1f4 0x1f4 0x1f4 0x1f4 0x1f4 0x1f4 0x1f4 0x1f4 0x1f4 0x1f4 0x1f4 0x1f4 0x1f4 0x1f4 0x1f4 0x1f4 0x1f4 0x1f4 0x1f4 0x1f4 0x1f4 0x1f4 0x1f4 0x1f4 0x1f4 0x1f4 0x1f4 0x1f4 0x1f4 0x1f4 0x1f4 0x1f4 0x1f4 0x1f4 0x1f4 0x1f4 0x1f4 0x1f4 0x1f4 0x1f4 0x1f4 0x1f4 0x1f4 0x1f4 0x1f4 0x1f4 0x1f4 0x1f4 0x1f4 0x1f4 0x1f4 0x1f4 0x1f4 0x1f4 0x1f4 0x1f4 0x1f4 0x1f4 0x1f4 0x1f4 0x1f4 0x1f4 0x1f4 0x1f4 0x1f4 0x1f4 0x1f4 0x1f4 0x1f4 0x1f4 0x1f4 0x1f4 0x1f4 0x1f4 0x1f4 0x1f4 0x1f4 0x1f4 0x1f4 0x1f4 0x1f4 0x1f4 0x1f4 0x1f4 0x1f4 0x1f4 0x1f4 0x1f4 0x1f4 0x1f4 0x1f4 0x1f4 0x1f4 0x1f4 0x1f4 0x1f4 0x1f4 0x1f4 0x1f4 0x1f4 0x1f4 0x1f4 0x1f4 0x1f4 0x1f4 0x1f4 0x1f4 0x1f4 0x1f4 0x1f4 0x1f4 0x1f4 0x1f4 0x1f4 0x1f4 0x1f4 0x1f4 0x1f4 0x1f4 0x1f4 0x1f4 0x1f4 0x1f4 0x1f4 0x1f4 0x1f4 0x1f4 0x1f4 0x1f4 0x1f4 0x1f4 0x1f4 0x1f4 0x1f4 0x1f4 0x1f4 0x1f4 0x1f4 0x1f4 0x1f4 0x1f4 0x1f4 0x1f4 0x1f4 0x1f4 0x1f4 0x1f4 0x1f4 0x1f4 0x1f4 0x1f4 0x1f4 0x1f4 0x1f4 0x1f4 0x1f4 0x1f4 0x1f4 0x1f4 0x1f4 0x1f4 0x1f4 0x1f4 0x1f4 0x1f4 0x1f4 0x1f4 0x1f4 0x1f4 0x1f4 0x1f4 0x1f4 0x1f4 0x1f4 0x1f4 0x1f4 0x1f4 0x1f4 0x1f4 0x1f4 0x1f4 0x1f4 0x1f4 0x1f4 0x1f4 0x1f4 0x1f4 0x1f4 0x1f4 0x1f4 0x1f4 0x1f4 0x1f4 0x1f4 0x1f4 0x1f4 0x1f4 0x1f4 0x1f4 0x1f4 0x1f4 0x1f4 0x1f4 0x1f4 0x1f4 0x1f4 0x1f4 0x1f4 0x1f4 0x1f4 0x1f4 0x1f4 0x1f4 0x1f4 0x1f4 0x1f4 0x1f4 0x1f4 0x1f4 0x1f4 0x1f4 0x1f4 0x1f4 0x1f4 0x1f4 0x1f4 0x1f4 0x1f4 0x1f4 0x1f4 0x1f4 0x1f4 0x1f4 0x1f4 0x1f4 0x1f4 0x1f4 0x1f4 0x1f4 0x1f4 0x1f4 0x1f4 0x1f4 0x1f4 0x1f4 0x1f4 0x1f4 0x1f4 0x1f4 0x1f4 0x1f4 0x1f4 0x1f4 0x1f4 0x1f4 0x1f4 0x1f4 0x1f4 0x1f4 0x1f4 0x1f4 0x1f4 0x1f4 0x1f4 0x1f4 0x1f4 0x1f4 0x1f4 0x1f4 0x1f4 0x1f4 0x1f4 0x1f4 0x1f4 0x1f4 0x1f4 0x1f4 0x1f4 0x1f4 0x1f4 0x1f4 0x1f4 0x1f4 0x1f4 0x1f4 0x1f4 0x1f4 0x1f4 0x1f4 0x1f4 0x1f4 0x1f4 0x1f4 0x1f4 0x1f4 0x1f4 0x1f4 0x1f4 0x1f4 0x1f4 0x1f4 0x1f4 0x1f4 0x1f4 0x1f4 0x1f4 0x1f4 0x1f4 0x1f4 0x1f4 0x1f4 0x1f4 0x1f4 0x1f4 0x1f4 0x1f4 0x1f4 0x1f4 0x1f4 0x1f4 0x1f4 0x1f4 0x1f4 0x1f4 0x1f4 0x1f4 0x1f4 0x1f4 0x1f4 0x1f4 0x1f4 0x1f4 0x1f4 0x1f4 0x1f4 0x1f4 0x1f4 0x1f4 0x1f4 0x1f4 0x1f4 0x1f4 0x1f4 0x1f4 0x1f4 0x1f4 0x1f4 0x1f4 0x1f4 0x1f4 0x1f4 0x1f4 0x1f4 0x1f4 0x1f4 0x1f4 0x1f4 0x1f4 0x1f4 0x1f4 0x1f4 0x1f4 0x1f4 0x1f4 0x1f4 0x1f4 0x1f4 0x1f4 0x1f4 0x1f4 0x1f4 0x1f4 0x1f4 0x1f4 0x1f4 0x1f4 0x1f4 0x1f4 0x1f4 0x1f4 0x1f4 0x1f4 0x1f4 0x1f4 0x1f4 0x1f4 0x1f4 0x1f4 0x1f4 0x1f4 0x1f4 0x1f4 0x1f4 0x1f4 0x1f4 0x1f4 0x1f4 0x1f4 0x1f4 0x1f4 0x1f4 0x1f4 0x1f4 0x1f4 0x1f4 0x1f4 0x1f4 0x1f4 0x1f4 0x1f4 0x1f4 0x1f4 0x1f4 0x1f4 0x1f4 0x1f4 0x1f4 0x1f4 0x1f4 0x1f4 0x1f4 0x1f4 0x1f4 0x1f4 0x1f4 0x1f4 0x1f4 0x1f4 0x1f4 0x1f4 0x1f4 0x1f4 0x1f4 0x1f4 0x1f4 0x1f4 0x1f4 0x1f4 0x1f4 0x1f4 0x1f4 0x1f4 0x1f4 0x1f4 0x1f4 0x1f4 0x1f4 0x1f4 0x1f4 0x1f4 0x1f4 0x1f4 0x1f4 0x1f4 0x1f4 0x1f4 0x1f4 0x1f4 0x1f4 0x1f4 0x1f4 0x1f4 0x1f4 0x1f4 0x1f4 0x1f4 0x1f4 0x1f4 0x1f4 0x1f4 0x1f4 0x1f4 0x1f4 0x1f4 0x1f4 0x1f4 0x1f4 0x1f4 0x1f4 0x1f4 0x1f4 0x1f4 0x1f4 0x1f4 0x1f4 0x1f4 0x1f4 0x1f4 0x1f4 0x1f4 0x1f4 0x1f4 0x1f4 0x1f4 0x1f4 0x1f4 0x1f4 0x1f4 0x1f4 0x1f4 0x1f4 0x1f4 0x1f4 0x1f4 0x1f4 0x1f4 0x1f4 0x1f4 0x1f4 0x1f4 0x1f4 0x1f4 0x1f4 0x1f4 0x1f4 0x1f4 0x1f4 0x1f4 0x1f4 0x1f4 0x1f4 0x1f4 0x1f4 0x1f4 0x1f4 0x1f4 0x1f4 0x1f4 0x1f4 0x1f4 0x1f4 0x1f4 0x1f4 0x1f4 0x1f4 0x1f4 0x1f4 0x1f4 0x1f4 0x1f4 0x1f4 0x1f4 0x1f4 0x1f4 0x1f4 0x1f4 0x1f4 0x1f4 0x1f4 0x1f4 0x1f4 0x1f4 0x1f4 0x1f4 0x1f4 0x1f4 0x1f4 0x1f4 0x1f4 0x1f4 0x1f4 0x1f4 0x1f4 0x1f4 0x1f4 0x1f4 0x1f4 0x1f4 0x1f4 0x1f4 0x1f4 0x1f4 0x1f4 0x1f4 0x1f4 0x1f4 0x1f4 0x1f4 0x1f4 0x1f4 0x1f4 0x1f4 0x1f4 0x1f4 0x1f4 0x1f4 0x1f4 0x1f4 0x1f4 0x1f4 0x1f4 0x1f4 0x1f4 0x1f4 0x1f4 0x1f4 0x1f4 0x1f4 0x1f4 0x1f4 0x1f4 0x1f4 0x1f4 0x1f4 0x1f4 0x1f4 0x1f4 0x1f4 0x1f4 0x1f4 0x1f4 0x1f4 0x1f4 0x1f4 0x1f4 0x1f4 0x1f4 0x1f4 0x1f4 0x1f4 0x1f4 0x1f4 0x1f4 0x1f4 0x1f4 0x1f4 0x1f4 0x1f4 0x1f4 0x1f4 0x1f4 0x1f4 0x1f4 0x1f4 0x1f4 0x1f4 0x1f4 0x1f4 0x1f4 0x1f4 0x1f4 0x1f4 0x1f4 0x1f4 0x1f4 0x1f4 0x1f4 0x1f4 0x1f4 0x1f4 0x1f4 0x1f4 0x1f4 0x1f4 0x1f4 0x1f4 0x1f4 0x1f4 0x1f4 0x1f4 0x1f4 0x1f4 0x1f4 0x1f4 0x1f4 0x1f4 0x1f4 0x1f4 0x1f4 0x1f4 0x1f4 0x1f4 0x1f4 0x1f4 0x1f4 0x1f4 0x1f4 0x1f4 0x1f4 0x1f4 0x1f4 0x1f4 0x1f4 0x1f4 0x1f4 0x1f4 0x1f4 0x1f4 0x1f4 0x1f4 0x1f4 0x1f4 0x1f4 0x1f4 0x1f4 0x1f4 0x1f4 0x1f4 0x1f4 0x1f4 0x1f4 0x1f4 0x1f4 0x1f4 0x1f4 0x1f4 0x1f4 0x1f4 0x1f4 0x1f4 0x1f4 0x1f4 0x1f4 0x1f4 0x1f4 0x1f4 0x1f4 0x1f4 0x1f4 0x1f4 0x1f4 0x1f4 0x1f4 0x1f4 0x1f4 0x1f4 0x1f4 0x1f4 0x1f4 0x1f4 0x1f4 0x1f4 0x1f4 0x1f4 0x1f4 0x1f4 0x1f4 0x1f4 0x1f4 0x1f4 0x1f4 0x1f4 0x1f4 0x1f4 0x1f4 0x1f4 0x1f4 0x1f4 0x1f4 0x1f4 0x1f4 0x1f4 0x1f4 0x1f4 0x1f4 0x1f4 0x1f4 0x1f4 0x1f4 0x1f4 0x1f4 0x1f4 0x1f4 0x1f4 0x1f4 0x1f4 0x1f4 0x1f4 0x1f4 0x1f4 0x1f4 0x1f4 0x1f4 0x1f4 0x1f4 0x1f4 0x1f4 0x1f4 0x1f4 0x1f4 0x1f4 0x1f4 0x1f4 0x1f4 0x1f4 0x1f4 0x1f4 0x1f4 0x1f4 0x1f4 0x1f4 0x1f4 0x1f4 0x1f4 0x1f4 0x1f4 0x1f4 0x1f4 0x1f4 0x1f4 0x1f4 0x1f4 0x1f4 0x1f4 0x1f4 0x1f4 0x1f4 0x1f4 0x1f4 0x1f4 0x1f4 0x1f4 0x1f4 0x1f4 0x1f4 0x1f4 0x1f4 0x1f4 0x1f4 0x1f4 0x1f4 0x1f4 0x1f4 0x1f4 0x1f4 0x1f4 0x1f4 0x1f4 0x1f4 0x1f4 0x1f4 0x1f4 0x1f4 0x1f4 0x1f4 0x1f4 0x1f4 0x1f4 0x1f4 0x1f4 0x1f4 0x1f4 0x1f4 0x1f4 0x1f4 0x1f4 0x1f4 0x1f4 0x1f4 0x1f4 0x1f4 0x1f4 0x1f4 0x1f4 0x1f4 0x1f4 0x1f4 0x1f4 0x1f4 0x1f4 0x1f4 0x1f4 0x1f4 0x1f4 0x1f4 0x1f4 0x1f4 0x1f4 0x1f4 0x1f4 0x1f4 0x1f4 0x1f4 0x1f4 0x1f4 0x1f4 0x1f4 0x1f4 0x1f4 0x1f4 0x1f4 0x1f4 0x1f4 0x1f4 0x1f4 0x1f4 0x1f4 0x1f4 0x1f4 0x1f4 0x1f4 0x1f4 0x1f4 0x1f4 0x1f4 0x1f4 0x1f4 0x1f4 0x1f4 0x1f4 0x1f4 0x1f4 0x1f4 0x1f4 0x1f4 0x1f4 0x1f4 0x1f4 0x1f4 0x1f4 0x1f4 0x1f4 0x1f4 0x1f4 0x1f4 0x1f4 0x1f4 0x1f4 0x1f4 0x1f4 0x1f4 0x1f4 0x1f4 0x1f4 0x1f4 0x1f4 0x1f4 0x1f4 0x1f4 0x1f4 0x1f4 0x1f4 0x1f4 0x1f4 0x1f4 0x1f4 0x1f4 0x1f4 0x1f4 0x1f4 0x1f4 0x1f4 0x1f4 0x1f4 0x1f4 0x1f4 0x1f4 0x1f4 0x1f4 0x1f4 0x1f4 0x1f4 0x1f4 0x1f4 0x1f4 0x1f4 0x1f4 0x1f4 0x1f4 0x1f4 0x1f4 0x1f4 0x1f4 0x1f4 0x1f4 0x1f4 0x1f4 0x1f4 0x1f4 0x1f4 0x1f4 0x1f4 0x1f4 0x1f4 0x1f4 0x1f4 0x1f4 0x1f4 0x1f4 0x1f4 0x1f4 0x1f4 0x1f4 0x1f4 0x1f4 0x1f4 0x1f4 0x1f4 0x1f4 0x1f4 0x1f4 0x1f4 0x1f4 0x1f4 0x1f4 0x1f4 0x1f4 0x1f4 0x1f4 0x1f4 0x1f4 0x1f4 0x1f4 0x1f4 0x1f4 0x1f4 0x1f4 0x1f4 0x1f4 0x1f4 0x1f4 0x1f4 0x1f4 0x1f4 0x1f4 0x1f4 0x1f4 0x1f4 0x1f4 0x1f4 0x1f4 0x1f4 0x1f4 0x1f4 0x1f4 0x1f4 0x1f4 0x1f4 0x1f4 0x1f4 0x1f4 0x1f4 0x1f4 0x1f4 0x1f4 0x1f4 0x1f4 0x1f4 0x1f4 0x1f4 0x1f4 0x1f4 0x1f4 0x1f4 0x1f4 0x1f4 0x1f4 0x1f4 0x1f4 0x1f4 0x1f4 0x1f4 0x1f4 0x1f4 0x1f4 0x1f4 0x1f4 0x1f4 0x1f4 0x1f4 0x1f4 0x1f4 0x1f4 0x1f4 0x1f4 0x1f4 0x1f4 0x1f4 0x1f4 0x1f4 0x1f4 0x1f4 0x1f4 0x1f4 0x1f4 0x1f4 0x1f4 0x1f4 0x1f4 0x1f4 0x1f4 0x1f4 0x1f4 0x1f4 0x1f4 0x1f4 0x1f4 0x1f4 0x1f4 0x1f4 0x1f4 0x1f4 0x1f4 0x1f4 0x1f4 0x1f4 0x1f4 0x1f4 0x1f4 0x1f4 0x1f4 0x1f4 0x1f4 0x1f4 0x1f4 0x1f4 0x1f4 0x1f4 0x1f4 0x1f4 0x1f4 0x1f4 0x1f4 0x1f4 0x1f4 0x1f4 0x1f4 0x1f4 0x1f4 0x1f4 0x1f4 0x1f4 0x1f4 0x1f4 0x1f4 0x1f4 0x1f4 0x1f4 0x1f4 0x1f4 0x1f4 0x1f4 0x1f4 0x1f4 0x1f4 0x1f4 0x1f4 0x1f4 0x1f4 0x1f4 0x1f4 0x1f4 0x1f4 0x1f4 0x1f4 0x1f4 0x1f4 0x1f4 0x1f4 0x1f4 0x1f4 0x1f4 0x1f4 0x1f4 0x1f4 0x1f4 0x1f4 0x1f4 0x1f4 0x1f4 0x1f4 0x1f4 0x1f4 0x1f4 0x1f4 0x1f4 0x1f4 0x1f4 0x1f4 0x1f4 0x1f4 0x1f4 0x1f4 0x1f4 0x1f4 0x1f4 0x1f4 0x1f4 0x1f4 0x1f4 0x1f4 0x1f4 0x1f4 0x1f4 0x1f4 0x1f4 0x1f4 0x1f4 0x1f4 0x1f4 0x1f4 0x1f4 0x1f4 0x1f4 0x1f4 0x1f4 0x1f4 0x1f4 0x1f4 0x1f4 0x1f4 0x1f4 0x1f4 0x1f4 0x1f4 0x1f4 0x1f4 0x1f4 0x1f4 0x1f4 0x1f4 0x1f4 0x1f4 0x1f4 0x1f4 0x1f4 0x1f4 0x1f4 0x1f4 0x1f4 0x1f4 0x1f4 0x1f4 0x1f4 0x1f4 0x1f4 0x1f4 0x1f4 0x1f4 0x1f4 0x1f4 0x1f4 0x1f4 0x1f4 0x1f4 0x1f4 0x1f4 0x1f4 0x1f4 0x1f4 0x1f4 0x1f4 0x1f4 0x1f4 0x1f4 0x1f4 0x1f4 0x1f4 0x1f4 0x1f4 0x1f4 0x1f4 0x1f4 0x1f4 0x1f4 0x1f4 0x1f4 0x1f4 0x1f4 0x1f4 0x1f4 0x1f4 0x1f4 0x1f4 0x1f4 0x1f4 0x1f4 0x1f4 0x1f4 0x1f4 0x1f4 0x1f4 0x1f4 0x1f4 0x1f4 0x1f4 0x1f4 0x1f4 0x1f4 0x1f4 0x1f4 0x1f4 0x1f4 0x1f4 0x1f4 0x1f4 0x1f4 0x1f4 0x1f4 0x1f4 0x1f4 0x1f4 0x1f4 0x1f4 0x1f4 0x1f4 0x1f4 0x1f4 0x1f4 0x1f4 0x1f4 0x1f4 0x1f4 0x1f4 0x1f4 0x1f4 0x1f4 0x1f4 0x1f4 0x1f4 0x1f4 0x1f4 0x1f4 0x1f4 0x1f4 0x1f4 0x1f4 0x1f4 0x1f4 0x1f4 0x1f4 0x1f4 0x1f4 0x1f4 0x1f4 0x1f4 0x1f4 0x1f4 0x1f4 0x1f4 0x1f4 0x1f4 0x1f4 0x1f4 0x1f4 0x1f4 0x1f4 0x1f4 0x1f4 0x1f4 0x1f4 0x1f4 0x1f4 0x1f4 0x1f4 0x1f4 0x1f4>;
				pt11_hi_limits_row_02 = <0x26>;
				pt11_hi_limits_cols_02 = <0x26>;
				pt11_hi_limits_02 = <0x50 0x50 0x50 0x50 0x50 0x50 0x50 0x50 0x50 0x50 0x50 0x50 0x50 0x50 0x50 0x50 0x50 0x50 0x50 0x50 0x50 0x50 0x50 0x50 0x50 0x50 0x50 0x50 0x50 0x50 0x50 0x50 0x50 0x50 0x50 0x50 0x50 0x50 0x50 0x50 0x50 0x50 0x50 0x50 0x50 0x50 0x50 0x50 0x50 0x50 0x50 0x50 0x50 0x50 0x50 0x50 0x50 0x50 0x50 0x50 0x50 0x50 0x50 0x50 0x50 0x50 0x50 0x50 0x50 0x50 0x50 0x50 0x50 0x50 0x50 0x50 0x50 0x50 0x50 0x50 0x50 0x50 0x50 0x50 0x50 0x50 0x50 0x50 0x50 0x50 0x50 0x50 0x50 0x50 0x50 0x50 0x50 0x50 0x50 0x50 0x50 0x50 0x50 0x50 0x50 0x50 0x50 0x50 0x50 0x50 0x50 0x50 0x50 0x50 0x50 0x50 0x50 0x50 0x50 0x50 0x50 0x50 0x50 0x50 0x50 0x50 0x50 0x50 0x50 0x50 0x50 0x50 0x50 0x50 0x50 0x50 0x50 0x50 0x50 0x50 0x50 0x50 0x50 0x50 0x50 0x50 0x50 0x50 0x50 0x50 0x50 0x50 0x50 0x50 0x50 0x50 0x50 0x50 0x50 0x50 0x50 0x50 0x50 0x50 0x50 0x50 0x50 0x50 0x50 0x50 0x50 0x50 0x50 0x50 0x50 0x50 0x50 0x50 0x50 0x50 0x50 0x50 0x50 0x50 0x50 0x50 0x50 0x50 0x50 0x50 0x50 0x50 0x50 0x50 0x50 0x50 0x50 0x50 0x50 0x50 0x50 0x50 0x50 0x50 0x50 0x50 0x50 0x50 0x50 0x50 0x50 0x50 0x50 0x50 0x50 0x50 0x50 0x50 0x50 0x50 0x50 0x50 0x50 0x50 0x50 0x50 0x50 0x50 0x50 0x50 0x50 0x50 0x50 0x50 0x50 0x50 0x50 0x50 0x50 0x50 0x50 0x50 0x50 0x50 0x50 0x50 0x50 0x50 0x50 0x50 0x50 0x50 0x50 0x50 0x50 0x50 0x50 0x50 0x50 0x50 0x50 0x50 0x50 0x50 0x50 0x50 0x50 0x50 0x50 0x50 0x50 0x50 0x50 0x50 0x50 0x50 0x50 0x50 0x50 0x50 0x50 0x50 0x50 0x50 0x50 0x50 0x50 0x50 0x50 0x50 0x50 0x50 0x50 0x50 0x50 0x50 0x50 0x50 0x50 0x50 0x50 0x50 0x50 0x50 0x50 0x50 0x50 0x50 0x50 0x50 0x50 0x50 0x50 0x50 0x50 0x50 0x50 0x50 0x50 0x50 0x50 0x50 0x50 0x50 0x50 0x50 0x50 0x50 0x50 0x50 0x50 0x50 0x50 0x50 0x50 0x50 0x50 0x50 0x50 0x50 0x50 0x50 0x50 0x50 0x50 0x50 0x50 0x50 0x50 0x50 0x50 0x50 0x50 0x50 0x50 0x50 0x50 0x50 0x50 0x50 0x50 0x50 0x50 0x50 0x50 0x50 0x50 0x50 0x50 0x50 0x50 0x50 0x50 0x50 0x50 0x50 0x50 0x50 0x50 0x50 0x50 0x50 0x50 0x50 0x50 0x50 0x50 0x50 0x50 0x50 0x50 0x50 0x50 0x50 0x50 0x50 0x50 0x50 0x50 0x50 0x50 0x50 0x50 0x50 0x50 0x50 0x50 0x50 0x50 0x50 0x50 0x50 0x50 0x50 0x50 0x50 0x50 0x50 0x50 0x50 0x50 0x50 0x50 0x50 0x50 0x50 0x50 0x50 0x50 0x50 0x50 0x50 0x50 0x50 0x50 0x50 0x50 0x50 0x50 0x50 0x50 0x50 0x50 0x50 0x50 0x50 0x50 0x50 0x50 0x50 0x50 0x50 0x50 0x50 0x50 0x50 0x50 0x50 0x50 0x50 0x50 0x50 0x50 0x50 0x50 0x50 0x50 0x50 0x50 0x50 0x50 0x50 0x50 0x50 0x50 0x50 0x50 0x50 0x50 0x50 0x50 0x50 0x50 0x50 0x50 0x50 0x50 0x50 0x50 0x50 0x50 0x50 0x50 0x50 0x50 0x50 0x50 0x50 0x50 0x50 0x50 0x50 0x50 0x50 0x50 0x50 0x50 0x50 0x50 0x50 0x50 0x50 0x50 0x50 0x50 0x50 0x50 0x50 0x50 0x50 0x50 0x50 0x50 0x50 0x50 0x50 0x50 0x50 0x50 0x50 0x50 0x50 0x50 0x50 0x50 0x50 0x50 0x50 0x50 0x50 0x50 0x50 0x50 0x50 0x50 0x50 0x50 0x50 0x50 0x50 0x50 0x50 0x50 0x50 0x50 0x50 0x50 0x50 0x50 0x50 0x50 0x50 0x50 0x50 0x50 0x50 0x50 0x50 0x50 0x50 0x50 0x50 0x50 0x50 0x50 0x50 0x50 0x50 0x50 0x50 0x50 0x50 0x50 0x50 0x50 0x50 0x50 0x50 0x50 0x50 0x50 0x50 0x50 0x50 0x50 0x50 0x50 0x50 0x50 0x50 0x50 0x50 0x50 0x50 0x50 0x50 0x50 0x50 0x50 0x50 0x50 0x50 0x50 0x50 0x50 0x50 0x50 0x50 0x50 0x50 0x50 0x50 0x50 0x50 0x50 0x50 0x50 0x50 0x50 0x50 0x50 0x50 0x50 0x50 0x50 0x50 0x50 0x50 0x50 0x50 0x50 0x50 0x50 0x50 0x50 0x50 0x50 0x50 0x50 0x50 0x50 0x50 0x50 0x50 0x50 0x50 0x50 0x50 0x50 0x50 0x50 0x50 0x50 0x50 0x50 0x50 0x50 0x50 0x50 0x50 0x50 0x50 0x50 0x50 0x50 0x50 0x50 0x50 0x50 0x50 0x50 0x50 0x50 0x50 0x50 0x50 0x50 0x50 0x50 0x50 0x50 0x50 0x50 0x50 0x50 0x50 0x50 0x50 0x50 0x50 0x50 0x50 0x50 0x50 0x50 0x50 0x50 0x50 0x50 0x50 0x50 0x50 0x50 0x50 0x50 0x50 0x50 0x50 0x50 0x50 0x50 0x50 0x50 0x50 0x50 0x50 0x50 0x50 0x50 0x50 0x50 0x50 0x50 0x50 0x50 0x50 0x50 0x50 0x50 0x50 0x50 0x50 0x50 0x50 0x50 0x50 0x50 0x50 0x50 0x50 0x50 0x50 0x50 0x50 0x50 0x50 0x50 0x50 0x50 0x50 0x50 0x50 0x50 0x50 0x50 0x50 0x50 0x50 0x50 0x50 0x50 0x50 0x50 0x50 0x50 0x50 0x50 0x50 0x50 0x50 0x50 0x50 0x50 0x50 0x50 0x50 0x50 0x50 0x50 0x50 0x50 0x50 0x50 0x50 0x50 0x50 0x50 0x50 0x50 0x50 0x50 0x50 0x50 0x50 0x50 0x50 0x50 0x50 0x50 0x50 0x50 0x50 0x50 0x50 0x50 0x50 0x50 0x50 0x50 0x50 0x50 0x50 0x50 0x50 0x50 0x50 0x50 0x50 0x50 0x50 0x50 0x50 0x50 0x50 0x50 0x50 0x50 0x50 0x50 0x50 0x50 0x50 0x50 0x50 0x50 0x50 0x50 0x50 0x50 0x50 0x50 0x50 0x50 0x50 0x50 0x50 0x50 0x50 0x50 0x50 0x50 0x50 0x50 0x50 0x50 0x50 0x50 0x50 0x50 0x50 0x50 0x50 0x50 0x50 0x50 0x50 0x50 0x50 0x50 0x50 0x50 0x50 0x50 0x50 0x50 0x50 0x50 0x50 0x50 0x50 0x50 0x50 0x50 0x50 0x50 0x50 0x50 0x50 0x50 0x50 0x50 0x50 0x50 0x50 0x50 0x50 0x50 0x50 0x50 0x50 0x50 0x50 0x50 0x50 0x50 0x50 0x50 0x50 0x50 0x50 0x50 0x50 0x50 0x50 0x50 0x50 0x50 0x50 0x50 0x50 0x50 0x50 0x50 0x50 0x50 0x50 0x50 0x50 0x50 0x50 0x50 0x50 0x50 0x50 0x50 0x50 0x50 0x50 0x50 0x50 0x50 0x50 0x50 0x50 0x50 0x50 0x50 0x50 0x50 0x50 0x50 0x50 0x50 0x50 0x50 0x50 0x50 0x50 0x50 0x50 0x50 0x50 0x50 0x50 0x50 0x50 0x50 0x50 0x50 0x50 0x50 0x50 0x50 0x50 0x50 0x50 0x50 0x50 0x50 0x50 0x50 0x50 0x50 0x50 0x50 0x50 0x50 0x50 0x50 0x50 0x50 0x50 0x50 0x50 0x50 0x50 0x50 0x50 0x50 0x50 0x50 0x50 0x50 0x50 0x50 0x50 0x50 0x50 0x50 0x50 0x50 0x50 0x50 0x50 0x50 0x50 0x50 0x50 0x50 0x50 0x50 0x50 0x50 0x50 0x50 0x50 0x50 0x50 0x50 0x50 0x50 0x50 0x50 0x50 0x50 0x50 0x50 0x50 0x50 0x50 0x50 0x50 0x50 0x50 0x50 0x50 0x50 0x50 0x50 0x50 0x50 0x50 0x50 0x50 0x50 0x50 0x50 0x50 0x50 0x50 0x50 0x50 0x50 0x50 0x50 0x50 0x50 0x50 0x50 0x50 0x50 0x50 0x50 0x50 0x50 0x50 0x50 0x50 0x50 0x50 0x50 0x50 0x50 0x50 0x50 0x50 0x50 0x50 0x50 0x50 0x50 0x50 0x50 0x50 0x50 0x50 0x50 0x50 0x50 0x50 0x50 0x50 0x50 0x50 0x50 0x50 0x50 0x50 0x50 0x50 0x50 0x50 0x50 0x50 0x50 0x50 0x50 0x50 0x50 0x50 0x50 0x50 0x50 0x50 0x50 0x50 0x50 0x50 0x50 0x50 0x50 0x50 0x50 0x50 0x50 0x50 0x50 0x50 0x50 0x50 0x50 0x50 0x50 0x50 0x50 0x50 0x50 0x50 0x50 0x50 0x50 0x50 0x50 0x50 0x50 0x50 0x50 0x50 0x50 0x50 0x50 0x50 0x50 0x50 0x50 0x50 0x50 0x50 0x50 0x50 0x50 0x50 0x50 0x50 0x50 0x50 0x50 0x50 0x50 0x50 0x50 0x50 0x50 0x50 0x50 0x50 0x50 0x50 0x50 0x50 0x50 0x50 0x50 0x50 0x50 0x50 0x50 0x50 0x50 0x50 0x50 0x50 0x50 0x50 0x50 0x50 0x50 0x50 0x50 0x50 0x50 0x50 0x50 0x50 0x50 0x50 0x50 0x50 0x50 0x50 0x50 0x50 0x50 0x50 0x50 0x50 0x50 0x50 0x50 0x50 0x50 0x50 0x50 0x50 0x50 0x50 0x50 0x50 0x50 0x50 0x50 0x50 0x50 0x50 0x50 0x50 0x50 0x50 0x50 0x50 0x50 0x50 0x50 0x50 0x50 0x50 0x50 0x50 0x50 0x50 0x50 0x50 0x50 0x50 0x50 0x50 0x50 0x50 0x50 0x50 0x50 0x50 0x50 0x50 0x50 0x50 0x50 0x50 0x50 0x50 0x50 0x50 0x50 0x50 0x50 0x50 0x50 0x50 0x50 0x50 0x50 0x50 0x50 0x50 0x50 0x50 0x50 0x50 0x50 0x50 0x50 0x50 0x50 0x50 0x50 0x50 0x50 0x50 0x50 0x50 0x50 0x50 0x50 0x50 0x50 0x50 0x50 0x50 0x50 0x50 0x50 0x50 0x50 0x50 0x50 0x50 0x50 0x50 0x50 0x50 0x50 0x50 0x50 0x50 0x50 0x50 0x50 0x50 0x50 0x50 0x50 0x50 0x50 0x50 0x50 0x50 0x50 0x50 0x50 0x50 0x50 0x50 0x50 0x50 0x50 0x50 0x50 0x50 0x50 0x50 0x50 0x50 0x50 0x50 0x50 0x50 0x50 0x50 0x50 0x50 0x50 0x50 0x50 0x50 0x50 0x50 0x50 0x50 0x50 0x50 0x50 0x50 0x50 0x50 0x50 0x50 0x50 0x50 0x50 0x50 0x50 0x50 0x50 0x50 0x50 0x50 0x50 0x50 0x50 0x50 0x50 0x50 0x50 0x50 0x50 0x50 0x50 0x50 0x50 0x50 0x50 0x50 0x50 0x50 0x50 0x50 0x50 0x50 0x50 0x50 0x50 0x50 0x50 0x50 0x50 0x50 0x50 0x50 0x50 0x50 0x50 0x50 0x50 0x50>;
				pt11_lo_limits_row_02 = <0x26>;
				pt11_lo_limits_cols_02 = <0x26>;
				pt11_lo_limits_02 = <0xffffffb0 0xffffffb0 0xffffffb0 0xffffffb0 0xffffffb0 0xffffffb0 0xffffffb0 0xffffffb0 0xffffffb0 0xffffffb0 0xffffffb0 0xffffffb0 0xffffffb0 0xffffffb0 0xffffffb0 0xffffffb0 0xffffffb0 0xffffffb0 0xffffffb0 0xffffffb0 0xffffffb0 0xffffffb0 0xffffffb0 0xffffffb0 0xffffffb0 0xffffffb0 0xffffffb0 0xffffffb0 0xffffffb0 0xffffffb0 0xffffffb0 0xffffffb0 0xffffffb0 0xffffffb0 0xffffffb0 0xffffffb0 0xffffffb0 0xffffffb0 0xffffffb0 0xffffffb0 0xffffffb0 0xffffffb0 0xffffffb0 0xffffffb0 0xffffffb0 0xffffffb0 0xffffffb0 0xffffffb0 0xffffffb0 0xffffffb0 0xffffffb0 0xffffffb0 0xffffffb0 0xffffffb0 0xffffffb0 0xffffffb0 0xffffffb0 0xffffffb0 0xffffffb0 0xffffffb0 0xffffffb0 0xffffffb0 0xffffffb0 0xffffffb0 0xffffffb0 0xffffffb0 0xffffffb0 0xffffffb0 0xffffffb0 0xffffffb0 0xffffffb0 0xffffffb0 0xffffffb0 0xffffffb0 0xffffffb0 0xffffffb0 0xffffffb0 0xffffffb0 0xffffffb0 0xffffffb0 0xffffffb0 0xffffffb0 0xffffffb0 0xffffffb0 0xffffffb0 0xffffffb0 0xffffffb0 0xffffffb0 0xffffffb0 0xffffffb0 0xffffffb0 0xffffffb0 0xffffffb0 0xffffffb0 0xffffffb0 0xffffffb0 0xffffffb0 0xffffffb0 0xffffffb0 0xffffffb0 0xffffffb0 0xffffffb0 0xffffffb0 0xffffffb0 0xffffffb0 0xffffffb0 0xffffffb0 0xffffffb0 0xffffffb0 0xffffffb0 0xffffffb0 0xffffffb0 0xffffffb0 0xffffffb0 0xffffffb0 0xffffffb0 0xffffffb0 0xffffffb0 0xffffffb0 0xffffffb0 0xffffffb0 0xffffffb0 0xffffffb0 0xffffffb0 0xffffffb0 0xffffffb0 0xffffffb0 0xffffffb0 0xffffffb0 0xffffffb0 0xffffffb0 0xffffffb0 0xffffffb0 0xffffffb0 0xffffffb0 0xffffffb0 0xffffffb0 0xffffffb0 0xffffffb0 0xffffffb0 0xffffffb0 0xffffffb0 0xffffffb0 0xffffffb0 0xffffffb0 0xffffffb0 0xffffffb0 0xffffffb0 0xffffffb0 0xffffffb0 0xffffffb0 0xffffffb0 0xffffffb0 0xffffffb0 0xffffffb0 0xffffffb0 0xffffffb0 0xffffffb0 0xffffffb0 0xffffffb0 0xffffffb0 0xffffffb0 0xffffffb0 0xffffffb0 0xffffffb0 0xffffffb0 0xffffffb0 0xffffffb0 0xffffffb0 0xffffffb0 0xffffffb0 0xffffffb0 0xffffffb0 0xffffffb0 0xffffffb0 0xffffffb0 0xffffffb0 0xffffffb0 0xffffffb0 0xffffffb0 0xffffffb0 0xffffffb0 0xffffffb0 0xffffffb0 0xffffffb0 0xffffffb0 0xffffffb0 0xffffffb0 0xffffffb0 0xffffffb0 0xffffffb0 0xffffffb0 0xffffffb0 0xffffffb0 0xffffffb0 0xffffffb0 0xffffffb0 0xffffffb0 0xffffffb0 0xffffffb0 0xffffffb0 0xffffffb0 0xffffffb0 0xffffffb0 0xffffffb0 0xffffffb0 0xffffffb0 0xffffffb0 0xffffffb0 0xffffffb0 0xffffffb0 0xffffffb0 0xffffffb0 0xffffffb0 0xffffffb0 0xffffffb0 0xffffffb0 0xffffffb0 0xffffffb0 0xffffffb0 0xffffffb0 0xffffffb0 0xffffffb0 0xffffffb0 0xffffffb0 0xffffffb0 0xffffffb0 0xffffffb0 0xffffffb0 0xffffffb0 0xffffffb0 0xffffffb0 0xffffffb0 0xffffffb0 0xffffffb0 0xffffffb0 0xffffffb0 0xffffffb0 0xffffffb0 0xffffffb0 0xffffffb0 0xffffffb0 0xffffffb0 0xffffffb0 0xffffffb0 0xffffffb0 0xffffffb0 0xffffffb0 0xffffffb0 0xffffffb0 0xffffffb0 0xffffffb0 0xffffffb0 0xffffffb0 0xffffffb0 0xffffffb0 0xffffffb0 0xffffffb0 0xffffffb0 0xffffffb0 0xffffffb0 0xffffffb0 0xffffffb0 0xffffffb0 0xffffffb0 0xffffffb0 0xffffffb0 0xffffffb0 0xffffffb0 0xffffffb0 0xffffffb0 0xffffffb0 0xffffffb0 0xffffffb0 0xffffffb0 0xffffffb0 0xffffffb0 0xffffffb0 0xffffffb0 0xffffffb0 0xffffffb0 0xffffffb0 0xffffffb0 0xffffffb0 0xffffffb0 0xffffffb0 0xffffffb0 0xffffffb0 0xffffffb0 0xffffffb0 0xffffffb0 0xffffffb0 0xffffffb0 0xffffffb0 0xffffffb0 0xffffffb0 0xffffffb0 0xffffffb0 0xffffffb0 0xffffffb0 0xffffffb0 0xffffffb0 0xffffffb0 0xffffffb0 0xffffffb0 0xffffffb0 0xffffffb0 0xffffffb0 0xffffffb0 0xffffffb0 0xffffffb0 0xffffffb0 0xffffffb0 0xffffffb0 0xffffffb0 0xffffffb0 0xffffffb0 0xffffffb0 0xffffffb0 0xffffffb0 0xffffffb0 0xffffffb0 0xffffffb0 0xffffffb0 0xffffffb0 0xffffffb0 0xffffffb0 0xffffffb0 0xffffffb0 0xffffffb0 0xffffffb0 0xffffffb0 0xffffffb0 0xffffffb0 0xffffffb0 0xffffffb0 0xffffffb0 0xffffffb0 0xffffffb0 0xffffffb0 0xffffffb0 0xffffffb0 0xffffffb0 0xffffffb0 0xffffffb0 0xffffffb0 0xffffffb0 0xffffffb0 0xffffffb0 0xffffffb0 0xffffffb0 0xffffffb0 0xffffffb0 0xffffffb0 0xffffffb0 0xffffffb0 0xffffffb0 0xffffffb0 0xffffffb0 0xffffffb0 0xffffffb0 0xffffffb0 0xffffffb0 0xffffffb0 0xffffffb0 0xffffffb0 0xffffffb0 0xffffffb0 0xffffffb0 0xffffffb0 0xffffffb0 0xffffffb0 0xffffffb0 0xffffffb0 0xffffffb0 0xffffffb0 0xffffffb0 0xffffffb0 0xffffffb0 0xffffffb0 0xffffffb0 0xffffffb0 0xffffffb0 0xffffffb0 0xffffffb0 0xffffffb0 0xffffffb0 0xffffffb0 0xffffffb0 0xffffffb0 0xffffffb0 0xffffffb0 0xffffffb0 0xffffffb0 0xffffffb0 0xffffffb0 0xffffffb0 0xffffffb0 0xffffffb0 0xffffffb0 0xffffffb0 0xffffffb0 0xffffffb0 0xffffffb0 0xffffffb0 0xffffffb0 0xffffffb0 0xffffffb0 0xffffffb0 0xffffffb0 0xffffffb0 0xffffffb0 0xffffffb0 0xffffffb0 0xffffffb0 0xffffffb0 0xffffffb0 0xffffffb0 0xffffffb0 0xffffffb0 0xffffffb0 0xffffffb0 0xffffffb0 0xffffffb0 0xffffffb0 0xffffffb0 0xffffffb0 0xffffffb0 0xffffffb0 0xffffffb0 0xffffffb0 0xffffffb0 0xffffffb0 0xffffffb0 0xffffffb0 0xffffffb0 0xffffffb0 0xffffffb0 0xffffffb0 0xffffffb0 0xffffffb0 0xffffffb0 0xffffffb0 0xffffffb0 0xffffffb0 0xffffffb0 0xffffffb0 0xffffffb0 0xffffffb0 0xffffffb0 0xffffffb0 0xffffffb0 0xffffffb0 0xffffffb0 0xffffffb0 0xffffffb0 0xffffffb0 0xffffffb0 0xffffffb0 0xffffffb0 0xffffffb0 0xffffffb0 0xffffffb0 0xffffffb0 0xffffffb0 0xffffffb0 0xffffffb0 0xffffffb0 0xffffffb0 0xffffffb0 0xffffffb0 0xffffffb0 0xffffffb0 0xffffffb0 0xffffffb0 0xffffffb0 0xffffffb0 0xffffffb0 0xffffffb0 0xffffffb0 0xffffffb0 0xffffffb0 0xffffffb0 0xffffffb0 0xffffffb0 0xffffffb0 0xffffffb0 0xffffffb0 0xffffffb0 0xffffffb0 0xffffffb0 0xffffffb0 0xffffffb0 0xffffffb0 0xffffffb0 0xffffffb0 0xffffffb0 0xffffffb0 0xffffffb0 0xffffffb0 0xffffffb0 0xffffffb0 0xffffffb0 0xffffffb0 0xffffffb0 0xffffffb0 0xffffffb0 0xffffffb0 0xffffffb0 0xffffffb0 0xffffffb0 0xffffffb0 0xffffffb0 0xffffffb0 0xffffffb0 0xffffffb0 0xffffffb0 0xffffffb0 0xffffffb0 0xffffffb0 0xffffffb0 0xffffffb0 0xffffffb0 0xffffffb0 0xffffffb0 0xffffffb0 0xffffffb0 0xffffffb0 0xffffffb0 0xffffffb0 0xffffffb0 0xffffffb0 0xffffffb0 0xffffffb0 0xffffffb0 0xffffffb0 0xffffffb0 0xffffffb0 0xffffffb0 0xffffffb0 0xffffffb0 0xffffffb0 0xffffffb0 0xffffffb0 0xffffffb0 0xffffffb0 0xffffffb0 0xffffffb0 0xffffffb0 0xffffffb0 0xffffffb0 0xffffffb0 0xffffffb0 0xffffffb0 0xffffffb0 0xffffffb0 0xffffffb0 0xffffffb0 0xffffffb0 0xffffffb0 0xffffffb0 0xffffffb0 0xffffffb0 0xffffffb0 0xffffffb0 0xffffffb0 0xffffffb0 0xffffffb0 0xffffffb0 0xffffffb0 0xffffffb0 0xffffffb0 0xffffffb0 0xffffffb0 0xffffffb0 0xffffffb0 0xffffffb0 0xffffffb0 0xffffffb0 0xffffffb0 0xffffffb0 0xffffffb0 0xffffffb0 0xffffffb0 0xffffffb0 0xffffffb0 0xffffffb0 0xffffffb0 0xffffffb0 0xffffffb0 0xffffffb0 0xffffffb0 0xffffffb0 0xffffffb0 0xffffffb0 0xffffffb0 0xffffffb0 0xffffffb0 0xffffffb0 0xffffffb0 0xffffffb0 0xffffffb0 0xffffffb0 0xffffffb0 0xffffffb0 0xffffffb0 0xffffffb0 0xffffffb0 0xffffffb0 0xffffffb0 0xffffffb0 0xffffffb0 0xffffffb0 0xffffffb0 0xffffffb0 0xffffffb0 0xffffffb0 0xffffffb0 0xffffffb0 0xffffffb0 0xffffffb0 0xffffffb0 0xffffffb0 0xffffffb0 0xffffffb0 0xffffffb0 0xffffffb0 0xffffffb0 0xffffffb0 0xffffffb0 0xffffffb0 0xffffffb0 0xffffffb0 0xffffffb0 0xffffffb0 0xffffffb0 0xffffffb0 0xffffffb0 0xffffffb0 0xffffffb0 0xffffffb0 0xffffffb0 0xffffffb0 0xffffffb0 0xffffffb0 0xffffffb0 0xffffffb0 0xffffffb0 0xffffffb0 0xffffffb0 0xffffffb0 0xffffffb0 0xffffffb0 0xffffffb0 0xffffffb0 0xffffffb0 0xffffffb0 0xffffffb0 0xffffffb0 0xffffffb0 0xffffffb0 0xffffffb0 0xffffffb0 0xffffffb0 0xffffffb0 0xffffffb0 0xffffffb0 0xffffffb0 0xffffffb0 0xffffffb0 0xffffffb0 0xffffffb0 0xffffffb0 0xffffffb0 0xffffffb0 0xffffffb0 0xffffffb0 0xffffffb0 0xffffffb0 0xffffffb0 0xffffffb0 0xffffffb0 0xffffffb0 0xffffffb0 0xffffffb0 0xffffffb0 0xffffffb0 0xffffffb0 0xffffffb0 0xffffffb0 0xffffffb0 0xffffffb0 0xffffffb0 0xffffffb0 0xffffffb0 0xffffffb0 0xffffffb0 0xffffffb0 0xffffffb0 0xffffffb0 0xffffffb0 0xffffffb0 0xffffffb0 0xffffffb0 0xffffffb0 0xffffffb0 0xffffffb0 0xffffffb0 0xffffffb0 0xffffffb0 0xffffffb0 0xffffffb0 0xffffffb0 0xffffffb0 0xffffffb0 0xffffffb0 0xffffffb0 0xffffffb0 0xffffffb0 0xffffffb0 0xffffffb0 0xffffffb0 0xffffffb0 0xffffffb0 0xffffffb0 0xffffffb0 0xffffffb0 0xffffffb0 0xffffffb0 0xffffffb0 0xffffffb0 0xffffffb0 0xffffffb0 0xffffffb0 0xffffffb0 0xffffffb0 0xffffffb0 0xffffffb0 0xffffffb0 0xffffffb0 0xffffffb0 0xffffffb0 0xffffffb0 0xffffffb0 0xffffffb0 0xffffffb0 0xffffffb0 0xffffffb0 0xffffffb0 0xffffffb0 0xffffffb0 0xffffffb0 0xffffffb0 0xffffffb0 0xffffffb0 0xffffffb0 0xffffffb0 0xffffffb0 0xffffffb0 0xffffffb0 0xffffffb0 0xffffffb0 0xffffffb0 0xffffffb0 0xffffffb0 0xffffffb0 0xffffffb0 0xffffffb0 0xffffffb0 0xffffffb0 0xffffffb0 0xffffffb0 0xffffffb0 0xffffffb0 0xffffffb0 0xffffffb0 0xffffffb0 0xffffffb0 0xffffffb0 0xffffffb0 0xffffffb0 0xffffffb0 0xffffffb0 0xffffffb0 0xffffffb0 0xffffffb0 0xffffffb0 0xffffffb0 0xffffffb0 0xffffffb0 0xffffffb0 0xffffffb0 0xffffffb0 0xffffffb0 0xffffffb0 0xffffffb0 0xffffffb0 0xffffffb0 0xffffffb0 0xffffffb0 0xffffffb0 0xffffffb0 0xffffffb0 0xffffffb0 0xffffffb0 0xffffffb0 0xffffffb0 0xffffffb0 0xffffffb0 0xffffffb0 0xffffffb0 0xffffffb0 0xffffffb0 0xffffffb0 0xffffffb0 0xffffffb0 0xffffffb0 0xffffffb0 0xffffffb0 0xffffffb0 0xffffffb0 0xffffffb0 0xffffffb0 0xffffffb0 0xffffffb0 0xffffffb0 0xffffffb0 0xffffffb0 0xffffffb0 0xffffffb0 0xffffffb0 0xffffffb0 0xffffffb0 0xffffffb0 0xffffffb0 0xffffffb0 0xffffffb0 0xffffffb0 0xffffffb0 0xffffffb0 0xffffffb0 0xffffffb0 0xffffffb0 0xffffffb0 0xffffffb0 0xffffffb0 0xffffffb0 0xffffffb0 0xffffffb0 0xffffffb0 0xffffffb0 0xffffffb0 0xffffffb0 0xffffffb0 0xffffffb0 0xffffffb0 0xffffffb0 0xffffffb0 0xffffffb0 0xffffffb0 0xffffffb0 0xffffffb0 0xffffffb0 0xffffffb0 0xffffffb0 0xffffffb0 0xffffffb0 0xffffffb0 0xffffffb0 0xffffffb0 0xffffffb0 0xffffffb0 0xffffffb0 0xffffffb0 0xffffffb0 0xffffffb0 0xffffffb0 0xffffffb0 0xffffffb0 0xffffffb0 0xffffffb0 0xffffffb0 0xffffffb0 0xffffffb0 0xffffffb0 0xffffffb0 0xffffffb0 0xffffffb0 0xffffffb0 0xffffffb0 0xffffffb0 0xffffffb0 0xffffffb0 0xffffffb0 0xffffffb0 0xffffffb0 0xffffffb0 0xffffffb0 0xffffffb0 0xffffffb0 0xffffffb0 0xffffffb0 0xffffffb0 0xffffffb0 0xffffffb0 0xffffffb0 0xffffffb0 0xffffffb0 0xffffffb0 0xffffffb0 0xffffffb0 0xffffffb0 0xffffffb0 0xffffffb0 0xffffffb0 0xffffffb0 0xffffffb0 0xffffffb0 0xffffffb0 0xffffffb0 0xffffffb0 0xffffffb0 0xffffffb0 0xffffffb0 0xffffffb0 0xffffffb0 0xffffffb0 0xffffffb0 0xffffffb0 0xffffffb0 0xffffffb0 0xffffffb0 0xffffffb0 0xffffffb0 0xffffffb0 0xffffffb0 0xffffffb0 0xffffffb0 0xffffffb0 0xffffffb0 0xffffffb0 0xffffffb0 0xffffffb0 0xffffffb0 0xffffffb0 0xffffffb0 0xffffffb0 0xffffffb0 0xffffffb0 0xffffffb0 0xffffffb0 0xffffffb0 0xffffffb0 0xffffffb0 0xffffffb0 0xffffffb0 0xffffffb0 0xffffffb0 0xffffffb0 0xffffffb0 0xffffffb0 0xffffffb0 0xffffffb0 0xffffffb0 0xffffffb0 0xffffffb0 0xffffffb0 0xffffffb0 0xffffffb0 0xffffffb0 0xffffffb0 0xffffffb0 0xffffffb0 0xffffffb0 0xffffffb0 0xffffffb0 0xffffffb0 0xffffffb0 0xffffffb0 0xffffffb0 0xffffffb0 0xffffffb0 0xffffffb0 0xffffffb0 0xffffffb0 0xffffffb0 0xffffffb0 0xffffffb0 0xffffffb0 0xffffffb0 0xffffffb0 0xffffffb0 0xffffffb0 0xffffffb0 0xffffffb0 0xffffffb0 0xffffffb0 0xffffffb0 0xffffffb0 0xffffffb0 0xffffffb0 0xffffffb0 0xffffffb0 0xffffffb0 0xffffffb0 0xffffffb0 0xffffffb0 0xffffffb0 0xffffffb0 0xffffffb0 0xffffffb0 0xffffffb0 0xffffffb0 0xffffffb0 0xffffffb0 0xffffffb0 0xffffffb0 0xffffffb0 0xffffffb0 0xffffffb0 0xffffffb0 0xffffffb0 0xffffffb0 0xffffffb0 0xffffffb0 0xffffffb0 0xffffffb0 0xffffffb0 0xffffffb0 0xffffffb0 0xffffffb0 0xffffffb0 0xffffffb0 0xffffffb0 0xffffffb0 0xffffffb0 0xffffffb0 0xffffffb0 0xffffffb0 0xffffffb0 0xffffffb0 0xffffffb0 0xffffffb0 0xffffffb0 0xffffffb0 0xffffffb0 0xffffffb0 0xffffffb0 0xffffffb0 0xffffffb0 0xffffffb0 0xffffffb0 0xffffffb0 0xffffffb0 0xffffffb0 0xffffffb0 0xffffffb0 0xffffffb0 0xffffffb0 0xffffffb0 0xffffffb0 0xffffffb0 0xffffffb0 0xffffffb0 0xffffffb0 0xffffffb0 0xffffffb0 0xffffffb0 0xffffffb0 0xffffffb0 0xffffffb0 0xffffffb0 0xffffffb0 0xffffffb0 0xffffffb0 0xffffffb0 0xffffffb0 0xffffffb0 0xffffffb0 0xffffffb0 0xffffffb0 0xffffffb0 0xffffffb0 0xffffffb0 0xffffffb0 0xffffffb0 0xffffffb0 0xffffffb0 0xffffffb0 0xffffffb0 0xffffffb0 0xffffffb0 0xffffffb0 0xffffffb0 0xffffffb0 0xffffffb0 0xffffffb0 0xffffffb0 0xffffffb0 0xffffffb0 0xffffffb0 0xffffffb0 0xffffffb0 0xffffffb0 0xffffffb0 0xffffffb0 0xffffffb0 0xffffffb0 0xffffffb0 0xffffffb0 0xffffffb0 0xffffffb0 0xffffffb0 0xffffffb0 0xffffffb0 0xffffffb0 0xffffffb0 0xffffffb0 0xffffffb0 0xffffffb0 0xffffffb0 0xffffffb0 0xffffffb0 0xffffffb0 0xffffffb0 0xffffffb0 0xffffffb0 0xffffffb0 0xffffffb0 0xffffffb0 0xffffffb0 0xffffffb0 0xffffffb0 0xffffffb0 0xffffffb0 0xffffffb0 0xffffffb0 0xffffffb0 0xffffffb0 0xffffffb0 0xffffffb0 0xffffffb0 0xffffffb0 0xffffffb0 0xffffffb0 0xffffffb0 0xffffffb0 0xffffffb0 0xffffffb0 0xffffffb0 0xffffffb0 0xffffffb0 0xffffffb0 0xffffffb0 0xffffffb0 0xffffffb0 0xffffffb0 0xffffffb0 0xffffffb0 0xffffffb0 0xffffffb0 0xffffffb0 0xffffffb0 0xffffffb0 0xffffffb0 0xffffffb0 0xffffffb0 0xffffffb0 0xffffffb0 0xffffffb0 0xffffffb0 0xffffffb0 0xffffffb0 0xffffffb0 0xffffffb0 0xffffffb0 0xffffffb0 0xffffffb0 0xffffffb0 0xffffffb0 0xffffffb0 0xffffffb0 0xffffffb0 0xffffffb0 0xffffffb0 0xffffffb0 0xffffffb0 0xffffffb0 0xffffffb0 0xffffffb0 0xffffffb0 0xffffffb0 0xffffffb0 0xffffffb0 0xffffffb0 0xffffffb0 0xffffffb0 0xffffffb0 0xffffffb0 0xffffffb0 0xffffffb0 0xffffffb0 0xffffffb0 0xffffffb0 0xffffffb0 0xffffffb0 0xffffffb0 0xffffffb0 0xffffffb0 0xffffffb0 0xffffffb0 0xffffffb0 0xffffffb0 0xffffffb0 0xffffffb0 0xffffffb0 0xffffffb0 0xffffffb0 0xffffffb0 0xffffffb0 0xffffffb0 0xffffffb0 0xffffffb0 0xffffffb0 0xffffffb0 0xffffffb0 0xffffffb0 0xffffffb0 0xffffffb0 0xffffffb0 0xffffffb0 0xffffffb0 0xffffffb0 0xffffffb0 0xffffffb0 0xffffffb0 0xffffffb0 0xffffffb0 0xffffffb0 0xffffffb0 0xffffffb0 0xffffffb0 0xffffffb0 0xffffffb0 0xffffffb0 0xffffffb0 0xffffffb0 0xffffffb0 0xffffffb0 0xffffffb0 0xffffffb0 0xffffffb0 0xffffffb0 0xffffffb0 0xffffffb0 0xffffffb0 0xffffffb0 0xffffffb0 0xffffffb0 0xffffffb0 0xffffffb0 0xffffffb0 0xffffffb0 0xffffffb0 0xffffffb0 0xffffffb0 0xffffffb0 0xffffffb0 0xffffffb0 0xffffffb0 0xffffffb0 0xffffffb0 0xffffffb0 0xffffffb0 0xffffffb0 0xffffffb0 0xffffffb0 0xffffffb0 0xffffffb0 0xffffffb0 0xffffffb0 0xffffffb0 0xffffffb0 0xffffffb0 0xffffffb0 0xffffffb0 0xffffffb0 0xffffffb0 0xffffffb0 0xffffffb0 0xffffffb0 0xffffffb0 0xffffffb0 0xffffffb0 0xffffffb0 0xffffffb0 0xffffffb0 0xffffffb0 0xffffffb0 0xffffffb0 0xffffffb0 0xffffffb0 0xffffffb0 0xffffffb0 0xffffffb0 0xffffffb0 0xffffffb0 0xffffffb0 0xffffffb0 0xffffffb0 0xffffffb0 0xffffffb0 0xffffffb0 0xffffffb0 0xffffffb0 0xffffffb0 0xffffffb0 0xffffffb0 0xffffffb0 0xffffffb0 0xffffffb0 0xffffffb0 0xffffffb0 0xffffffb0 0xffffffb0 0xffffffb0 0xffffffb0 0xffffffb0 0xffffffb0 0xffffffb0 0xffffffb0 0xffffffb0 0xffffffb0 0xffffffb0 0xffffffb0 0xffffffb0 0xffffffb0 0xffffffb0 0xffffffb0 0xffffffb0 0xffffffb0 0xffffffb0 0xffffffb0 0xffffffb0 0xffffffb0 0xffffffb0 0xffffffb0 0xffffffb0 0xffffffb0 0xffffffb0 0xffffffb0 0xffffffb0 0xffffffb0 0xffffffb0 0xffffffb0 0xffffffb0 0xffffffb0 0xffffffb0 0xffffffb0 0xffffffb0 0xffffffb0 0xffffffb0 0xffffffb0 0xffffffb0 0xffffffb0 0xffffffb0 0xffffffb0 0xffffffb0 0xffffffb0 0xffffffb0 0xffffffb0 0xffffffb0 0xffffffb0 0xffffffb0 0xffffffb0 0xffffffb0 0xffffffb0 0xffffffb0 0xffffffb0 0xffffffb0 0xffffffb0 0xffffffb0 0xffffffb0 0xffffffb0 0xffffffb0 0xffffffb0 0xffffffb0 0xffffffb0 0xffffffb0 0xffffffb0 0xffffffb0 0xffffffb0 0xffffffb0 0xffffffb0 0xffffffb0 0xffffffb0 0xffffffb0 0xffffffb0 0xffffffb0 0xffffffb0 0xffffffb0 0xffffffb0 0xffffffb0 0xffffffb0 0xffffffb0 0xffffffb0 0xffffffb0 0xffffffb0 0xffffffb0 0xffffffb0 0xffffffb0 0xffffffb0 0xffffffb0 0xffffffb0 0xffffffb0 0xffffffb0 0xffffffb0 0xffffffb0 0xffffffb0 0xffffffb0 0xffffffb0 0xffffffb0 0xffffffb0 0xffffffb0 0xffffffb0 0xffffffb0 0xffffffb0 0xffffffb0 0xffffffb0 0xffffffb0 0xffffffb0 0xffffffb0 0xffffffb0 0xffffffb0 0xffffffb0 0xffffffb0 0xffffffb0 0xffffffb0 0xffffffb0 0xffffffb0 0xffffffb0 0xffffffb0 0xffffffb0 0xffffffb0>;
				phandle = <0x2d>;
			};
		};
	};

	__symbols__ {
		lcd_td4160_txd_mipi_hdp_x6525 = "/fragment/__overlay__/lcds/lcd_td4160_txd_mipi_hdp_x6525";
		td4160_txd_timing0 = "/fragment/__overlay__/lcds/lcd_td4160_txd_mipi_hdp_x6525/display-timings/timing0";
		td4160_txd_timing1 = "/fragment/__overlay__/lcds/lcd_td4160_txd_mipi_hdp_x6525/display-timings/timing1";
		lcd_td4160_hx_mipi_hdp_x6525 = "/fragment/__overlay__/lcds/lcd_td4160_hx_mipi_hdp_x6525";
		td4160_hx_timing0 = "/fragment/__overlay__/lcds/lcd_td4160_hx_mipi_hdp_x6525/display-timings/timing0";
		td4160_hx_timing1 = "/fragment/__overlay__/lcds/lcd_td4160_hx_mipi_hdp_x6525/display-timings/timing1";
		lcd_ft8057s_dpt_mipi_hdp_x6525 = "/fragment/__overlay__/lcds/lcd_ft8057s_dpt_mipi_hdp_x6525";
		ft8057s_dpt_timing0 = "/fragment/__overlay__/lcds/lcd_ft8057s_dpt_mipi_hdp_x6525/display-timings/timing0";
		ft8057s_dpt_timing1 = "/fragment/__overlay__/lcds/lcd_ft8057s_dpt_mipi_hdp_x6525/display-timings/timing1";
		lcd_dummy_mipi_hd = "/fragment/__overlay__/lcds/lcd_dummy_mipi_hd";
		dummy_timing0 = "/fragment/__overlay__/lcds/lcd_dummy_mipi_hd/display-timings/timing0";
		wcn_btwf = "/fragment/__overlay__/cpwcn-btwf";
		wcn_gnss = "/fragment/__overlay__/cpwcn-gnss";
		bat = "/fragment/__overlay__/battery";
		tran_charger = "/fragment/__overlay__/tran_charger";
		tboard_thermistor = "/fragment/__overlay__/thermal-sensor";
		pa_thermistor = "/fragment/__overlay__/pa-sensor";
		chg_thermistor = "/fragment/__overlay__/chg-sensor";
		sipc_wcn = "/fragment@0/__overlay__/core@3";
		wcn_fm = "/fragment@0/__overlay__/core@3/wcn_fm";
		sipc_gnss = "/fragment@0/__overlay__/core@4";
		sttygnss0 = "/fragment@0/__overlay__/core@4/channel@4";
		wcn_reserved = "/fragment@2/__overlay__/wcn-mem@87000000";
		logo_reserved = "/fragment@2/__overlay__/logobuffer@9e000000";
		fd_reserved = "/fragment@2/__overlay__/faceid-mem@ffa70000";
		pa_thmzone = "/fragment@3/__overlay__/pa-thmzone";
		chg_thmzone = "/fragment@3/__overlay__/chg-thmzone";
		bd_thmzone = "/fragment@3/__overlay__/board-thmzone";
		sensor_main = "/fragment@4/__overlay__/sensor-main@20";
		sensor_sub = "/fragment@5/__overlay__/sensor-sub@5a";
		sensor_main2 = "/fragment@5/__overlay__/sensor-main2@20";
		flash_ic = "/fragment@6/__overlay__/flash-ic@63";
		flash_ic_ocp81375 = "/fragment@6/__overlay__/flash_ic_ocp81375@64";
		aw32257 = "/fragment@12/__overlay__/aw32257@6a";
		vddvbus = "/fragment@12/__overlay__/aw32257@6a/otg-vbus";
		stm_vl53l0 = "/fragment@13/__overlay__/vl53l0@52";
		usb_con = "/fragment@23/__overlay__/connector";
		gpio_8 = "/fragment@25/__overlay__/rfctl16";
		gpio_22 = "/fragment@25/__overlay__/rfctl3";
		gpio_24 = "/fragment@25/__overlay__/rfctl5";
		gpio_25 = "/fragment@25/__overlay__/rfctl6";
		gpio_26 = "/fragment@25/__overlay__/rfctl7";
		gpio_124 = "/fragment@25/__overlay__/keyin0";
		gpio_175 = "/fragment@25/__overlay__/bt_rfctl2";
		tran_touch = "/fragment@28/__overlay__/transsion-touchscreen@0";
	};

	__fixups__ {
		aon_apb_regs = "/fragment/__overlay__/cpwcn-btwf:sprd,syscon-ap-apb:0\0/fragment/__overlay__/cpwcn-gnss:sprd,syscon-ap-apb:0";
		pmu_apb_regs = "/fragment/__overlay__/cpwcn-btwf:sprd,syscon-ap-pmu:0\0/fragment/__overlay__/cpwcn-gnss:sprd,syscon-ap-pmu:0";
		wcncp_aon_apb_regs = "/fragment/__overlay__/cpwcn-btwf:sprd,syscon-wcn-aon-apb:0\0/fragment/__overlay__/cpwcn-gnss:sprd,syscon-wcn-aon-apb:0";
		wcncp_aon_ahb_regs = "/fragment/__overlay__/cpwcn-btwf:sprd,syscon-wcn-aon-ahb:0\0/fragment/__overlay__/cpwcn-gnss:sprd,syscon-wcn-aon-ahb:0";
		pub_apb_regs = "/fragment/__overlay__/cpwcn-btwf:sprd,syscon-ap-pub-apb:0\0/fragment/__overlay__/cpwcn-gnss:sprd,syscon-ap-pub-apb:0";
		wcncp_btwf_ahb_regs = "/fragment/__overlay__/cpwcn-btwf:sprd,syscon-wcn-btwf-ahb:0";
		vddwcn = "/fragment/__overlay__/cpwcn-btwf:vddwcn-supply:0\0/fragment/__overlay__/cpwcn-gnss:vddwcn-supply:0";
		vddsim2 = "/fragment/__overlay__/cpwcn-btwf:dcxo1v8-supply:0\0/fragment/__overlay__/cpwcn-gnss:dcxo1v8-supply:0";
		vddwifipa = "/fragment/__overlay__/cpwcn-btwf:vddwifipa-supply:0";
		ap_gpio = "/fragment/__overlay__/cpwcn-btwf:merlion-chip-en-gpios:0\0/fragment/__overlay__/cpwcn-btwf:merlion-rst-gpios:0\0/fragment/__overlay__/cpwcn-btwf:xtal-26m-type-sel-gpios:0\0/fragment/__overlay__/cpwcn-gnss:merlion-chip-en-gpios:0\0/fragment/__overlay__/cpwcn-gnss:merlion-rst-gpios:0\0/fragment/__overlay__/cpwcn-gnss:xtal-26m-type-sel-gpios:0\0/fragment/__overlay__/fingerprint@0:transsion-rst:0\0/fragment/__overlay__/fingerprint@1:fp-gpio-reset:0\0/fragment/__overlay__/gpio-keys/key-volumedown:gpios:0\0/fragment/__overlay__/audio-voice-trig:irq_gpio:0\0/fragment@0/__overlay__/core@3/wcn_fm:sprd,hp_lna_gpio:0\0/fragment@4/__overlay__/sensor-main@20:reset-gpios:0\0/fragment@4/__overlay__/sensor-main@20:power-down-gpios:0\0/fragment@5/__overlay__/sensor-sub@5a:reset-gpios:0\0/fragment@5/__overlay__/sensor-sub@5a:power-down-gpios:0\0/fragment@5/__overlay__/sensor-main2@20:fakeserial-gpios:0\0/fragment@6/__overlay__/flash_ic_ocp81375@64:flash-torch-en-gpios:0\0/fragment@11/__overlay__/sec-nfc@27:sec-nfc,ven-gpio:0\0/fragment@11/__overlay__/sec-nfc@27:sec-nfc,firm-gpio:0\0/fragment@11/__overlay__/sec-nfc@27:sec-nfc,irq-gpio:0\0/fragment@11/__overlay__/sec-nfc@27:sec-nfc,clk-req:0\0/fragment@12/__overlay__/aw32257@6a:charge,chg-pd-gpio:0\0/fragment@13/__overlay__/vl53l0@52:interrupt-parent:0\0/fragment@17/__overlay__:sprd,spk-ext-pa-gpio:0\0/fragment@20/__overlay__:avdd-gpio:0\0/fragment@20/__overlay__:avee-gpio:0\0/fragment@20/__overlay__:reset-gpio:0\0/fragment@28/__overlay__/transsion-touchscreen@0:omnivision,reset-gpio:0\0/fragment@28/__overlay__/transsion-touchscreen@0:focaltech,reset-gpio:0";
		wcn_alpha = "/fragment/__overlay__/cpwcn-btwf:nvmem-cells:0\0/fragment/__overlay__/cpwcn-gnss:nvmem-cells:0";
		wcncp_gnss_ahb_regs = "/fragment/__overlay__/cpwcn-gnss:sprd,syscon-wcn-gnss-ahb:0";
		eic_async = "/fragment/__overlay__/fingerprint@0:transsion-irq:0\0/fragment/__overlay__/fingerprint@1:fp-gpio-irq:0\0/fragment@28/__overlay__/transsion-touchscreen@0:omnivision,irq-gpio:0\0/fragment@28/__overlay__/transsion-touchscreen@0:focaltech,irq-gpio:0";
		vddldo1 = "/fragment/__overlay__/fingerprint@0:avdd-supply:0";
		pmic_eic = "/fragment/__overlay__/gpio-keys/key-volumeup:gpios:0\0/fragment/__overlay__/gpio-keys/key-power:gpios:0";
		hsphy = "/fragment/__overlay__/charger-manager:phys:0\0/fragment/__overlay__/tran_charger:phys:0\0/fragment@8:target:0\0/fragment@12/__overlay__/aw32257@6a:phys:0\0/fragment@19/__overlay__:phys:0";
		pmic_typec = "/fragment/__overlay__/charger-manager:extcon:0\0/fragment@9/__overlay__:extcon:4";
		pmic_pd = "/fragment/__overlay__/charger-manager:extcon:4\0/fragment@23:target:0";
		pmic_adc = "/fragment/__overlay__/thermal-sensor:io-channels:0\0/fragment/__overlay__/pa-sensor:io-channels:0\0/fragment/__overlay__/chg-sensor:io-channels:0\0/fragment@19/__overlay__:io-channels:0\0/fragment@19/__overlay__:io-channels:8";
		uid_start = "/fragment/__overlay__/sprd_uid:nvmem-cells:0";
		uid_end = "/fragment/__overlay__/sprd_uid:nvmem-cells:4";
		sipc = "/fragment@0:target:0";
		mailbox = "/fragment@0/__overlay__/core@3:mboxes:0\0/fragment@0/__overlay__/core@4:mboxes:0";
		chosen = "/fragment@1:target:0";
		reserved_memory = "/fragment@2:target:0";
		thm_zone = "/fragment@3:target:0";
		i2c0 = "/fragment@4:target:0";
		mm_clk = "/fragment@4/__overlay__/sensor-main@20:clocks:0\0/fragment@5/__overlay__/sensor-sub@5a:clocks:0\0/fragment@5/__overlay__/sensor-main2@20:clocks:0";
		mm_gate = "/fragment@4/__overlay__/sensor-main@20:clocks:8\0/fragment@5/__overlay__/sensor-sub@5a:clocks:8\0/fragment@5/__overlay__/sensor-main2@20:clocks:8";
		pll1 = "/fragment@4/__overlay__/sensor-main@20:clocks:16\0/fragment@4/__overlay__/sensor-main@20:clocks:24\0/fragment@4/__overlay__/sensor-main@20:clocks:32\0/fragment@5/__overlay__/sensor-sub@5a:clocks:16\0/fragment@5/__overlay__/sensor-sub@5a:clocks:24\0/fragment@5/__overlay__/sensor-sub@5a:clocks:32\0/fragment@5/__overlay__/sensor-main2@20:clocks:16\0/fragment@5/__overlay__/sensor-main2@20:clocks:24\0/fragment@5/__overlay__/sensor-main2@20:clocks:32";
		ext_26m = "/fragment@4/__overlay__/sensor-main@20:clocks:40\0/fragment@5/__overlay__/sensor-sub@5a:clocks:40\0/fragment@5/__overlay__/sensor-main2@20:clocks:40\0/fragment@11/__overlay__/sec-nfc@27:clocks:8";
		vddcamio = "/fragment@4/__overlay__/sensor-main@20:vddio-supply:0\0/fragment@5/__overlay__/sensor-sub@5a:vddio-supply:0";
		vddcama0 = "/fragment@4/__overlay__/sensor-main@20:vddcama-supply:0";
		vddcamd0 = "/fragment@4/__overlay__/sensor-main@20:vddcamd-supply:0";
		vddcammot = "/fragment@4/__overlay__/sensor-main@20:vddcammot-supply:0";
		csi0 = "/fragment@4/__overlay__/sensor-main@20:csi:0";
		mm_domain = "/fragment@4/__overlay__/sensor-main@20:power-domains:0\0/fragment@5/__overlay__/sensor-sub@5a:power-domains:0\0/fragment@5/__overlay__/sensor-main2@20:power-domains:0";
		i2c1 = "/fragment@5:target:0";
		vddcama1 = "/fragment@5/__overlay__/sensor-sub@5a:vddcama-supply:0\0/fragment@5/__overlay__/sensor-main2@20:vddcama-supply:0";
		vddcamd1 = "/fragment@5/__overlay__/sensor-sub@5a:vddcamd-supply:0";
		csi1 = "/fragment@5/__overlay__/sensor-sub@5a:csi:0";
		csi2 = "/fragment@5/__overlay__/sensor-main2@20:csi:0";
		i2c5 = "/fragment@6:target:0";
		i2c6 = "/fragment@7:target:0";
		vddusb33 = "/fragment@8/__overlay__:vdd-supply:0";
		extcon_gpio = "/fragment@8/__overlay__:extcon:0\0/fragment@9/__overlay__:extcon:0\0/fragment@12/__overlay__/aw32257@6a:extcon:0";
		usb = "/fragment@9:target:0";
		sdio0 = "/fragment@10:target:0";
		eic_sync = "/fragment@10/__overlay__:cd-gpios:0";
		i2c2 = "/fragment@11:target:0";
		aon_clk = "/fragment@11/__overlay__/sec-nfc@27:clocks:0";
		aonapb_gate = "/fragment@11/__overlay__/sec-nfc@27:clocks:12";
		i2c3 = "/fragment@12:target:0";
		i2c4 = "/fragment@13:target:0";
		aon_i2c0 = "/fragment@14:target:0";
		sprd_headset = "/fragment@15:target:0";
		pdm_dmic = "/fragment@16:target:0";
		sound_vbc_v4_sprd_codec = "/fragment@17:target:0";
		vddldo0 = "/fragment@18:target:0";
		pmic_fgu = "/fragment@19:target:0";
		panel = "/fragment@20:target:0";
		dpu = "/fragment@21:target:0";
		pmic_fchg = "/fragment@22:target:0";
		ddr_dfs = "/fragment@24:target:0";
		pin_controller = "/fragment@25:target:0";
		ion = "/fragment@26:target:0";
		adi_bus = "/fragment@27:target:0";
		spi3 = "/fragment@28:target:0";
	};

	__local_fixups__ {

		fragment {

			__overlay__ {

				lcds {

					lcd_td4160_txd_mipi_hdp_x6525 {

						display-timings {
							native-mode = <0x00>;
						};
					};

					lcd_td4160_hx_mipi_hdp_x6525 {

						display-timings {
							native-mode = <0x00>;
						};
					};

					lcd_ft8057s_dpt_mipi_hdp_x6525 {

						display-timings {
							native-mode = <0x00>;
						};
					};

					lcd_dummy_mipi_hd {

						display-timings {
							native-mode = <0x00>;
						};
					};
				};

				charger-manager {
					monitored-battery = <0x00>;
				};

				tran_charger {
					monitored-battery = <0x00>;
				};
			};
		};

		fragment@3 {

			__overlay__ {

				pa-thmzone {
					thermal-sensors = <0x00>;
				};

				chg-thmzone {
					thermal-sensors = <0x00>;
				};

				board-thmzone {
					thermal-sensors = <0x00>;
				};
			};
		};

		fragment@9 {

			__overlay__ {
				vbus-supply = <0x00>;
			};
		};

		fragment@12 {

			__overlay__ {

				aw32257@6a {
					monitored-battery = <0x00>;
				};
			};
		};

		fragment@19 {

			__overlay__ {
				monitored-battery = <0x00>;
			};
		};

		fragment@21 {

			__overlay__ {
				sprd,logo-memory = <0x00>;
			};
		};

		fragment@25 {

			__overlay__ {
				pinctrl-0 = <0x00>;
				pinctrl-1 = <0x00>;
				pinctrl-2 = <0x00>;
				pinctrl-3 = <0x00>;
				pinctrl-4 = <0x00>;
				pinctrl-5 = <0x00>;
				pinctrl-6 = <0x00>;
			};
		};

		fragment@26 {

			__overlay__ {

				heap@4 {
					memory-region = <0x00>;
				};
			};
		};
	};
};
